VERSION ""

NS_ :

BS_:

BU_: SVB1 Tester Gateway CDS1 CDS2 ADV IRC AVP AVM PDC ADB1 ADB2 HDMAP DSM Fradar LCDA1 LCDA2

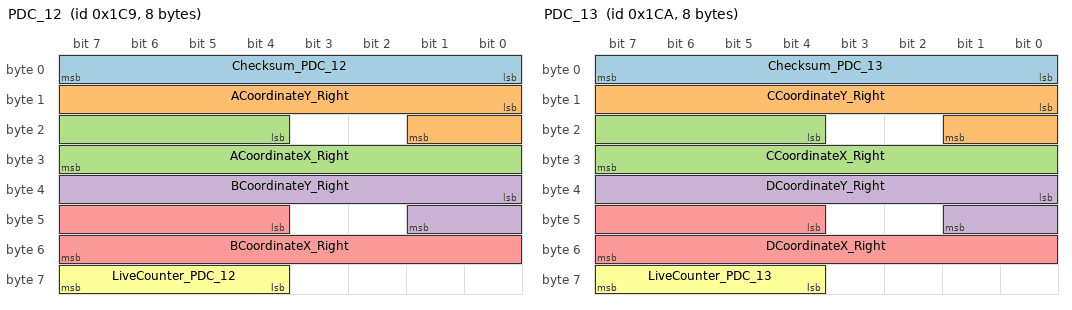
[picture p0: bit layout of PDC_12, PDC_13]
BO_ 457 PDC_12: 8 PDC
 SG_ Checksum_PDC_12 : 0|8@1+ (1,0) [0|255] ""  ADV,AVP,AVM
 SG_ ACoordinateY_Right : 8|10@1+ (1,0) [0|1023] "cm"  ADV,AVP,AVM
 SG_ ACoordinateX_Right : 20|12@1+ (1,0) [0|4095] "cm"  ADV,AVP,AVM
 SG_ BCoordinateY_Right : 32|10@1+ (1,0) [0|1023] "cm"  ADV,AVP,AVM
 SG_ BCoordinateX_Right : 44|12@1+ (1,0) [0|4095] "cm"  ADV,AVP,AVM
 SG_ LiveCounter_PDC_12 : 60|4@1+ (1,0) [0|15] "Pulse"  ADV,AVP,AVM

BO_ 458 PDC_13: 8 PDC
 SG_ Checksum_PDC_13 : 0|8@1+ (1,0) [0|255] ""  ADV,AVP,AVM
 SG_ CCoordinateY_Right : 8|10@1+ (1,0) [0|1023] "cm"  ADV,AVP,AVM
 SG_ CCoordinateX_Right : 20|12@1+ (1,0) [0|4095] "cm"  ADV,AVP,AVM
 SG_ DCoordinateY_Right : 32|10@1+ (1,0) [0|1023] "cm"  ADV,AVP,AVM
 SG_ DCoordinateX_Right : 44|12@1+ (1,0) [0|4095] "cm"  ADV,AVP,AVM
 SG_ LiveCounter_PDC_13 : 60|4@1+ (1,0) [0|15] "Pulse"  ADV,AVP,AVM

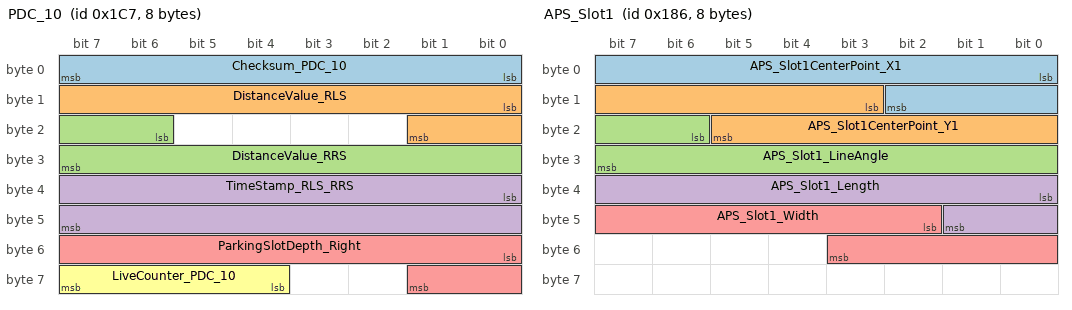
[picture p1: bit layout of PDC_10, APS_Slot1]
BO_ 455 PDC_10: 8 PDC
 SG_ Checksum_PDC_10 : 0|8@1+ (1,0) [0|255] ""  ADV,AVP,AVM
 SG_ DistanceValue_RLS : 8|10@1+ (1,0) [0|1023] "cm"  ADV,AVP,AVM
 SG_ DistanceValue_RRS : 22|10@1+ (1,0) [0|1023] "cm"  ADV,AVP,AVM
 SG_ TimeStamp_RLS_RRS : 32|16@1+ (1,0) [0|65535] "ms"  ADV,AVP,AVM
 SG_ ParkingSlotDepth_Right : 48|10@1+ (1,0) [0|1023] "cm"  AVP,AVM
 SG_ LiveCounter_PDC_10 : 60|4@1+ (1,0) [0|15] "Pulse"  ADV,AVP,AVM

BO_ 388 APS_PSD: 8 AVP
 SG_ APS_Slot1_DetectStatus : 0|2@1+ (1,0) [0|3] ""  Gateway,ADV
 SG_ APS_Slot1_Info : 2|2@1+ (1,0) [0|3] ""  Gateway,ADV
 SG_ APS_Slot1_ParkType : 4|2@1+ (1,0) [0|3] ""  Gateway,ADV
 SG_ APS_Slot1_ParkDirection : 6|1@1+ (1,0) [0|1] ""  Gateway,ADV
 SG_ APS_Slot2_DetectStatus : 8|2@1+ (1,0) [0|3] ""  Gateway,ADV
 SG_ APS_Slot2_Info : 10|2@1+ (1,0) [0|3] ""  Gateway,ADV
 SG_ APS_Slot2_ParkType : 12|2@1+ (1,0) [0|3] ""  Gateway,ADV
 SG_ APS_Slot2_ParkDirection : 14|1@1+ (1,0) [0|1] ""  Gateway,ADV
 SG_ APS_Slot3_DetectStatus : 16|2@1+ (1,0) [0|3] ""  Gateway,ADV
 SG_ APS_Slot3_Info : 18|2@1+ (1,0) [0|3] ""  Gateway,ADV
 SG_ APS_Slot3_ParkType : 20|2@1+ (1,0) [0|3] ""  Gateway,ADV
 SG_ APS_Slot3_ParkDirection : 22|1@1+ (1,0) [0|1] ""  Gateway,ADV
 SG_ APS_Slot4_DetectStatus : 24|2@1+ (1,0) [0|3] ""  Gateway,ADV
 SG_ APS_Slot4_Info : 26|2@1+ (1,0) [0|3] ""  Gateway,ADV
 SG_ APS_Slot4_ParkType : 28|2@1+ (1,0) [0|3] ""  Gateway,ADV
 SG_ APS_Slot4_ParkDirection : 30|1@1+ (1,0) [0|1] ""  Gateway,ADV
 SG_ APS_Slot5_DetectStatus : 32|2@1+ (1,0) [0|3] ""  Gateway,ADV
 SG_ APS_Slot5_Info : 34|2@1+ (1,0) [0|3] ""  Gateway,ADV
 SG_ APS_Slot5_ParkType : 36|2@1+ (1,0) [0|3] ""  Gateway,ADV
 SG_ APS_Slot5_ParkDirection : 38|1@1+ (1,0) [0|1] ""  Gateway,ADV
 SG_ APS_Slot6_DetectStatus : 40|2@1+ (1,0) [0|3] ""  Gateway,ADV
 SG_ APS_Slot6_Info : 42|2@1+ (1,0) [0|3] ""  Gateway,ADV
 SG_ APS_Slot6_ParkType : 44|2@1+ (1,0) [0|3] ""  Gateway,ADV
 SG_ APS_Slot6_ParkDirection : 46|1@1+ (1,0) [0|1] ""  Gateway,ADV
 SG_ APS_ParkingSlotAvailability : 63|1@1+ (1,0) [0|1] ""  Gateway,ADV

BO_ 390 APS_Slot1: 8 AVP
 SG_ APS_Slot1CenterPoint_X1 : 0|11@1+ (1,-1000) [-1000|1047] "cm"  Gateway,ADV
 SG_ APS_Slot1CenterPoint_Y1 : 11|11@1+ (1,-1000) [-1000|1047] "cm"  Gateway,ADV
 SG_ APS_Slot1_LineAngle : 22|10@1+ (1,0) [0|1023] "degree"  Gateway,ADV
 SG_ APS_Slot1_Length : 32|10@1+ (1,0) [0|1023] "cm"  Gateway,ADV
 SG_ APS_Slot1_Width : 42|10@1+ (1,0) [0|1023] "cm"  Gateway,ADV

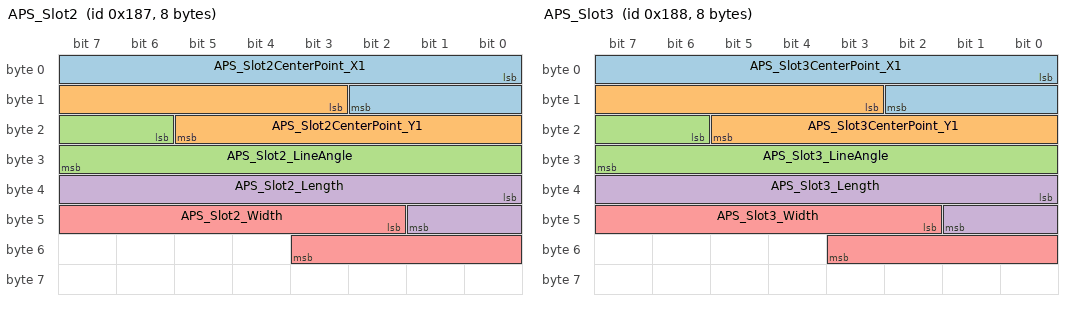
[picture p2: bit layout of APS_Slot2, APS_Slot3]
BO_ 391 APS_Slot2: 8 AVP
 SG_ APS_Slot2CenterPoint_X1 : 0|11@1+ (1,-1000) [-1000|1047] "cm"  Gateway,ADV
 SG_ APS_Slot2CenterPoint_Y1 : 11|11@1+ (1,-1000) [-1000|1047] "cm"  Gateway,ADV
 SG_ APS_Slot2_LineAngle : 22|10@1+ (1,0) [0|1023] "degree"  Gateway,ADV
 SG_ APS_Slot2_Length : 32|10@1+ (1,0) [0|1023] "cm"  Gateway,ADV
 SG_ APS_Slot2_Width : 42|10@1+ (1,0) [0|1023] "cm"  Gateway,ADV

BO_ 392 APS_Slot3: 8 AVP
 SG_ APS_Slot3CenterPoint_X1 : 0|11@1+ (1,-1000) [-1000|1047] "cm"  Gateway,ADV
 SG_ APS_Slot3CenterPoint_Y1 : 11|11@1+ (1,-1000) [-1000|1047] "cm"  Gateway,ADV
 SG_ APS_Slot3_LineAngle : 22|10@1+ (1,0) [0|1023] "degree"  Gateway,ADV
 SG_ APS_Slot3_Length : 32|10@1+ (1,0) [0|1023] "cm"  Gateway,ADV
 SG_ APS_Slot3_Width : 42|10@1+ (1,0) [0|1023] "cm"  Gateway,ADV

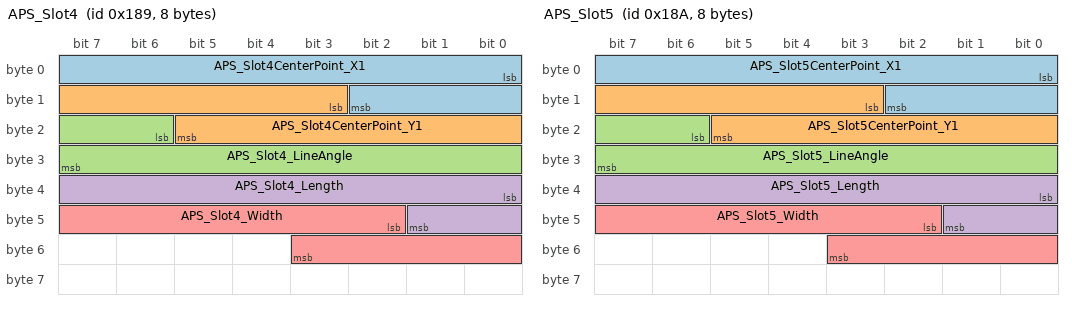
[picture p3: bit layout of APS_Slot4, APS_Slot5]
BO_ 393 APS_Slot4: 8 AVP
 SG_ APS_Slot4CenterPoint_X1 : 0|11@1+ (1,-1000) [-1000|1047] "cm"  Gateway,ADV
 SG_ APS_Slot4CenterPoint_Y1 : 11|11@1+ (1,-1000) [-1000|1047] "cm"  Gateway,ADV
 SG_ APS_Slot4_LineAngle : 22|10@1+ (1,0) [0|1023] "degree"  Gateway,ADV
 SG_ APS_Slot4_Length : 32|10@1+ (1,0) [0|1023] "cm"  Gateway,ADV
 SG_ APS_Slot4_Width : 42|10@1+ (1,0) [0|1023] "cm"  Gateway,ADV

BO_ 394 APS_Slot5: 8 AVP
 SG_ APS_Slot5CenterPoint_X1 : 0|11@1+ (1,-1000) [-1000|1047] "cm"  Gateway,ADV
 SG_ APS_Slot5CenterPoint_Y1 : 11|11@1+ (1,-1000) [-1000|1047] "cm"  Gateway,ADV
 SG_ APS_Slot5_LineAngle : 22|10@1+ (1,0) [0|1023] "degree"  Gateway,ADV
 SG_ APS_Slot5_Length : 32|10@1+ (1,0) [0|1023] "cm"  Gateway,ADV
 SG_ APS_Slot5_Width : 42|10@1+ (1,0) [0|1023] "cm"  Gateway,ADV

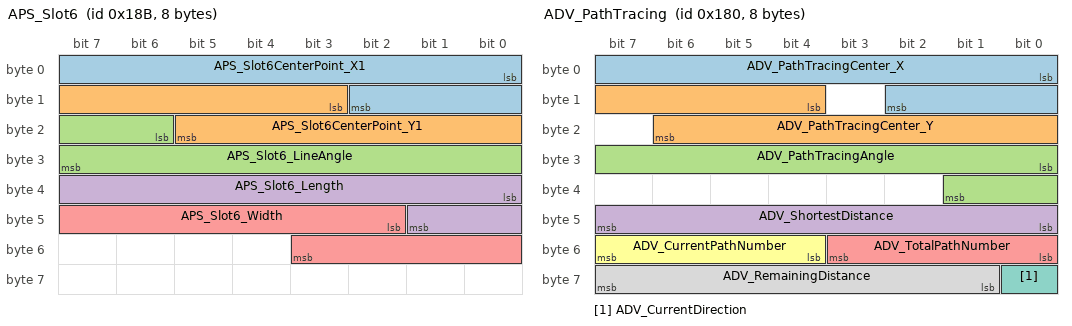
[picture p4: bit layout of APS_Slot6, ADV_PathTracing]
BO_ 395 APS_Slot6: 8 AVP
 SG_ APS_Slot6CenterPoint_X1 : 0|11@1+ (1,-1000) [-1000|1047] "cm"  Gateway,ADV
 SG_ APS_Slot6CenterPoint_Y1 : 11|11@1+ (1,-1000) [-1000|1047] "cm"  Gateway,ADV
 SG_ APS_Slot6_LineAngle : 22|10@1+ (1,0) [0|1023] "degree"  Gateway,ADV
 SG_ APS_Slot6_Length : 32|10@1+ (1,0) [0|1023] "cm"  Gateway,ADV
 SG_ APS_Slot6_Width : 42|10@1+ (1,0) [0|1023] "cm"  Gateway,ADV

BO_ 384 ADV_PathTracing: 8 CDS1
 SG_ ADV_PathTracingCenter_X : 0|11@1+ (1,-1000) [-1000|1047] "cm"  Gateway,AVP,AVM
 SG_ ADV_PathTracingCenter_Y : 12|11@1+ (1,-1000) [-1000|1047] "cm"  Gateway,AVP,AVM
 SG_ ADV_PathTracingAngle : 24|10@1+ (1,0) [0|1023] "degree"  Gateway,AVP,AVM
 SG_ ADV_ShortestDistance : 40|8@1+ (1,-126) [-126|129] "cm"  Gateway,AVP,AVM
 SG_ ADV_TotalPathNumber : 48|4@1+ (1,0) [0|15] ""  Gateway,AVP,AVM
 SG_ ADV_CurrentPathNumber : 52|4@1+ (1,0) [0|15] ""  Gateway,AVP,AVM
 SG_ ADV_CurrentDirection : 56|1@1+ (1,0) [0|1] ""  Gateway,AVP,AVM
 SG_ ADV_RemainingDistance : 57|7@1+ (1,0) [0|127] "%"  Gateway,AVP,AVM

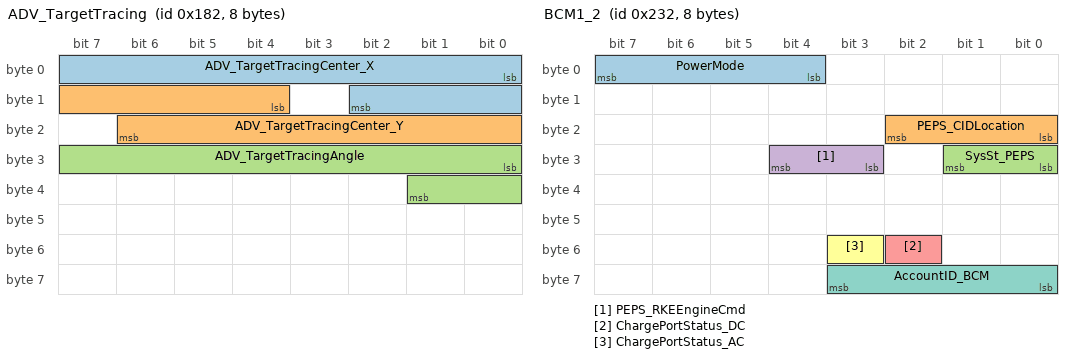
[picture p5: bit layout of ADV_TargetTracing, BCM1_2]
BO_ 386 ADV_TargetTracing: 8 CDS1
 SG_ ADV_TargetTracingCenter_X : 0|11@1+ (1,-1000) [-1000|1047] "cm"  Gateway,AVP,AVM
 SG_ ADV_TargetTracingCenter_Y : 12|11@1+ (1,-1000) [-1000|1047] "cm"  Gateway,AVP,AVM
 SG_ ADV_TargetTracingAngle : 24|10@1+ (1,0) [0|1023] "degree"  Gateway,AVP,AVM

BO_ 546 ATC_2: 8 Gateway
 SG_ AmbientTemp : 24|8@1+ (0.5,-40) [-40|87.5] "°„C"  SVB1,CDS1,CDS2,AVP,AVM,PDC

BO_ 560 BCM1_1: 8 Gateway
 SG_ PositionLightSt : 0|1@1+ (1,0) [0|1] ""  CDS2,SVB1,CDS1,ADV,IRC
 SG_ LowBeamSt : 6|1@1+ (1,0) [0|1] ""  SVB1,CDS1,CDS2,IRC,DSM
 SG_ LowBeamSt_FL : 7|1@1+ (1,0) [0|1] ""  CDS2,CDS1,SVB1,AVP,AVM,ADB1,ADB2
 SG_ LowBeamSt_FR : 8|1@1+ (1,0) [0|1] ""  CDS2,CDS1,SVB1,AVP,AVM,ADB1,ADB2
 SG_ HighBeamSt : 9|1@1+ (1,0) [0|1] ""  SVB1,CDS1,CDS2,IRC,DSM
 SG_ HighBeamSt_FL : 10|1@1+ (1,0) [0|1] ""  CDS2,CDS1,SVB1,AVP,AVM
 SG_ HighBeamSt_FR : 11|1@1+ (1,0) [0|1] ""  CDS2,CDS1,SVB1,AVP,AVM
 SG_ AutoLightMode : 12|1@1+ (1,0) [0|1] ""  SVB1,CDS1,CDS2,AVP,AVM,ADB1,ADB2
 SG_ TurningSt_Left : 16|1@1+ (1,0) [0|1] ""  SVB1,CDS1,CDS2,ADV,IRC,AVP,AVM,LCDA1,LCDA2
 SG_ TurningSt_right : 17|1@1+ (1,0) [0|1] ""  SVB1,CDS1,CDS2,ADV,IRC,AVP,AVM,LCDA1,LCDA2
 SG_ TurningLightCmd_Left : 18|1@1+ (1,0) [0|1] ""  CDS2,SVB1,CDS1,IRC,DSM
 SG_ TurningLightCmd_Right : 19|1@1+ (1,0) [0|1] ""  CDS2,SVB1,CDS1,IRC,DSM
 SG_ HazardWarningSt : 22|1@1+ (1,0) [0|1] ""  SVB1,CDS1,CDS2,ADV,AVP,AVM,DSM
 SG_ WMMFaultSt : 33|1@1+ (1,0) [0|1] ""  SVB1,CDS1,CDS2
 SG_ RLSFalutSt : 34|1@1+ (1,0) [0|1] ""  SVB1,CDS1,CDS2,ADB1,ADB2
 SG_ WiperSt_Front : 37|3@1+ (1,0) [0|7] ""  SVB1,CDS1,CDS2,IRC
 SG_ WiperSpeed_Front : 40|3@1+ (1,0) [0|7] ""  SVB1,CDS1,CDS2
 SG_ IHCConditionReady : 60|1@1+ (1,0) [0|1] ""  CDS1,SVB1,CDS2

BO_ 562 BCM1_2: 8 Gateway
 SG_ PowerMode : 4|4@1+ (1,0) [0|15] ""  SVB1,CDS1,CDS2,ADV,IRC,AVP,AVM,PDC,ADB1,ADB2,HDMAP,DSM,LCDA1,LCDA2
 SG_ PEPS_CIDLocation : 16|3@1+ (1,0) [0|7] ""  CDS2,SVB1,CDS1,ADV
 SG_ SysSt_PEPS : 24|2@1+ (1,0) [0|3] ""  CDS2,SVB1,CDS1,ADV
 SG_ PEPS_RKEEngineCmd : 27|2@1+ (1,0) [0|3] ""  CDS2,SVB1,CDS1,ADV
 SG_ ChargePortStatus_DC : 50|1@1+ (1,0) [0|1] ""  CDS2,SVB1,CDS1,ADV
 SG_ ChargePortStatus_AC : 51|1@1+ (1,0) [0|1] ""  CDS2,SVB1,CDS1,ADV
 SG_ AccountID_BCM : 56|4@1+ (1,0) [0|15] ""  CDS2,SVB1,CDS1,ADV

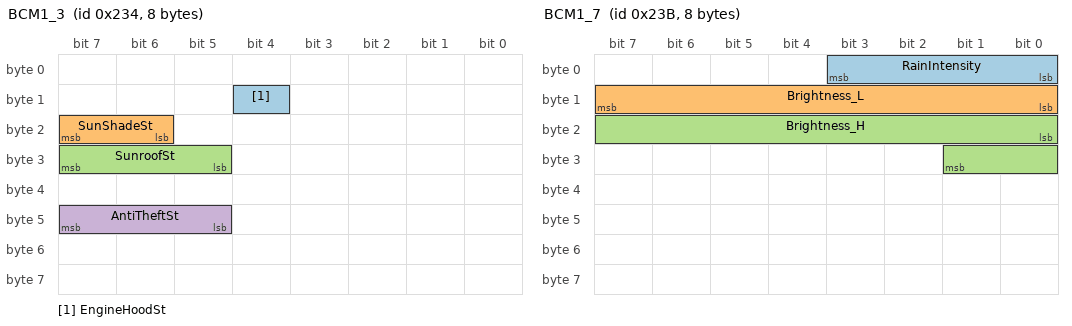
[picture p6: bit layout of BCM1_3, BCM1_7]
BO_ 564 BCM1_3: 8 Gateway
 SG_ EngineHoodSt : 12|1@1+ (1,0) [0|1] ""  SVB1,CDS1,CDS2,ADV,AVP,AVM
 SG_ SunShadeSt : 22|2@1+ (1,0) [0|3] ""  CDS2,CDS1,SVB1
 SG_ SunroofSt : 29|3@1+ (1,0) [0|7] ""  CDS2,SVB1,CDS1,ADV
 SG_ AntiTheftSt : 45|3@1+ (1,0) [0|7] ""  CDS2,SVB1,CDS1,LCDA1,LCDA2

BO_ 571 BCM1_7: 8 Gateway
 SG_ RainIntensity : 0|4@1+ (10,0) [0|150] "%"  SVB1,CDS1,CDS2,IRC,AVP,AVM,ADB1,ADB2
 SG_ Brightness_L : 8|8@1+ (400,0) [0|102000] "LUX"  SVB1,CDS1,CDS2,IRC,AVP,AVM,ADB1,ADB2
 SG_ Brightness_H : 16|10@1+ (6,0) [0|6138] "LUX"  SVB1,CDS1,CDS2,IRC,AVP,AVM,ADB1,ADB2

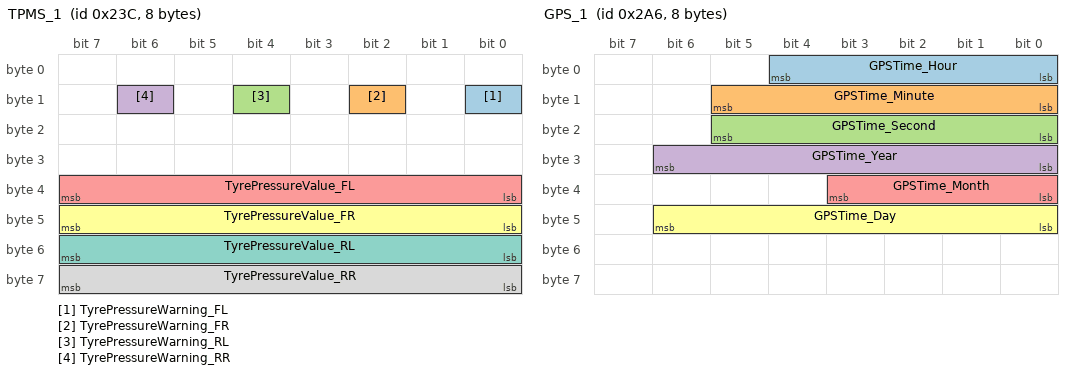
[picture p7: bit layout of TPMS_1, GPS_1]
BO_ 572 TPMS_1: 8 Gateway
 SG_ TyrePressureWarning_FL : 8|1@1+ (1,0) [0|1] ""  SVB1,CDS1,CDS2,ADV
 SG_ TyrePressureWarning_FR : 10|1@1+ (1,0) [0|1] ""  SVB1,CDS1,CDS2,ADV
 SG_ TyrePressureWarning_RL : 12|1@1+ (1,0) [0|1] ""  SVB1,CDS1,CDS2,ADV
 SG_ TyrePressureWarning_RR : 14|1@1+ (1,0) [0|1] ""  SVB1,CDS1,CDS2,ADV
 SG_ TyrePressureValue_FL : 32|8@1+ (2.75,0) [0|701.25] "kpa"  SVB1,CDS1,CDS2,ADV
 SG_ TyrePressureValue_FR : 40|8@1+ (2.75,0) [0|701.25] "kpa"  SVB1,CDS1,CDS2,ADV
 SG_ TyrePressureValue_RL : 48|8@1+ (2.75,0) [0|701.25] "kpa"  SVB1,CDS1,CDS2,ADV
 SG_ TyrePressureValue_RR : 56|8@1+ (2.75,0) [0|701.25] "kpa"  SVB1,CDS1,CDS2,ADV

BO_ 678 GPS_1: 8 Gateway
 SG_ GPSTime_Hour : 0|5@1+ (1,0) [0|31] "hour"  SVB1,CDS1,CDS2,ADV,AVP,AVM
 SG_ GPSTime_Minute : 8|6@1+ (1,0) [0|63] "minute"  SVB1,CDS1,CDS2,ADV,AVP,AVM
 SG_ GPSTime_Second : 16|6@1+ (1,0) [0|63] "minute"  SVB1,CDS1,CDS2,ADV,AVP,AVM
 SG_ GPSTime_Year : 24|7@1+ (1,2011) [2011|2138] "year"  SVB1,CDS1,CDS2,ADV,AVP,AVM
 SG_ GPSTime_Month : 32|4@1+ (1,1) [1|16] "month"  SVB1,CDS1,CDS2,ADV,AVP,AVM
 SG_ GPSTime_Day : 40|7@1+ (1,1) [1|128] "day"  SVB1,CDS1,CDS2,ADV,AVP,AVM

BO_ 691 GW_DataRecord: 8 Gateway
 SG_ GW_AutoDriveDataRecordStatus : 11|2@1+ (1,0) [0|3] ""  SVB1,CDS2,CDS1
 SG_ GW_AutoDriveDataRecordAvailable : 13|1@1+ (1,0) [0|1] ""  SVB1,CDS2,CDS1

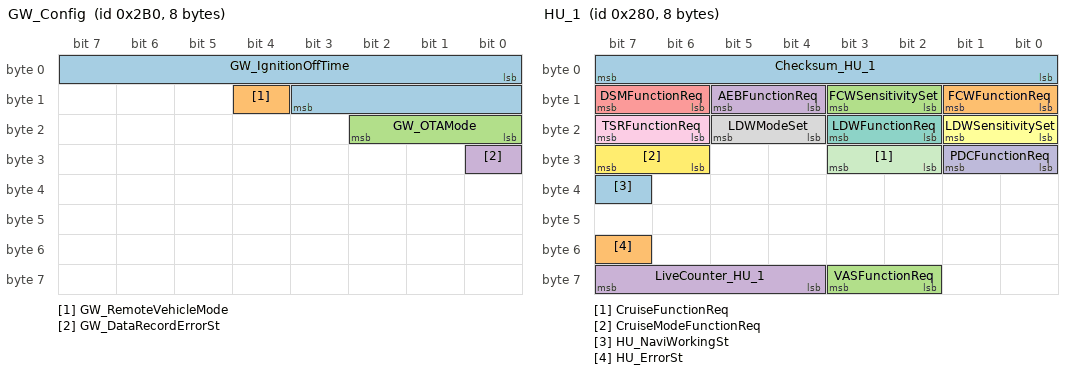
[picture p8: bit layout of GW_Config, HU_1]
BO_ 688 GW_Config: 8 Gateway
 SG_ GW_IgnitionOffTime : 0|12@1+ (1,0) [0|4095] "minute"  CDS2,CDS1,SVB1
 SG_ GW_RemoteVehicleMode : 12|1@1+ (1,0) [0|1] ""  SVB1,CDS1,CDS2,ADV,IRC,AVP,AVM,PDC,HDMAP,DSM
 SG_ GW_OTAMode : 16|3@1+ (1,0) [0|7] ""  SVB1,CDS1,CDS2,ADV,IRC,AVP,AVM,PDC,ADB1,ADB2,HDMAP,DSM,Fradar,LCDA1,LCDA2
 SG_ GW_DataRecordErrorSt : 24|1@1+ (1,0) [0|1] ""  CDS2,SVB1,CDS1

BO_ 640 HU_1: 8 Gateway
 SG_ Checksum_HU_1 : 0|8@1+ (1,0) [0|255] "Pulse"  SVB1,CDS1,CDS2,PDC,DSM
 SG_ FCWFunctionReq : 8|2@1+ (1,0) [0|3] ""  SVB1,CDS1,CDS2
 SG_ FCWSensitivitySet : 10|2@1+ (1,0) [0|3] ""  SVB1,CDS1,CDS2
 SG_ AEBFunctionReq : 12|2@1+ (1,0) [0|3] ""  SVB1,CDS1,CDS2
 SG_ DSMFunctionReq : 14|2@1+ (1,0) [0|3] ""  CDS1,SVB1,CDS2,DSM
 SG_ LDWSensitivitySet : 16|2@1+ (1,0) [0|3] ""  SVB1,CDS1,CDS2
 SG_ LDWFunctionReq : 18|2@1+ (1,0) [0|3] ""  SVB1,CDS1,CDS2
 SG_ LDWModeSet : 20|2@1+ (1,0) [0|3] ""  SVB1,CDS1,CDS2
 SG_ TSRFunctionReq : 22|2@1+ (1,0) [0|3] ""  SVB1,CDS1,CDS2
 SG_ PDCFunctionReq : 24|2@1+ (1,0) [0|3] ""  CDS2,CDS1,SVB1,PDC
 SG_ CruiseFunctionReq : 26|2@1+ (1,0) [0|3] ""  SVB1,CDS1,CDS2
 SG_ CruiseModeFunctionReq : 30|2@1+ (1,0) [0|3] ""  SVB1,CDS1,CDS2
 SG_ HU_NaviWorkingSt : 39|1@1+ (1,0) [0|1] ""  CDS2,SVB1,CDS1
 SG_ HU_ErrorSt : 55|1@1+ (1,0) [0|1] ""  CDS2,SVB1,CDS1
 SG_ VASFunctionReq : 58|2@1+ (1,0) [0|3] ""  SVB1,CDS1,CDS2
 SG_ LiveCounter_HU_1 : 60|4@1+ (1,0) [0|15] ""  SVB1,CDS1,CDS2,PDC,DSM

BO_ 643 HU_18: 8 Gateway
 SG_ Checksum_HU_18 : 0|8@1+ (1,0) [0|255] "Pulse"  ADV,AVP,AVM,PDC,DSM
 SG_ HU_BlindSpotFilledFunctionReq : 8|2@1+ (1,0) [0|3] ""  AVP,AVM
 SG_ HU_BacktrackFunctionReq : 10|2@1+ (1,0) [0|3] ""  ADV
 SG_ HU_ParkingAEBFunctionReq : 12|2@1+ (1,0) [0|3] "" Vector__XXX
 SG_ HU_ADVDisclaimerTipConfirm : 14|2@1+ (1,0) [0|3] "" Vector__XXX
 SG_ HU_APASuspendRequest : 16|2@1+ (1,0) [0|3] ""  ADV
 SG_ HU_PDCAutoOnFunctionReq : 18|2@1+ (1,0) [0|3] ""  PDC
 SG_ HU_FaceID_IVI : 20|4@1+ (1,0) [0|15] ""  DSM
 SG_ FaceIDBindFaceReq : 24|2@1+ (1,0) [0|3] ""  DSM
 SG_ HU_AVPSuspendRequest : 26|2@1+ (1,0) [0|3] "" Vector__XXX
 SG_ HU_HPASuspendRequest : 28|2@1+ (1,0) [0|3] "" Vector__XXX
 SG_ HU_AVPParkingLotPushFunctionReq : 30|2@1+ (1,0) [0|3] "" Vector__XXX
 SG_ HU_HPAFunctionReq : 32|2@1+ (1,0) [0|3] "" Vector__XXX
 SG_ HU_AVPHazardWarningFunctionReq : 34|2@1+ (1,0) [0|3] "" Vector__XXX
 SG_ HU_HPAHazardWarningFunctionReq : 36|2@1+ (1,0) [0|3] "" Vector__XXX
 SG_ HU_AVPTypeReq : 38|2@1+ (1,0) [0|3] "" Vector__XXX
 SG_ HU_AVPSearchingTypeReq : 40|2@1+ (1,0) [0|3] "" Vector__XXX
 SG_ HU_HPATypeReq : 42|2@1+ (1,0) [0|3] "" Vector__XXX
 SG_ HU_HPASearchingTypeReq : 44|2@1+ (1,0) [0|3] "" Vector__XXX
 SG_ HU_HPAParkingLotPushFunctionReq : 46|2@1+ (1,0) [0|3] "" Vector__XXX
 SG_ HU_AVPFunctionTipConfirm : 48|2@1+ (1,0) [0|3] "" Vector__XXX
 SG_ HU_HPAFunctionTipConfirm : 50|2@1+ (1,0) [0|3] "" Vector__XXX
 SG_ HU_AVPFunctionCancelReq : 52|1@1+ (1,0) [0|1] "" Vector__XXX
 SG_ HU_HPAFunctionCancelReq : 53|1@1+ (1,0) [0|1] "" Vector__XXX
 SG_ HU_AutoDrivingStyle_Set : 56|3@1+ (1,0) [0|7] "" Vector__XXX
 SG_ LiveCounter_HU_18 : 60|4@1+ (1,0) [0|15] "pulse"  ADV,AVP,AVM,PDC,DSM

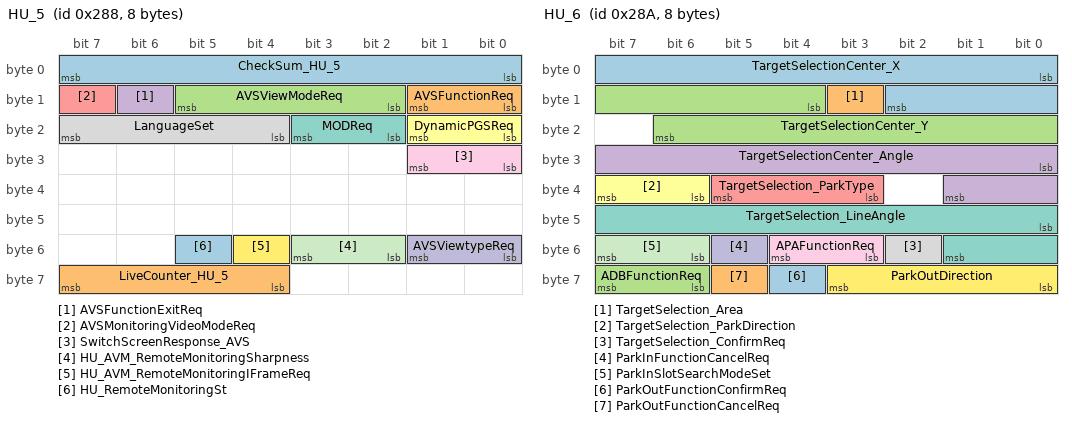
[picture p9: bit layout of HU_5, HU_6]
BO_ 648 HU_5: 8 Gateway
 SG_ CheckSum_HU_5 : 0|8@1+ (1,0) [0|255] ""  AVP,AVM
 SG_ AVSFunctionReq : 8|2@1+ (1,0) [0|3] ""  AVP,AVM
 SG_ AVSViewModeReq : 10|4@1+ (1,0) [0|15] ""  AVP,AVM
 SG_ AVSFunctionExitReq : 14|1@1+ (1,0) [0|1] ""  AVP,AVM
 SG_ AVSMonitoringVideoModeReq : 15|1@1+ (1,0) [0|1] ""  AVP,AVM
 SG_ DynamicPGSReq : 16|2@1+ (1,0) [0|3] ""  AVP,AVM
 SG_ MODReq : 18|2@1+ (1,0) [0|3] ""  AVP,AVM
 SG_ LanguageSet : 20|4@1+ (1,0) [0|15] ""  AVP,AVM
 SG_ SwitchScreenResponse_AVS : 24|2@1+ (1,0) [0|3] ""  AVP,AVM
 SG_ AVSViewtypeReq : 48|2@1+ (1,0) [0|3] ""  AVP,AVM
 SG_ HU_AVM_RemoteMonitoringSharpness : 50|2@1+ (1,0) [0|3] ""  AVP,AVM
 SG_ HU_AVM_RemoteMonitoringIFrameReq : 52|1@1+ (1,0) [0|1] ""  AVP,AVM
 SG_ HU_RemoteMonitoringSt : 53|1@1+ (1,0) [0|1] ""  AVP,AVM
 SG_ LiveCounter_HU_5 : 60|4@1+ (1,0) [0|15] "pulse"  AVP,AVM

BO_ 650 HU_6: 8 Gateway
 SG_ TargetSelectionCenter_X : 0|11@1+ (1,-1000) [-1000|1047] "cm"  ADV,AVP,AVM
 SG_ TargetSelection_Area : 11|1@1+ (1,0) [0|1] ""  ADV,AVP,AVM
 SG_ TargetSelectionCenter_Y : 12|11@1+ (1,-1000) [-1000|1047] "cm"  ADV,AVP,AVM
 SG_ TargetSelectionCenter_Angle : 24|10@1+ (1,0) [0|1023] "degree"  ADV,AVP,AVM
 SG_ TargetSelection_ParkType : 35|3@1+ (1,0) [0|7] ""  ADV,AVP,AVM
 SG_ TargetSelection_ParkDirection : 38|2@1+ (1,0) [0|3] ""  ADV,AVP,AVM
 SG_ TargetSelection_LineAngle : 40|10@1+ (1,0) [0|1023] "degree"  ADV,AVP,AVM
 SG_ TargetSelection_ConfirmReq : 50|1@1+ (1,0) [0|1] ""  ADV,AVP,AVM
 SG_ APAFunctionReq : 51|2@1+ (1,0) [0|3] ""  ADV
 SG_ ParkInFunctionCancelReq : 53|1@1+ (1,0) [0|1] ""  ADV
 SG_ ParkInSlotSearchModeSet : 54|2@1+ (1,0) [0|3] ""  ADV,AVP,AVM
 SG_ ParkOutDirection : 56|4@1+ (1,0) [0|15] ""  ADV,AVP,AVM
 SG_ ParkOutFunctionConfirmReq : 60|1@1+ (1,0) [0|1] ""  ADV
 SG_ ParkOutFunctionCancelReq : 61|1@1+ (1,0) [0|1] ""  ADV
 SG_ ADBFunctionReq : 62|2@1+ (1,0) [0|3] ""  ADB1,ADB2

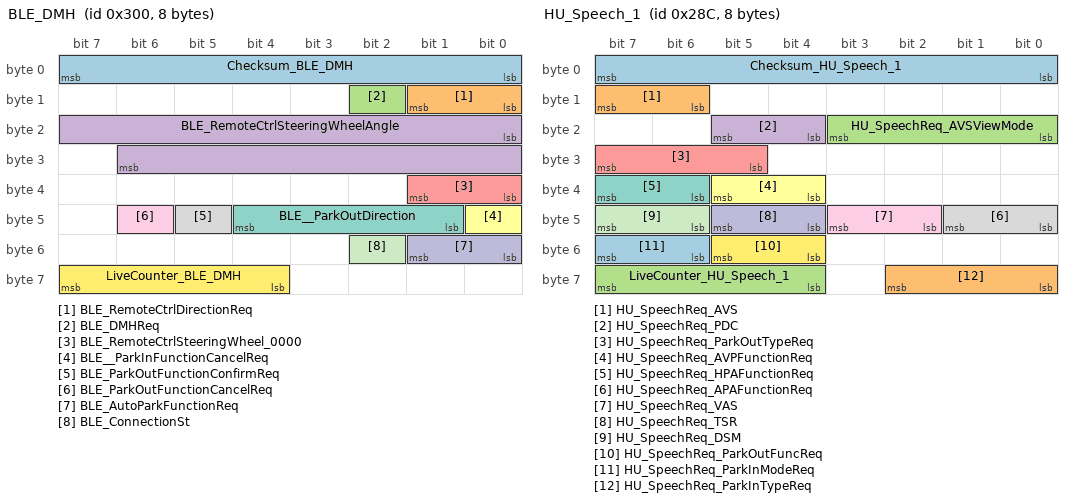
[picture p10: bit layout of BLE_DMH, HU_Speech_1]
BO_ 768 BLE_DMH: 8 Gateway
 SG_ Checksum_BLE_DMH : 0|8@1+ (1,0) [0|255] ""  ADV
 SG_ BLE_RemoteCtrlDirectionReq : 8|2@1+ (1,0) [0|3] ""  ADV
 SG_ BLE_DMHReq : 10|1@1+ (1,0) [0|1] ""  ADV
 SG_ BLE_RemoteCtrlSteeringWheelAngle : 16|15@1+ (0.04375,0) [0|1433.55625] "°„"  ADV
 SG_ BLE_RemoteCtrlSteeringWheel_0000 : 32|2@1+ (1,0) [0|3] ""  ADV
 SG_ BLE__ParkInFunctionCancelReq : 40|1@1+ (1,0) [0|1] ""  ADV
 SG_ BLE__ParkOutDirection : 41|4@1+ (1,0) [0|15] ""  ADV
 SG_ BLE_ParkOutFunctionConfirmReq : 45|1@1+ (1,0) [0|1] ""  ADV
 SG_ BLE_ParkOutFunctionCancelReq : 46|1@1+ (1,0) [0|1] ""  ADV
 SG_ BLE_AutoParkFunctionReq : 48|2@1+ (1,0) [0|3] ""  ADV
 SG_ BLE_ConnectionSt : 50|1@1+ (1,0) [0|1] ""  ADV
 SG_ LiveCounter_BLE_DMH : 60|4@1+ (1,0) [0|15] ""  ADV

BO_ 652 HU_Speech_1: 8 Gateway
 SG_ Checksum_HU_Speech_1 : 0|8@1+ (1,0) [0|255] ""  ADV,AVP,AVM,PDC
 SG_ HU_SpeechReq_AVS : 14|2@1+ (1,0) [0|3] ""  AVP,AVM
 SG_ HU_SpeechReq_AVSViewMode : 16|4@1+ (1,0) [0|15] ""  AVP,AVM
 SG_ HU_SpeechReq_PDC : 20|2@1+ (1,0) [0|3] ""  PDC
 SG_ HU_SpeechReq_ParkOutTypeReq : 29|3@1+ (1,0) [0|7] ""  ADV
 SG_ HU_SpeechReq_AVPFunctionReq : 36|2@1+ (1,0) [0|3] "" Vector__XXX
 SG_ HU_SpeechReq_HPAFunctionReq : 38|2@1+ (1,0) [0|3] "" Vector__XXX
 SG_ HU_SpeechReq_APAFunctionReq : 40|2@1+ (1,0) [0|3] ""  ADV
 SG_ HU_SpeechReq_VAS : 42|2@1+ (1,0) [0|3] "" Vector__XXX
 SG_ HU_SpeechReq_TSR : 44|2@1+ (1,0) [0|3] "" Vector__XXX
 SG_ HU_SpeechReq_DSM : 46|2@1+ (1,0) [0|3] ""  DSM
 SG_ HU_SpeechReq_ParkOutFuncReq : 52|2@1+ (1,0) [0|3] ""  ADV
 SG_ HU_SpeechReq_ParkInModeReq : 54|2@1+ (1,0) [0|3] ""  ADV
 SG_ HU_SpeechReq_ParkInTypeReq : 56|3@1+ (1,0) [0|7] ""  ADV
 SG_ LiveCounter_HU_Speech_1 : 60|4@1+ (1,0) [0|15] "Pulse"  ADV,AVP,AVM,PDC

BO_ 656 IC_1: 8 Gateway
 SG_ IndicationSpeed_IC : 8|8@1+ (1,0) [0|255] "km/h"  SVB1,CDS1,CDS2
 SG_ OdometerValue : 24|25@1+ (0.1,0) [0|3355443.1] "km"  SVB1,CDS1,CDS2,ADV,IRC,AVP,AVM,PDC,ADB1,ADB2,HDMAP,DSM,Fradar,LCDA1,LCDA2

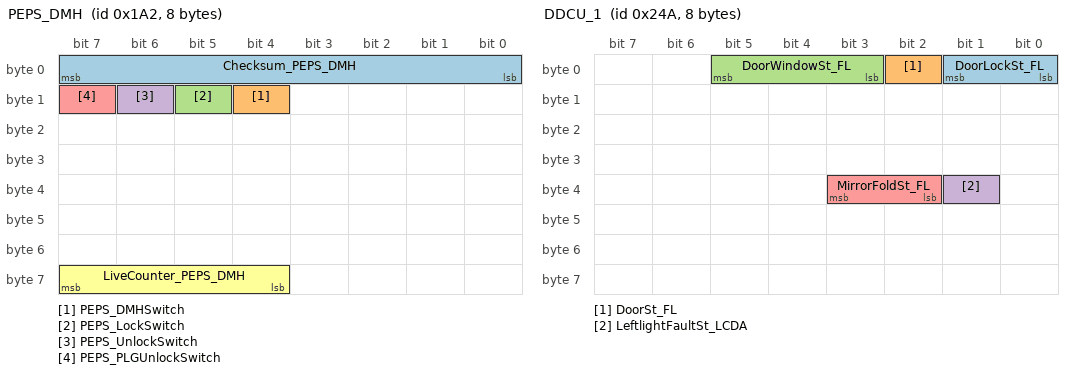
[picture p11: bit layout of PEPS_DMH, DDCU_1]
BO_ 418 PEPS_DMH: 8 Gateway
 SG_ Checksum_PEPS_DMH : 0|8@1+ (1,0) [0|255] ""  SVB1,CDS2,CDS1,ADV
 SG_ PEPS_DMHSwitch : 12|1@1+ (1,0) [0|1] ""  SVB1,CDS2,CDS1,ADV
 SG_ PEPS_LockSwitch : 13|1@1+ (1,0) [0|1] ""  SVB1,CDS2,CDS1,ADV
 SG_ PEPS_UnlockSwitch : 14|1@1+ (1,0) [0|1] ""  SVB1,CDS2,CDS1,ADV
 SG_ PEPS_PLGUnlockSwitch : 15|1@1+ (1,0) [0|1] ""  SVB1,CDS2,CDS1,ADV
 SG_ LiveCounter_PEPS_DMH : 60|4@1+ (1,0) [0|15] ""  SVB1,CDS2,CDS1,ADV

BO_ 578 PLG_1: 8 Gateway
 SG_ LuggageDoorSt : 0|1@1+ (1,0) [0|1] ""  SVB1,CDS2,CDS1,ADV,IRC,AVP,AVM

BO_ 586 DDCU_1: 8 Gateway
 SG_ DoorLockSt_FL : 0|2@1+ (1,0) [0|3] ""  CDS2,SVB1,CDS1,ADV,LCDA2
 SG_ DoorSt_FL : 2|1@1+ (1,0) [0|1] ""  SVB1,CDS1,CDS2,ADV,AVP,AVM,LCDA2
 SG_ DoorWindowSt_FL : 3|3@1+ (1,0) [0|7] ""  CDS2,SVB1,CDS1,ADV
 SG_ LeftlightFaultSt_LCDA : 33|1@1+ (1,0) [0|1] ""  CDS1,CDS2,SVB1,LCDA2
 SG_ MirrorFoldSt_FL : 34|2@1+ (1,0) [0|3] ""  CDS2,SVB1,CDS1,ADV,AVP,AVM

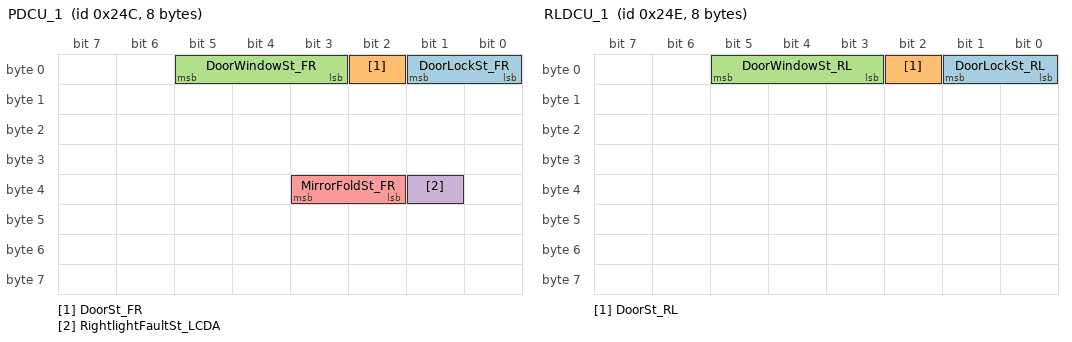
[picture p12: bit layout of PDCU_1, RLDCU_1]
BO_ 588 PDCU_1: 8 Gateway
 SG_ DoorLockSt_FR : 0|2@1+ (1,0) [0|3] ""  CDS2,SVB1,CDS1,ADV,LCDA1
 SG_ DoorSt_FR : 2|1@1+ (1,0) [0|1] ""  SVB1,CDS1,CDS2,ADV,AVP,AVM,LCDA1
 SG_ DoorWindowSt_FR : 3|3@1+ (1,0) [0|7] ""  CDS2,SVB1,CDS1,ADV
 SG_ RightlightFaultSt_LCDA : 33|1@1+ (1,0) [0|1] ""  CDS2,CDS1,SVB1,LCDA1
 SG_ MirrorFoldSt_FR : 34|2@1+ (1,0) [0|3] ""  CDS2,SVB1,CDS1,ADV,AVP,AVM

BO_ 590 RLDCU_1: 8 Gateway
 SG_ DoorLockSt_RL : 0|2@1+ (1,0) [0|3] ""  CDS2,SVB1,CDS1,ADV,LCDA2
 SG_ DoorSt_RL : 2|1@1+ (1,0) [0|1] ""  SVB1,CDS1,CDS2,ADV,AVP,AVM,LCDA2
 SG_ DoorWindowSt_RL : 3|3@1+ (1,0) [0|7] ""  CDS2,SVB1,CDS1,ADV

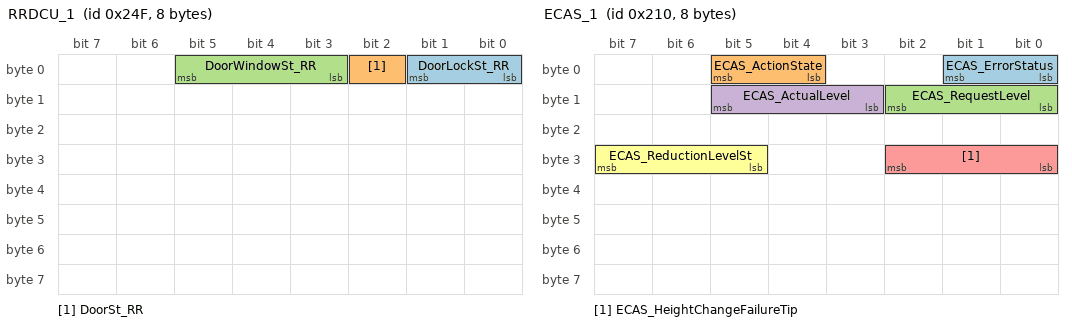
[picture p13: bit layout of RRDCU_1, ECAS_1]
BO_ 591 RRDCU_1: 8 Gateway
 SG_ DoorLockSt_RR : 0|2@1+ (1,0) [0|3] ""  CDS2,SVB1,CDS1,ADV,LCDA1
 SG_ DoorSt_RR : 2|1@1+ (1,0) [0|1] ""  SVB1,CDS1,CDS2,ADV,AVP,AVM,LCDA1
 SG_ DoorWindowSt_RR : 3|3@1+ (1,0) [0|7] ""  CDS2,SVB1,CDS1,ADV

BO_ 528 ECAS_1: 8 Gateway
 SG_ ECAS_ErrorStatus : 0|2@1+ (1,0) [0|3] ""  ADV
 SG_ ECAS_ActionState : 4|2@1+ (1,0) [0|3] ""  ADV,AVP,AVM
 SG_ ECAS_RequestLevel : 8|3@1+ (1,0) [0|7] ""  ADV
 SG_ ECAS_ActualLevel : 11|3@1+ (1,0) [0|7] ""  ADV,AVP,AVM
 SG_ ECAS_HeightChangeFailureTip : 24|3@1+ (1,0) [0|7] ""  ADV
 SG_ ECAS_ReductionLevelSt : 29|3@1+ (1,0) [0|7] ""  ADV

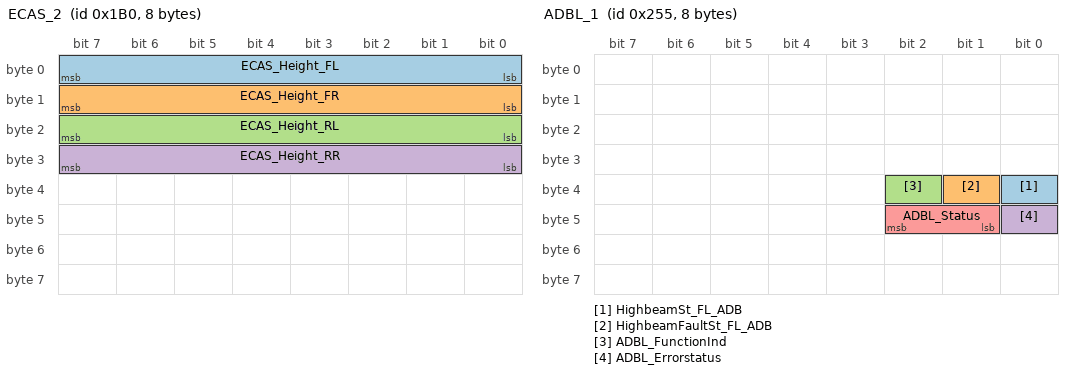
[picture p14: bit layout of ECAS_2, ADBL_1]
BO_ 432 ECAS_2: 8 Gateway
 SG_ ECAS_Height_FL : 0|8@1+ (1,-127) [-127|128] "mm"  ADV,AVP,AVM,PDC
 SG_ ECAS_Height_FR : 8|8@1+ (1,-127) [-127|128] "mm"  ADV,AVP,AVM,PDC
 SG_ ECAS_Height_RL : 16|8@1+ (1,-127) [-127|128] "mm"  ADV,AVP,AVM,PDC
 SG_ ECAS_Height_RR : 24|8@1+ (1,-127) [-127|128] "mm"  ADV,AVP,AVM,PDC

BO_ 529 ECAS_4: 8 Gateway
 SG_ AxleLoad_Front : 0|12@1+ (1,800) [800|4895] "kg" Vector__XXX
 SG_ AxleLoad_Rear : 12|12@1+ (1,800) [800|4895] "kg" Vector__XXX

BO_ 597 ADBL_1: 8 ADB1
 SG_ HighbeamSt_FL_ADB : 32|1@1+ (1,0) [0|1] ""  Gateway
 SG_ HighbeamFaultSt_FL_ADB : 33|1@1+ (1,0) [0|1] ""  Gateway
 SG_ ADBL_FunctionInd : 34|1@1+ (1,0) [0|1] ""  Gateway
 SG_ ADBL_Errorstatus : 40|1@1+ (1,0) [0|1] ""  Gateway,ADB2
 SG_ ADBL_Status : 41|2@1+ (1,0) [0|3] ""  Gateway

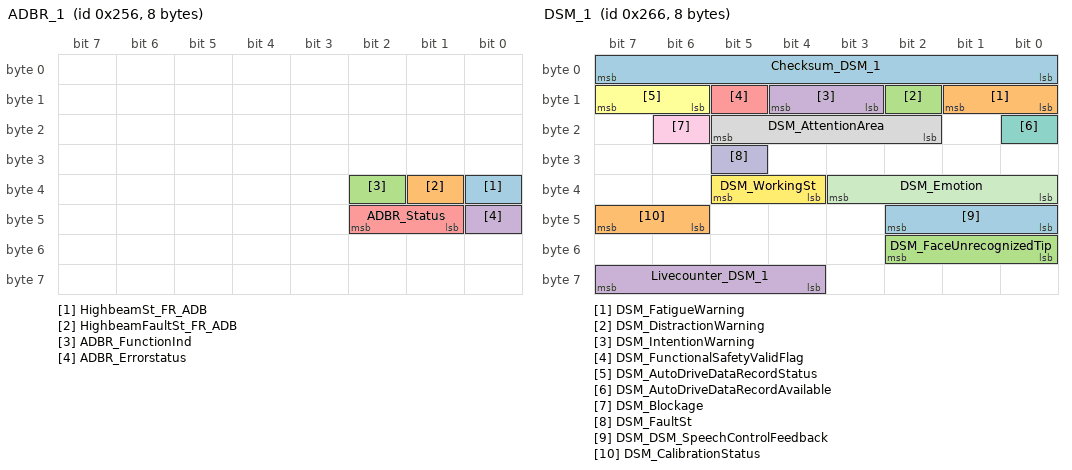
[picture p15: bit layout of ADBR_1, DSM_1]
BO_ 598 ADBR_1: 8 ADB2
 SG_ HighbeamSt_FR_ADB : 32|1@1+ (1,0) [0|1] "" Vector__XXX
 SG_ HighbeamFaultSt_FR_ADB : 33|1@1+ (1,0) [0|1] ""  Gateway
 SG_ ADBR_FunctionInd : 34|1@1+ (1,0) [0|1] ""  Gateway
 SG_ ADBR_Errorstatus : 40|1@1+ (1,0) [0|1] ""  Gateway,ADB1
 SG_ ADBR_Status : 41|2@1+ (1,0) [0|3] ""  Gateway

BO_ 539 MAP_1: 8 HDMAP
 SG_ HDMAP_Status : 32|2@1+ (1,0) [0|3] ""  AVP

BO_ 614 DSM_1: 8 DSM
 SG_ Checksum_DSM_1 : 0|8@1+ (1,0) [0|255] ""  SVB1,CDS2,Gateway,CDS1
 SG_ DSM_FatigueWarning : 8|2@1+ (1,0) [0|3] ""  SVB1,CDS2,Gateway,CDS1
 SG_ DSM_DistractionWarning : 10|1@1+ (1,0) [0|1] ""  SVB1,CDS2,Gateway,CDS1
 SG_ DSM_IntentionWarning : 11|2@1+ (1,0) [0|3] ""  SVB1,CDS2,Gateway,CDS1
 SG_ DSM_FunctionalSafetyValidFlag : 13|1@1+ (1,0) [0|1] ""  SVB1,CDS2,CDS1
 SG_ DSM_AutoDriveDataRecordStatus : 14|2@1+ (1,0) [0|3] ""  SVB1,CDS2,Gateway,CDS1
 SG_ DSM_AutoDriveDataRecordAvailable : 16|1@1+ (1,0) [0|1] ""  SVB1,CDS2,Gateway,CDS1
 SG_ DSM_AttentionArea : 18|4@1+ (1,0) [0|15] ""  SVB1,CDS2,CDS1
 SG_ DSM_Blockage : 22|1@1+ (1,0) [0|1] ""  SVB1,CDS2,Gateway,CDS1
 SG_ DSM_FaultSt : 29|1@1+ (1,0) [0|1] ""  SVB1,CDS2,Gateway,CDS1
 SG_ DSM_Emotion : 32|4@1+ (1,0) [0|15] ""  SVB1,CDS2,Gateway,CDS1
 SG_ DSM_WorkingSt : 36|2@1+ (1,0) [0|3] ""  SVB1,CDS2,CDS1,Gateway
 SG_ DSM_DSM_SpeechControlFeedback : 40|3@1+ (1,0) [0|7] ""  SVB1,CDS2,CDS1,Gateway
 SG_ DSM_CalibrationStatus : 46|2@1+ (1,0) [0|3] ""  SVB1,CDS2,CDS1,Gateway
 SG_ DSM_FaceUnrecognizedTip : 48|3@1+ (1,0) [0|7] ""  SVB1,CDS2,Gateway,CDS1
 SG_ Livecounter_DSM_1 : 60|4@1+ (1,0) [0|15] ""  SVB1,CDS2,Gateway,CDS1

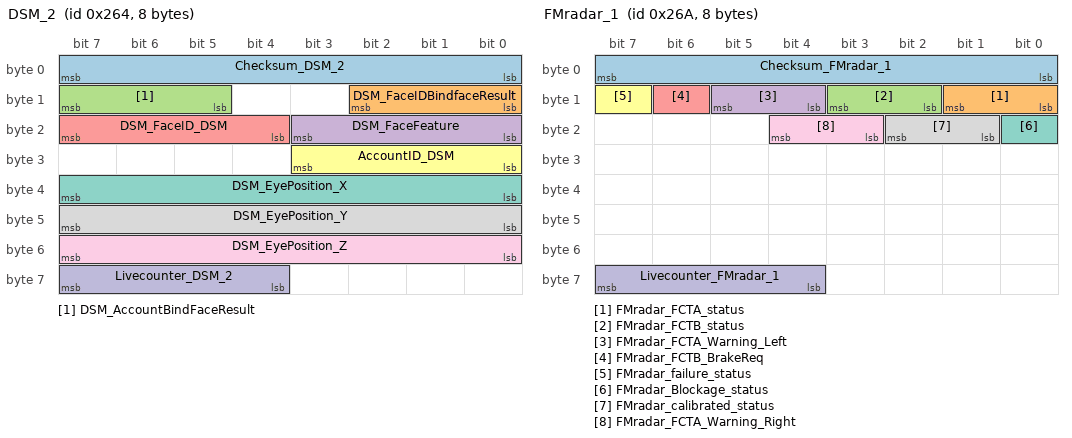
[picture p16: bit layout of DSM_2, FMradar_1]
BO_ 612 DSM_2: 8 DSM
 SG_ Checksum_DSM_2 : 0|8@1+ (1,0) [0|255] ""  SVB1,CDS2,CDS1,Gateway
 SG_ DSM_FaceIDBindfaceResult : 8|3@1+ (1,0) [0|7] ""  SVB1,CDS2,CDS1,Gateway
 SG_ DSM_AccountBindFaceResult : 13|3@1+ (1,0) [0|7] ""  SVB1,CDS2,CDS1,Gateway
 SG_ DSM_FaceFeature : 16|4@1+ (1,0) [0|15] ""  SVB1,CDS2,CDS1,Gateway
 SG_ DSM_FaceID_DSM : 20|4@1+ (1,0) [0|15] ""  SVB1,CDS2,CDS1,Gateway
 SG_ AccountID_DSM : 24|4@1+ (1,0) [0|15] ""  SVB1,CDS2,CDS1,Gateway
 SG_ DSM_EyePosition_X : 32|8@1+ (1,0) [0|255] "cm"  SVB1,CDS2,CDS1,Gateway
 SG_ DSM_EyePosition_Y : 40|8@1+ (1,0) [0|255] "cm"  SVB1,CDS2,CDS1,Gateway
 SG_ DSM_EyePosition_Z : 48|8@1+ (1,0) [0|255] "cm"  SVB1,CDS2,CDS1,Gateway
 SG_ Livecounter_DSM_2 : 60|4@1+ (1,0) [0|15] ""  SVB1,CDS2,CDS1,Gateway

BO_ 618 FMradar_1: 8 CDS1
 SG_ Checksum_FMradar_1 : 0|8@1+ (1,0) [0|255] ""  Gateway
 SG_ FMradar_FCTA_status : 8|2@1+ (1,0) [0|3] ""  Gateway
 SG_ FMradar_FCTB_status : 10|2@1+ (1,0) [0|3] ""  Gateway
 SG_ FMradar_FCTA_Warning_Left : 12|2@1+ (1,0) [0|3] ""  Gateway
 SG_ FMradar_FCTB_BrakeReq : 14|1@1+ (1,0) [0|1] ""  Gateway
 SG_ FMradar_failure_status : 15|1@1+ (1,0) [0|1] ""  Gateway
 SG_ FMradar_Blockage_status : 16|1@1+ (1,0) [0|1] ""  Gateway
 SG_ FMradar_calibrated_status : 17|2@1+ (1,0) [0|3] ""  Gateway
 SG_ FMradar_FCTA_Warning_Right : 19|2@1+ (1,0) [0|3] ""  Gateway
 SG_ Livecounter_FMradar_1 : 60|4@1+ (1,0) [0|15] ""  Gateway

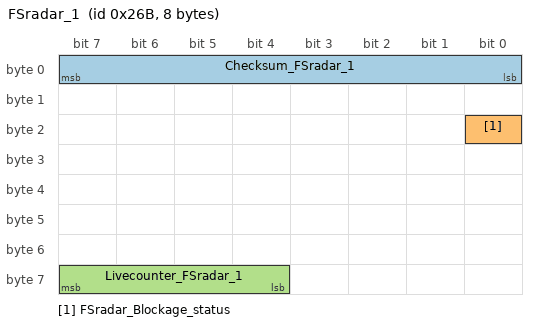
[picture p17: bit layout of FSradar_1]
BO_ 619 FSradar_1: 8 CDS1
 SG_ Checksum_FSradar_1 : 0|8@1+ (1,0) [0|255] ""  Gateway
 SG_ FSradar_Blockage_status : 16|1@1+ (1,0) [0|1] ""  Gateway
 SG_ Livecounter_FSradar_1 : 60|4@1+ (1,0) [0|15] ""  Gateway

BO_ 616 LCDA_1: 8 CDS1
 SG_ Checksum_LCDA_1 : 0|8@1+ (1,0) [0|255] ""  Gateway,AVP,AVM
 SG_ LCDA_ErrorSt_LCDA : 9|1@1+ (1,0) [0|1] ""  Gateway
 SG_ LCDA_WarningCmd_LCDA_Left : 10|2@1+ (1,0) [0|3] ""  Gateway
 SG_ LCDA_WarningCmd_LCDA_Right : 12|2@1+ (1,0) [0|3] ""  Gateway
 SG_ LCDA_WorkingSt_RCW : 14|2@1+ (1,0) [0|3] ""  Gateway
 SG_ LCDA_WarningCmd_RCTA_left : 16|2@1+ (1,0) [0|3] ""  Gateway,AVP,AVM
 SG_ LCDA_BuzzerCmd_RCTA_left : 18|2@1+ (1,0) [0|3] ""  Gateway
 SG_ LCDA_WarningCmd_RCTA_Right : 20|2@1+ (1,0) [0|3] ""  Gateway,AVP,AVM
 SG_ LCDA_BuzzerCmd_RCTA_Right : 22|2@1+ (1,0) [0|3] ""  Gateway
 SG_ LCDA_WorkingSt_RCTA : 24|2@1+ (1,0) [0|3] ""  Gateway,AVP,AVM
 SG_ LCDA_WorkingSt_LCWBSD : 35|2@1+ (1,0) [0|3] ""  Gateway
 SG_ LCDA_WorkingSt_RCTABuzzer : 37|2@1+ (1,0) [0|3] ""  Gateway
 SG_ LCDA_WarningCmd_DOW_FL : 40|2@1+ (1,0) [0|3] ""  Gateway
 SG_ LCDA_WarningCmd_DOW_FR : 42|2@1+ (1,0) [0|3] ""  Gateway
 SG_ LCDA_WarningCmd_DOW_RL : 44|2@1+ (1,0) [0|3] ""  Gateway
 SG_ LCDA_WarningCmd_DOW_RR : 46|2@1+ (1,0) [0|3] ""  Gateway
 SG_ LCDA_WarningCmd_RCW : 49|2@1+ (1,0) [0|3] ""  Gateway
 SG_ LCDA_WorkingSt_DOW : 51|2@1+ (1,0) [0|3] ""  Gateway
 SG_ LCDA_Blockage_RR : 53|2@1+ (1,0) [0|1] ""  Gateway
 SG_ LCDA__BrakeReq_RCTB : 55|1@1+ (1,0) [0|1] ""  Gateway,AVP,AVM
 SG_ LCDA_WorkingSt_RCTB : 56|2@1+ (1,0) [0|3] ""  Gateway,AVP,AVM
 SG_ LCDA_MisAlign_status : 58|2@1+ (1,0) [0|3] ""  Gateway
 SG_ LiveCounter_LCDA_1 : 60|4@1+ (1,0) [0|15] "Pulse"  Gateway,AVP,AVM

BO_TX_BU_ 388 : AVM,AVP;
BO_TX_BU_ 390 : AVM,AVP;
BO_TX_BU_ 391 : AVM,AVP;
BO_TX_BU_ 392 : AVM,AVP;
BO_TX_BU_ 393 : AVM,AVP;
BO_TX_BU_ 394 : AVM,AVP;
BO_TX_BU_ 395 : AVM,AVP;
BO_TX_BU_ 384 : ADV,CDS1;
BO_TX_BU_ 386 : ADV,CDS1;
BO_TX_BU_ 616 : LCDA1,CDS1;
CM_ SG_ 457 Checksum_PDC_12 "The checksum is used to check whether the data from the CPU buffer are shifted without transmission errors to the CAN communication controller buffer and vice versa.";
CM_ SG_ 457 ACoordinateY_Right "This signal indicates the Y coordinate of parking cell point A.0x3FE means no object was detected.";
CM_ SG_ 457 ACoordinateX_Right "This signal indicates the X coordinate of parking cell point A.0xFFE means no object was detected.";
CM_ SG_ 457 BCoordinateY_Right "This signal indicates the Y coordinate of parking cell point B.0x3FE means no object was detected.";
CM_ SG_ 457 BCoordinateX_Right "This signal indicates the X coordinate of parking cell point B.0xFFE means no object was detected.";
CM_ SG_ 457 LiveCounter_PDC_12 "The Livecounter is used to check the signal consistency of the messages . If the signals are consecutive, the LiveCounter should also be sequential in the way 0, 1, 2 °≠15, 0, 1 °≠";
CM_ SG_ 458 Checksum_PDC_13 "The checksum is used to check whether the data from the CPU buffer are shifted without transmission errors to the CAN communication controller buffer and vice versa.";
CM_ SG_ 458 CCoordinateY_Right "This signal indicates the Y coordinate of parking cell point C.0x3FE means no object was detected.";
CM_ SG_ 458 CCoordinateX_Right "This signal indicates the X coordinate of parking cell point C.0xFFE means no object was detected.";
CM_ SG_ 458 DCoordinateY_Right "This signal indicates the Y coordinate of parking cell point D.0x3FE means no object was detected.";
CM_ SG_ 458 DCoordinateX_Right "This signal indicates the X coordinate of parking cell point D.0xFFE means no object was detected.";
CM_ SG_ 458 LiveCounter_PDC_13 "The Livecounter is used to check the signal consistency of the messages . If the signals are consecutive, the LiveCounter should also be sequential in the way 0, 1, 2 °≠15, 0, 1 °≠";
CM_ SG_ 455 Checksum_PDC_10 "The checksum is used to check whether the data from the CPU buffer are shifted without transmission errors to the CAN communication controller buffer and vice versa.";
CM_ SG_ 455 DistanceValue_RLS "This signal indicates the obstacle detection distance by rear left side radar.0x3FE means no object was detected.";
CM_ SG_ 455 DistanceValue_RRS "This signal indicates the obstacle detection distance by rear right side radar.0x3FE means no object was detected.";
CM_ SG_ 455 TimeStamp_RLS_RRS "This signal indicates the time stamp of the obstacle detection distance by rear left side and rear right side radar.";
CM_ SG_ 455 ParkingSlotDepth_Right "This signal indicates the right parking slot depth.0x3FE means no object was detected.";
CM_ SG_ 455 LiveCounter_PDC_10 "The Livecounter is used to check the signal consistency of the messages . If the signals are consecutive, the LiveCounter should also be sequential in the way 0, 1, 2 °≠15, 0, 1 °≠";
CM_ SG_ 388 APS_Slot1_DetectStatus "APS Slot1 DetectStatus";
CM_ SG_ 388 APS_Slot1_Info "APS Slot1 Info";
CM_ SG_ 388 APS_Slot1_ParkType "APS Slot1 Park Type";
CM_ SG_ 388 APS_Slot1_ParkDirection "APS Slot1 ParkDirection";
CM_ SG_ 388 APS_Slot2_DetectStatus "APS Slot2 DetectStatus";
CM_ SG_ 388 APS_Slot2_Info "APS Slot2 Info";
CM_ SG_ 388 APS_Slot2_ParkType "APS Slot2 Park Type";
CM_ SG_ 388 APS_Slot2_ParkDirection "APS Slot2 ParkDirection";
CM_ SG_ 388 APS_Slot3_DetectStatus "APS Slot3 DetectStatus";
CM_ SG_ 388 APS_Slot3_Info "APS Slot3 Info";
CM_ SG_ 388 APS_Slot3_ParkType "APS Slot3 Park Type";
CM_ SG_ 388 APS_Slot3_ParkDirection "APS Slot3 ParkDirection";
CM_ SG_ 388 APS_Slot4_DetectStatus "APS Slot4 DetectStatus";
CM_ SG_ 388 APS_Slot4_Info "APS Slot4 Info";
CM_ SG_ 388 APS_Slot4_ParkType "APS Slot4 Park Type";
CM_ SG_ 388 APS_Slot4_ParkDirection "APS Slot4 ParkDirection";
CM_ SG_ 388 APS_Slot5_DetectStatus "APS Slot5 DetectStatus";
CM_ SG_ 388 APS_Slot5_Info "APS Slot5 Info";
CM_ SG_ 388 APS_Slot5_ParkType "APS Slot5 Park Type";
CM_ SG_ 388 APS_Slot5_ParkDirection "APS Slot5 ParkDirection";
CM_ SG_ 388 APS_Slot6_DetectStatus "APS Slot6 DetectStatus";
CM_ SG_ 388 APS_Slot6_Info "APS Slot6 Info";
CM_ SG_ 388 APS_Slot6_ParkType "APS Slot6 Park Type";
CM_ SG_ 388 APS_Slot6_ParkDirection "APS Slot6 ParkDirection";
CM_ SG_ 388 APS_ParkingSlotAvailability "This signal indicates that availble parking slot exist or not";
CM_ SG_ 390 APS_Slot1CenterPoint_X1 "SlotCenterPoint X1";
CM_ SG_ 390 APS_Slot1CenterPoint_Y1 "SlotCenterPoint Y1";
CM_ SG_ 390 APS_Slot1_LineAngle "Line Angle";
CM_ SG_ 390 APS_Slot1_Length "Slot Length";
CM_ SG_ 390 APS_Slot1_Width "Slot Width";
CM_ SG_ 391 APS_Slot2CenterPoint_X1 "SlotCenterPoint X1";
CM_ SG_ 391 APS_Slot2CenterPoint_Y1 "SlotCenterPoint Y1";
CM_ SG_ 391 APS_Slot2_LineAngle "Line Angle";
CM_ SG_ 391 APS_Slot2_Length "Slot Length";
CM_ SG_ 391 APS_Slot2_Width "Slot Width";
CM_ SG_ 392 APS_Slot3CenterPoint_X1 "SlotCenterPoint X1";
CM_ SG_ 392 APS_Slot3CenterPoint_Y1 "SlotCenterPoint Y1";
CM_ SG_ 392 APS_Slot3_LineAngle "Line Angle";
CM_ SG_ 392 APS_Slot3_Length "Slot Length";
CM_ SG_ 392 APS_Slot3_Width "Slot Width";
CM_ SG_ 393 APS_Slot4CenterPoint_X1 "SlotCenterPoint X1";
CM_ SG_ 393 APS_Slot4CenterPoint_Y1 "SlotCenterPoint Y1";
CM_ SG_ 393 APS_Slot4_LineAngle "Line Angle";
CM_ SG_ 393 APS_Slot4_Length "Slot Length";
CM_ SG_ 393 APS_Slot4_Width "Slot Width";
CM_ SG_ 394 APS_Slot5CenterPoint_X1 "SlotCenterPoint X1";
CM_ SG_ 394 APS_Slot5CenterPoint_Y1 "SlotCenterPoint Y1";
CM_ SG_ 394 APS_Slot5_LineAngle "Line Angle";
CM_ SG_ 394 APS_Slot5_Length "Slot Length";
CM_ SG_ 394 APS_Slot5_Width "Slot Width";
CM_ SG_ 395 APS_Slot6CenterPoint_X1 "SlotCenterPoint X1";
CM_ SG_ 395 APS_Slot6CenterPoint_Y1 "SlotCenterPoint Y1";
CM_ SG_ 395 APS_Slot6_LineAngle "Line Angle";
CM_ SG_ 395 APS_Slot6_Length "Slot Length";
CM_ SG_ 395 APS_Slot6_Width "Slot Width";
CM_ SG_ 384 ADV_PathTracingCenter_X "Path Tracing Center X";
CM_ SG_ 384 ADV_PathTracingCenter_Y "Path Tracing Center Y";
CM_ SG_ 384 ADV_PathTracingAngle "Path Tracing Angle";
CM_ SG_ 384 ADV_ShortestDistance "The shortest distance";
CM_ SG_ 384 ADV_TotalPathNumber "Total Path Number";
CM_ SG_ 384 ADV_CurrentPathNumber "Current Path Number";
CM_ SG_ 384 ADV_CurrentDirection "CurrentDirection";
CM_ SG_ 384 ADV_RemainingDistance "RemainingDistance";
CM_ SG_ 386 ADV_TargetTracingCenter_X "Target Tracing Center X";
CM_ SG_ 386 ADV_TargetTracingCenter_Y "Target Tracing Center Y";
CM_ SG_ 386 ADV_TargetTracingAngle "Target Tracing Angle";
CM_ SG_ 546 AmbientTemp "The signal indicate ambient temperature.";
CM_ SG_ 560 PositionLightSt "The signal indicates the status of position light.";
CM_ SG_ 560 LowBeamSt "The signal  indicates the status of low beam indicator.";
CM_ SG_ 560 LowBeamSt_FL "The signal  indicates the status of front left low beam indicator.";
CM_ SG_ 560 LowBeamSt_FR "The signal  indicates the status of front right low beam indicator.";
CM_ SG_ 560 HighBeamSt "The signal  indicates the status of high beam indicator.";
CM_ SG_ 560 HighBeamSt_FL "The signal  indicates the status of front left high beam indicator.";
CM_ SG_ 560 HighBeamSt_FR "The signal  indicates the status of front right high beam indicator.";
CM_ SG_ 560 AutoLightMode "This signal shows light is in Automatic Mode.";
CM_ SG_ 560 TurningSt_Left "The signal indicates the driving status of the left turn light.";
CM_ SG_ 560 TurningSt_right "The signal indicates the driving status of the right turn light.";
CM_ SG_ 560 TurningLightCmd_Left "BCM1 control the flash frequency according to turn light error signal and turn light flash mode.";
CM_ SG_ 560 TurningLightCmd_Right "BCM1 control the flash frequency according to turn light error signal and turn light flash mode.";
CM_ SG_ 560 HazardWarningSt "The signal indicates Indicates the Hazard Warning is active or not";
CM_ SG_ 560 WMMFaultSt "This signal shows WMM (wiper controller module)  fault status. ";
CM_ SG_ 560 RLSFalutSt "This signal shows RLS (rain light sensor) fault status. ";
CM_ SG_ 560 WiperSt_Front "The signal indicates front wiper status.";
CM_ SG_ 560 WiperSpeed_Front "This signal informs about the wiper speed requested by the Sensor according to rain intensity or other factors";
CM_ SG_ 560 IHCConditionReady "The signal indicates if the IHC function is ready to work";
CM_ SG_ 562 PowerMode "The signal indicates the vehicle power mode.";
CM_ SG_ 562 PEPS_CIDLocation "Indicates the position of CID";
CM_ SG_ 562 SysSt_PEPS "The signal indicates PEPS related function is normal or not.";
CM_ SG_ 562 PEPS_RKEEngineCmd "Indicates the command by combined buttons operation on key. Pressing lock button for 1 time and DMH button for 2 times within 3 seconds, the vehicle would be started.  This signal is used only for HAD to park out automatically, not park in.";
CM_ SG_ 562 ChargePortStatus_DC "This signal shows DC charge port status.";
CM_ SG_ 562 ChargePortStatus_AC "This signal shows AC charge port status.";
CM_ SG_ 562 AccountID_BCM "This signal indicates the account ID.
0:Initial/No account identified 1~14:Account ID 15:Invalid value";
CM_ SG_ 564 EngineHoodSt "This signal shows engine hood status.";
CM_ SG_ 564 SunShadeSt "This signal shows sunshade status.";
CM_ SG_ 564 SunroofSt "This signal shows sunroof status.";
CM_ SG_ 564 AntiTheftSt "This signal indicates current anti-theft status.";
CM_ SG_ 571 RainIntensity "This signal delivers information about rain intensity: from 0% (no rain) to 100% (very heavy rain).";
CM_ SG_ 571 Brightness_L "This signal  indicate the low precision light intensity expressed in 8 Bit.";
CM_ SG_ 571 Brightness_H "This signal  indicate the high precision light intensity expressed in 10 Bit.";
CM_ SG_ 572 TyrePressureWarning_FL "This signal is send to IC to indicate the warning status of front left tyre pressure.";
CM_ SG_ 572 TyrePressureWarning_FR "This signal is send to IC to indicate the warning status of front right tyre pressure.";
CM_ SG_ 572 TyrePressureWarning_RL "This signal is send to IC to indicate the warning status of rear left tyre pressure.";
CM_ SG_ 572 TyrePressureWarning_RR "This signal is send to IC to indicate the warning status of rear right tyre pressure.";
CM_ SG_ 572 TyrePressureValue_FL "This signal  indicates the front left tyre pressure value.";
CM_ SG_ 572 TyrePressureValue_FR "This signal  indicates the front right tyre pressure value.";
CM_ SG_ 572 TyrePressureValue_RL "This signal  indicates the rear left tyre pressure value.";
CM_ SG_ 572 TyrePressureValue_RR "This signal  indicates the rear right tyre pressure value.";
CM_ SG_ 678 GPSTime_Hour "Indicates the GPS hour sent by GPS.";
CM_ SG_ 678 GPSTime_Minute "Indicates the GPS minute  sent by GPS.";
CM_ SG_ 678 GPSTime_Second "Indicates the GPS second sent by GPS.";
CM_ SG_ 678 GPSTime_Year "Indicates the GPS year sent by GPS.";
CM_ SG_ 678 GPSTime_Month "Indicates the GPS month sent by GPS.";
CM_ SG_ 678 GPSTime_Day "Indicates the GPS day sent by GPS.";
CM_ SG_ 691 GW_AutoDriveDataRecordStatus "GW automotive drive data recode status";
CM_ SG_ 691 GW_AutoDriveDataRecordAvailable "GW automotive drive data uplode available or not";
CM_ SG_ 688 GW_IgnitionOffTime "Indicates the time between last KL15 Off and this KL15 on. If the counter is overflow, it still sends 4093. The counter will be reset when KL15 Off";
CM_ SG_ 688 GW_RemoteVehicleMode "The signal indicates the vehicle is in remote  mode or not";
CM_ SG_ 688 GW_OTAMode "The signal indicates the vehicle is in OTA  mode or not";
CM_ SG_ 688 GW_DataRecordErrorSt "The signal indicates the error status ofdata record function";
CM_ SG_ 640 Checksum_HU_1 "The checksum is used to check whether the data from the CPU buffer are shifted without transmission errors to the CAN communication controller buffer and vice versa.";
CM_ SG_ 640 FCWFunctionReq "This signal is used to request FCW function on or Off.";
CM_ SG_ 640 FCWSensitivitySet "This signal is used for FCW sensitivity Setting.";
CM_ SG_ 640 AEBFunctionReq "This signal is used to request AEB function on or Off.";
CM_ SG_ 640 DSMFunctionReq "This signal is used to request DSM function on or Off.";
CM_ SG_ 640 LDWSensitivitySet "This signal is used for LDW sensitivity setting.";
CM_ SG_ 640 LDWFunctionReq "This signal is used to request LDW function on or off.";
CM_ SG_ 640 LDWModeSet "This signal is used to modify the configuration of LDW function.";
CM_ SG_ 640 TSRFunctionReq "This signal is used to modify the configuration of TSR function.";
CM_ SG_ 640 PDCFunctionReq "This signal is used to request PDC function on or off.";
CM_ SG_ 640 CruiseFunctionReq "This signal is used to request Cruise function on or off.";
CM_ SG_ 640 CruiseModeFunctionReq "This signal is used to modify the configuration of SACC or ACC function.,Signal Initial=last value";
CM_ SG_ 640 HU_NaviWorkingSt "This signal indicates the navigation working status.";
CM_ SG_ 640 HU_ErrorSt "This signal indicates the IVI system error status.";
CM_ SG_ 640 VASFunctionReq "This signal is used to modify the configuration of VAS(Vehicle Ahead Start) function.";
CM_ SG_ 640 LiveCounter_HU_1 "The Livecounter is used to check the signal consistency of the messages . If the signals are consecutive, the LiveCounter should also be sequential in the way 0, 1, 2 °≠15, 0, 1 °≠";
CM_ SG_ 643 Checksum_HU_18 "The checksum is used to check whether the data from the CPU buffer are shifted without transmission errors to the CAN communication controller buffer and vice versa.";
CM_ SG_ 643 HU_BlindSpotFilledFunctionReq "This signal indicate function of turn the blind spot fiiled function on or not";
CM_ SG_ 643 HU_BacktrackFunctionReq "This signal indicate function of turn the backtrack function on or not";
CM_ SG_ 643 HU_ParkingAEBFunctionReq "This signal indicate function of turn the parking AEB function on or not";
CM_ SG_ 643 HU_ADVDisclaimerTipConfirm "This signal indicate user confirm the ADV disclaimer tip.";
CM_ SG_ 643 HU_APASuspendRequest "This signal indicates the request to suspend or continue parking in/parking out.";
CM_ SG_ 643 HU_PDCAutoOnFunctionReq "This signal indicate function of turn the PDC auto on function on or not";
CM_ SG_ 643 HU_FaceID_IVI "The signal indicates the face ID from IVI.";
CM_ SG_ 643 FaceIDBindFaceReq "This signal is used to bind or unbind the face to face ID.";
CM_ SG_ 643 HU_AVPSuspendRequest "This signal indicates the request to suspend or continue parking in/parking out of AVP.";
CM_ SG_ 643 HU_HPASuspendRequest "This signal indicates the request to suspend or continue parking in/parking out of HPA.";
CM_ SG_ 643 HU_AVPParkingLotPushFunctionReq "This signal indicate function request of AVP parking lot push funtion.";
CM_ SG_ 643 HU_HPAFunctionReq "Turn HPA function on or off by IVI";
CM_ SG_ 643 HU_AVPHazardWarningFunctionReq "This signal indicate the request that if the hazard light always working when AVP active.";
CM_ SG_ 643 HU_HPAHazardWarningFunctionReq "This signal indicate the request that if the hazard light always working when HPA active.";
CM_ SG_ 643 HU_AVPTypeReq "This signal indicate the request of AVP type.";
CM_ SG_ 643 HU_AVPSearchingTypeReq "This signal indicate the request of AVP searching type.";
CM_ SG_ 643 HU_HPATypeReq "This signal indicate the request of HPA type.";
CM_ SG_ 643 HU_HPASearchingTypeReq "This signal indicate the request of HPA searching type.";
CM_ SG_ 643 HU_HPAParkingLotPushFunctionReq "This signal indicate function request of HPA parking lot push funtion.";
CM_ SG_ 643 HU_AVPFunctionTipConfirm "This signal indicate the driver confirm status of AVP function tip.";
CM_ SG_ 643 HU_HPAFunctionTipConfirm "This signal indicate the driver confirm status of HPA function tip.";
CM_ SG_ 643 HU_AVPFunctionCancelReq "AVP Function Cancel Request";
CM_ SG_ 643 HU_HPAFunctionCancelReq "HPA Function Cancel Request";
CM_ SG_ 643 HU_AutoDrivingStyle_Set "Driver can set the autodriving style by IVI.";
CM_ SG_ 643 LiveCounter_HU_18 "The Livecounter is used to check the signal consistency of the messages . If the signals are consecutive, the LiveCounter should also be sequential in the way 0, 1, 2 °≠15, 0, 1 °≠";
CM_ SG_ 648 CheckSum_HU_5 "The checksum is used to check whether the data from the CPU buffer are shifted without transmission errors to the CAN communication controller buffer and vice versa.";
CM_ SG_ 648 AVSFunctionReq "This signal is used to request AVS function on or off.";
CM_ SG_ 648 AVSViewModeReq "This signal is used to set AVS view mode.";
CM_ SG_ 648 AVSFunctionExitReq "AVS Function Exit Request";
CM_ SG_ 648 AVSMonitoringVideoModeReq "AVS remote monitoring Video mode Request";
CM_ SG_ 648 DynamicPGSReq "This signal is used to request dynamic PGS function.";
CM_ SG_ 648 MODReq "This signal is used to request MOD function.";
CM_ SG_ 648 LanguageSet "This signal Indicates the language setting.";
CM_ SG_ 648 SwitchScreenResponse_AVS "Head Unit response the switching screen request from AVS(Always happen when the switching screen command is not from IVI but from AVM in case of lever R,lever P or etc)";
CM_ SG_ 648 AVSViewtypeReq "This signal is used to request AVS View type";
CM_ SG_ 648 HU_AVM_RemoteMonitoringSharpness "Indicates the remote monitoring sharpness set command";
CM_ SG_ 648 HU_AVM_RemoteMonitoringIFrameReq "This signal is used to request AVM to re-translate the I-Frame of remote monitoring video.";
CM_ SG_ 648 HU_RemoteMonitoringSt "This signal is used to indicate remote monitoring status of IVI.";
CM_ SG_ 648 LiveCounter_HU_5 "The Livecounter is used to check the signal consistency of the messages . If the signals are consecutive, the LiveCounter should also be sequential in the way 0, 1, 2 °≠15, 0, 1 °≠";
CM_ SG_ 650 TargetSelectionCenter_X "Target Selection Center X";
CM_ SG_ 650 TargetSelection_Area "Target Selection Area";
CM_ SG_ 650 TargetSelectionCenter_Y "Target Selection Center Y";
CM_ SG_ 650 TargetSelectionCenter_Angle "Target Selection Center Angle";
CM_ SG_ 650 TargetSelection_ParkType "Target Selection Park Type";
CM_ SG_ 650 TargetSelection_ParkDirection "Target Selection ParkDirection";
CM_ SG_ 650 TargetSelection_LineAngle "Target Selection Line Angle";
CM_ SG_ 650 TargetSelection_ConfirmReq "Target Selection Confirm Request";
CM_ SG_ 650 APAFunctionReq "This signal is used to modify the configuration of APA function.";
CM_ SG_ 650 ParkInFunctionCancelReq "ParkIn Function Cancel Request";
CM_ SG_ 650 ParkInSlotSearchModeSet "Park-in slot search mode setting";
CM_ SG_ 650 ParkOutDirection "Park out direction";
CM_ SG_ 650 ParkOutFunctionConfirmReq "ParkOut Function Confirm Request";
CM_ SG_ 650 ParkOutFunctionCancelReq "ParkOut Function Cancel Request";
CM_ SG_ 650 ADBFunctionReq "This signal is used to modify the configuration of ADB function.";
CM_ SG_ 768 Checksum_BLE_DMH "The checksum is used to check whether the data from the CPU buffer are shifted without transmission errors to the CAN communication controller buffer and vice versa.";
CM_ SG_ 768 BLE_RemoteCtrlDirectionReq "Vehicle Direction Request";
CM_ SG_ 768 BLE_DMHReq "DMH Request, include Park in begin; Park in finish; Park out begin; Park out finish functions.";
CM_ SG_ 768 BLE_RemoteCtrlSteeringWheelAngle "Steering Wheel Angle Request";
CM_ SG_ 768 BLE_RemoteCtrlSteeringWheel_0000 "Steering Wheel Angle Sign Request";
CM_ SG_ 768 BLE__ParkInFunctionCancelReq "ParkIn Function Cancel Request";
CM_ SG_ 768 BLE__ParkOutDirection "Park out direction";
CM_ SG_ 768 BLE_ParkOutFunctionConfirmReq "ParkOut Function Confirm Request";
CM_ SG_ 768 BLE_ParkOutFunctionCancelReq "ParkOut Function Cancel Request";
CM_ SG_ 768 BLE_AutoParkFunctionReq "Auto Park Function Request";
CM_ SG_ 768 BLE_ConnectionSt "BLE bluetooth connection status";
CM_ SG_ 768 LiveCounter_BLE_DMH "The Livecounter is used to check the signal consistency of the messages . If the signals are consecutive, the LiveCounter should also be sequential in the way 0, 1, 2 °≠15, 0, 1 °≠";
CM_ SG_ 652 Checksum_HU_Speech_1 "The checksum is used to check whether the data from the CPU buffer are shifted without transmission errors to the CAN communication controller buffer and vice versa.";
CM_ SG_ 652 HU_SpeechReq_AVS "This signal is used to request AVS function on or Off by speech.";
CM_ SG_ 652 HU_SpeechReq_AVSViewMode "The signals indicates the view mode changing request by speech.";
CM_ SG_ 652 HU_SpeechReq_PDC "This signal is used to request PDC function on or off by speech.";
CM_ SG_ 652 HU_SpeechReq_ParkOutTypeReq "This signal is used to request park out type by speech.";
CM_ SG_ 652 HU_SpeechReq_AVPFunctionReq "This signal is used to modify the configuration of AVP function by speech..";
CM_ SG_ 652 HU_SpeechReq_HPAFunctionReq "This signal is used to modify the configuration of HPA function by speech..";
CM_ SG_ 652 HU_SpeechReq_APAFunctionReq "This signal is used to modify the configuration of APA function by speech..";
CM_ SG_ 652 HU_SpeechReq_VAS "This signal is used to request VAS function on or off by speech.";
CM_ SG_ 652 HU_SpeechReq_TSR "This signal is used to request TSR function on or off by speech.";
CM_ SG_ 652 HU_SpeechReq_DSM "This signal is used to request DSM function on or off by speech.";
CM_ SG_ 652 HU_SpeechReq_ParkOutFuncReq "This signal is used to request park out function on or off by speech.";
CM_ SG_ 652 HU_SpeechReq_ParkInModeReq "This signal is used to request park in mode manual or auto by speech.";
CM_ SG_ 652 HU_SpeechReq_ParkInTypeReq "This signal is used to request park in type by speech.";
CM_ SG_ 652 LiveCounter_HU_Speech_1 "The Livecounter is used to check the signal consistency of the messages . If the signals are consecutive, the LiveCounter should also be sequential in the way 0, 1, 2 °≠15, 0, 1 °≠";
CM_ SG_ 656 IndicationSpeed_IC "The signal describes the displayed vehicle speed on the cluster. IC receives VehicleSpeed_ABS and gives out the display value.";
CM_ SG_ 656 OdometerValue "This signal is drive distance since prime start .,Signal Initial=last value";
CM_ SG_ 418 PEPS_DMHSwitch "DMH Switch";
CM_ SG_ 418 PEPS_LockSwitch "Lock Switch";
CM_ SG_ 418 PEPS_UnlockSwitch "Unlock Switch";
CM_ SG_ 418 PEPS_PLGUnlockSwitch "PLG Unlock Switch";
CM_ SG_ 418 LiveCounter_PEPS_DMH "The Livecounter is used to check the signal consistency of the messages . If the signals are consecutive, the LiveCounter should also be sequential in the way 0, 1, 2 °≠15, 0, 1 °≠";
CM_ SG_ 578 LuggageDoorSt "This signal indicates luggage door status";
CM_ SG_ 586 DoorLockSt_FL "This signal indicates the lock state of driver door.";
CM_ SG_ 586 DoorSt_FL "This signal indicates the state of driver door.";
CM_ SG_ 586 DoorWindowSt_FL "This signal indicates the position of driver window.";
CM_ SG_ 586 LeftlightFaultSt_LCDA "This signal indicates whether left driving light is failure for LCDA.";
CM_ SG_ 586 MirrorFoldSt_FL "Fold status of left mirror";
CM_ SG_ 588 DoorLockSt_FR "This signal indicates the lock state of passenger door.";
CM_ SG_ 588 DoorSt_FR "This signal indicates the state of passenger door.";
CM_ SG_ 588 DoorWindowSt_FR "This signal indicates the position of passenger window.";
CM_ SG_ 588 RightlightFaultSt_LCDA "This signal indicates whether right driving light is failure for LCDA.";
CM_ SG_ 588 MirrorFoldSt_FR "Fold status of right mirror";
CM_ SG_ 590 DoorLockSt_RL "This signal indicates the lock state of RL door.";
CM_ SG_ 590 DoorSt_RL "This signal indicates the state of RL door.";
CM_ SG_ 590 DoorWindowSt_RL "This signal indicates the position of RL window.";
CM_ SG_ 591 DoorLockSt_RR "This signal indicates the lock state of RR door.";
CM_ SG_ 591 DoorSt_RR "This signal indicates the state of RR door.";
CM_ SG_ 591 DoorWindowSt_RR "This signal indicates the position of RR window.";
CM_ SG_ 528 ECAS_ErrorStatus "Indicates the error state of ECAS";
CM_ SG_ 528 ECAS_ActionState "Indicates the action of ECAS";
CM_ SG_ 528 ECAS_RequestLevel "Requested level by switch or automatic,Signal Initial=last value";
CM_ SG_ 528 ECAS_ActualLevel "Actual level by switch or automatic,Signal Initial=last value";
CM_ SG_ 528 ECAS_HeightChangeFailureTip "Indicates the height level change function of ECAS is not available";
CM_ SG_ 528 ECAS_ReductionLevelSt "Indicates the ECAS reduction level status";
CM_ SG_ 432 ECAS_Height_FL "Height of front left corner";
CM_ SG_ 432 ECAS_Height_FR "Height of front right corner";
CM_ SG_ 432 ECAS_Height_RL "Height of rear left corner";
CM_ SG_ 432 ECAS_Height_RR "Height of rear right corner";
CM_ SG_ 529 AxleLoad_Front "the load of front axle";
CM_ SG_ 529 AxleLoad_Rear "the load of rear axle";
CM_ SG_ 597 HighbeamSt_FL_ADB "The signal  indicates the status of front left high beam indicator.";
CM_ SG_ 597 HighbeamFaultSt_FL_ADB "The signal  indicates the fault status of front left high beam indicator.";
CM_ SG_ 597 ADBL_FunctionInd "Function indication of the left ADB controller.";
CM_ SG_ 597 ADBL_Errorstatus "Error indication of the left ADB controller.";
CM_ SG_ 597 ADBL_Status "Indicates the status of left ADB functon.";
CM_ SG_ 598 HighbeamSt_FR_ADB "The signal  indicates the status of front right high beam indicator.";
CM_ SG_ 598 HighbeamFaultSt_FR_ADB "The signal  indicates the fault status of front right high beam indicator.";
CM_ SG_ 598 ADBR_FunctionInd "Function indication of the right ADB controller.";
CM_ SG_ 598 ADBR_Errorstatus "Error indication of the right ADB controller.";
CM_ SG_ 598 ADBR_Status "Indicates the status of right ADB functon.";
CM_ SG_ 539 HDMAP_Status "Indicates the status of HDMAP.";
CM_ SG_ 614 DSM_FatigueWarning "This signal indicates fatigue driving  warning";
CM_ SG_ 614 DSM_DistractionWarning "This signal indicates the distraction warning";
CM_ SG_ 614 DSM_IntentionWarning "This signal indicates the intention of driver.";
CM_ SG_ 614 DSM_FunctionalSafetyValidFlag "This signal indicates the functional safety level valid flag of DSM.";
CM_ SG_ 614 DSM_AutoDriveDataRecordStatus "DSM automotive drive data recode status";
CM_ SG_ 614 DSM_AutoDriveDataRecordAvailable "Indicates DSM automotive drive data record available or not";
CM_ SG_ 614 DSM_AttentionArea "This signal indicates the attention area of driver.";
CM_ SG_ 614 DSM_Blockage "This signal indicates DSM sensor is blocked or not.";
CM_ SG_ 614 DSM_FaultSt "This signal indicates DSM system is faulty or not";
CM_ SG_ 614 DSM_Emotion "The driver emotion information";
CM_ SG_ 614 DSM_WorkingSt "This signal indicates the DSM working status.,Signal Initial=last value";
CM_ SG_ 614 DSM_DSM_SpeechControlFeedback "This signal indicates the speech control feedback of DSM function setting";
CM_ SG_ 614 DSM_CalibrationStatus "This signal indicates the DSM sensor calibration status.,Signal Initial=last value";
CM_ SG_ 614 DSM_FaceUnrecognizedTip "This signal indicates the tip of face failed to be recognized.";
CM_ SG_ 614 Livecounter_DSM_1 "The Livecounter is used to check the signal consistency of the messages . If the signals are consecutive, the LiveCounter should also be sequential in the way 0, 1, 2 °≠15, 0, 1 °≠";
CM_ SG_ 612 DSM_FaceIDBindfaceResult "This signal indicates face ID bind or unbind with driver face feature is successful or not";
CM_ SG_ 612 DSM_AccountBindFaceResult "This signal indicates accout bind or unbind with driver face is successful or not";
CM_ SG_ 612 DSM_FaceFeature "The signal indicates the face feature.";
CM_ SG_ 612 DSM_FaceID_DSM "The signal indicates the face ID from DSM";
CM_ SG_ 612 AccountID_DSM "This signal indicates the account ID.
0:Initial/No account identified 1~14:Account ID 15:Invalid value";
CM_ SG_ 612 DSM_EyePosition_X "This signal indicates the x position of driver eyes.";
CM_ SG_ 612 DSM_EyePosition_Y "This signal indicates the Y position of driver eyes.";
CM_ SG_ 612 DSM_EyePosition_Z "This signal indicates the Z position of driver eyes.";
CM_ SG_ 612 Livecounter_DSM_2 "The Livecounter is used to check the signal consistency of the messages . If the signals are consecutive, the LiveCounter should also be sequential in the way 0, 1, 2 °≠15, 0, 1 °≠";
CM_ SG_ 618 FMradar_FCTA_status "FCTA function status of front corner master radar,Signal Initial=last value";
CM_ SG_ 618 FMradar_FCTB_status "FCTB function status of front corner master radar,Signal Initial=last value";
CM_ SG_ 618 FMradar_FCTA_Warning_Left "Left warning command of FCTA function";
CM_ SG_ 618 FMradar_FCTB_BrakeReq "Front corner radar request to brake the car in FCTB function.";
CM_ SG_ 618 FMradar_failure_status "front corner master radar failure status";
CM_ SG_ 618 FMradar_Blockage_status "front corner master radar sensor is blocked or not";
CM_ SG_ 618 FMradar_calibrated_status "front corner master radarsensor is calibrated or not.";
CM_ SG_ 618 FMradar_FCTA_Warning_Right "Right warning command of FCTA function";
CM_ SG_ 618 Livecounter_FMradar_1 "The Livecounter is used to check the signal consistency of the messages . If the signals are consecutive, the LiveCounter should also be sequential in the way 0, 1, 2 °≠15, 0, 1 °≠";
CM_ SG_ 619 FSradar_Blockage_status "front corner slave radar sensor is blocked or not";
CM_ SG_ 619 Livecounter_FSradar_1 "The Livecounter is used to check the signal consistency of the messages . If the signals are consecutive, the LiveCounter should also be sequential in the way 0, 1, 2 °≠15, 0, 1 °≠";
CM_ SG_ 616 Checksum_LCDA_1 "The checksum is used to check whether the data from the CPU buffer are shifted without transmission errors to the CAN communication controller buffer and vice versa.";
CM_ SG_ 616 LCDA_ErrorSt_LCDA "This signal indicates the LCDA system error status.";
CM_ SG_ 616 LCDA_WarningCmd_LCDA_Left "The signal is warning command for BSD/LCDA from left side. ";
CM_ SG_ 616 LCDA_WarningCmd_LCDA_Right "The signal is warning command for BSD/LCDA from right side. ";
CM_ SG_ 616 LCDA_WorkingSt_RCW "This signal indicates RCW function working status.";
CM_ SG_ 616 LCDA_WarningCmd_RCTA_left "This signal is warning command for  RCTA from left side. ";
CM_ SG_ 616 LCDA_BuzzerCmd_RCTA_left "This signal is warning command for  RCTA from left side. ";
CM_ SG_ 616 LCDA_WarningCmd_RCTA_Right "The signal is warning command for  RCTA from right side. ";
CM_ SG_ 616 LCDA_BuzzerCmd_RCTA_Right "The signal is warning command for  RCTA from right side. ";
CM_ SG_ 616 LCDA_WorkingSt_RCTA "This signal indicates RCTA function working status.";
CM_ SG_ 616 LCDA_WorkingSt_LCWBSD "This signal indicates LCDA(LCW+BSD) function working status.";
CM_ SG_ 616 LCDA_WorkingSt_RCTABuzzer "This signal indicates RCTA Buzzer warning function working status.";
CM_ SG_ 616 LCDA_WarningCmd_DOW_FL "The signal nidicates warning command for DOW when front left side object is detected.";
CM_ SG_ 616 LCDA_WarningCmd_DOW_FR "The signal nidicates warning command for DOW when front right side object is detected.";
CM_ SG_ 616 LCDA_WarningCmd_DOW_RL "The signal nidicates warning command for DOW when rear left side object is detected.";
CM_ SG_ 616 LCDA_WarningCmd_DOW_RR "The signal nidicates warning command for DOW when rear right side object is detected.";
CM_ SG_ 616 LCDA_WarningCmd_RCW "The signal is warning command for RCW. ";
CM_ SG_ 616 LCDA_WorkingSt_DOW "This signal indicates DOW function working status.";
CM_ SG_ 616 LCDA_Blockage_RR "The rear right sensor is blocked or not.";
CM_ SG_ 616 LCDA__BrakeReq_RCTB "Rear corner radar request to brake the car in RCTB function.";
CM_ SG_ 616 LCDA_WorkingSt_RCTB "This signal indicates the RCTB working status,Signal Initial=last value";
CM_ SG_ 616 LCDA_MisAlign_status "Rear corner radar sensor status.";
CM_ SG_ 616 LiveCounter_LCDA_1 "The Livecounter is used to check the signal consistency of the messages . If the signals are consecutive, the LiveCounter should also be sequential in the way 0, 1, 2 °≠15, 0, 1 °≠";
BA_DEF_ SG_  "GenSigStartValue" INT 0 1000000000;
BA_DEF_ BO_  "GenMsgILSupport" ENUM  "No","Yes";
BA_DEF_ BO_  "CanTpSTmin" INT 0 0;
BA_DEF_ BO_  "CanTpFcFrameId" HEX 0 2147483647;
BA_DEF_ SG_  "GenSigSendType" ENUM  "Cyclic","OnWrite","OnWriteWithRepetition","OnChange","OnChangeWithRepetition","IfActive","IfActiveWithRepetition","NoSigSendType";
BA_DEF_ BO_  "GenMsgCycleTime" INT 0 50000;
BA_DEF_ BO_  "GenMsgSendType" ENUM  "Cyclic","not_used","not_used","not_used","not_used","Cyclic","not_used","IfActive","NoMsgSendType","Spontaneous","CyclicAndSpontaneous","NoMsgSendType";
BA_DEF_ SG_  "GenSigInvalidValue" INT 0 0;
BA_DEF_ SG_  "GenSigStartRemark" STRING ;
BA_DEF_ SG_  "GenSigInvalidRemark" STRING ;
BA_DEF_ SG_  "GenSigEvent" STRING ;
BA_DEF_ SG_  "SystemSignalLongSymbol" STRING ;
BA_DEF_REL_ BU_SG_REL_  "GenSigTimeoutTime" INT 0 5000;
BA_DEF_DEF_  "GenSigStartValue" 0;
BA_DEF_DEF_  "GenMsgILSupport" "Yes";
BA_DEF_DEF_  "CanTpSTmin" 1;
BA_DEF_DEF_  "CanTpFcFrameId" 2147483647;
BA_DEF_DEF_  "GenSigSendType" "NoSigSendType";
BA_DEF_DEF_  "GenMsgCycleTime" 0;
BA_DEF_DEF_  "GenMsgSendType" "NoMsgSendType";
BA_DEF_DEF_  "GenSigInvalidValue" 0;
BA_DEF_DEF_  "GenSigStartRemark" "";
BA_DEF_DEF_  "GenSigInvalidRemark" "";
BA_DEF_DEF_  "GenSigEvent" "";
BA_DEF_DEF_REL_ "GenSigTimeoutTime" 0;
BA_DEF_DEF_  "SystemSignalLongSymbol" "";
BA_ "GenMsgSendType" BO_ 457 0;
BA_ "GenMsgCycleTime" BO_ 457 50;
BA_ "GenMsgSendType" BO_ 458 0;
BA_ "GenMsgCycleTime" BO_ 458 50;
BA_ "GenMsgSendType" BO_ 455 0;
BA_ "GenMsgCycleTime" BO_ 455 50;
BA_ "GenMsgSendType" BO_ 388 0;
BA_ "GenMsgCycleTime" BO_ 388 100;
BA_ "GenMsgSendType" BO_ 390 0;
BA_ "GenMsgCycleTime" BO_ 390 100;
BA_ "GenMsgSendType" BO_ 391 0;
BA_ "GenMsgCycleTime" BO_ 391 100;
BA_ "GenMsgSendType" BO_ 392 0;
BA_ "GenMsgCycleTime" BO_ 392 100;
BA_ "GenMsgSendType" BO_ 393 0;
BA_ "GenMsgCycleTime" BO_ 393 100;
BA_ "GenMsgSendType" BO_ 394 0;
BA_ "GenMsgCycleTime" BO_ 394 100;
BA_ "GenMsgSendType" BO_ 395 0;
BA_ "GenMsgCycleTime" BO_ 395 100;
BA_ "GenMsgSendType" BO_ 384 0;
BA_ "GenMsgCycleTime" BO_ 384 30;
BA_ "GenMsgSendType" BO_ 386 0;
BA_ "GenMsgCycleTime" BO_ 386 30;
BA_ "GenMsgSendType" BO_ 546 0;
BA_ "GenMsgCycleTime" BO_ 546 100;
BA_ "GenMsgCycleTime" BO_ 560 100;
BA_ "GenMsgSendType" BO_ 560 0;
BA_ "GenMsgCycleTime" BO_ 562 100;
BA_ "GenMsgSendType" BO_ 562 0;
BA_ "GenMsgCycleTime" BO_ 564 100;
BA_ "GenMsgSendType" BO_ 564 0;
BA_ "GenMsgSendType" BO_ 571 0;
BA_ "GenMsgCycleTime" BO_ 571 100;
BA_ "GenMsgSendType" BO_ 572 0;
BA_ "GenMsgCycleTime" BO_ 572 100;
BA_ "GenMsgSendType" BO_ 678 0;
BA_ "GenMsgCycleTime" BO_ 678 100;
BA_ "GenMsgSendType" BO_ 691 0;
BA_ "GenMsgCycleTime" BO_ 691 100;
BA_ "GenMsgSendType" BO_ 688 0;
BA_ "GenMsgCycleTime" BO_ 688 100;
BA_ "GenMsgCycleTime" BO_ 640 100;
BA_ "GenMsgSendType" BO_ 640 0;
BA_ "GenMsgCycleTime" BO_ 643 100;
BA_ "GenMsgSendType" BO_ 643 0;
BA_ "GenMsgCycleTime" BO_ 648 100;
BA_ "GenMsgSendType" BO_ 648 0;
BA_ "GenMsgCycleTime" BO_ 650 100;
BA_ "GenMsgSendType" BO_ 650 0;
BA_ "GenMsgCycleTime" BO_ 768 200;
BA_ "GenMsgSendType" BO_ 768 0;
BA_ "GenMsgCycleTime" BO_ 652 100;
BA_ "GenMsgSendType" BO_ 652 0;
BA_ "GenMsgSendType" BO_ 656 0;
BA_ "GenMsgCycleTime" BO_ 656 100;
BA_ "GenMsgSendType" BO_ 418 0;
BA_ "GenMsgCycleTime" BO_ 418 50;
BA_ "GenMsgCycleTime" BO_ 578 100;
BA_ "GenMsgSendType" BO_ 578 0;
BA_ "GenMsgCycleTime" BO_ 586 100;
BA_ "GenMsgSendType" BO_ 586 0;
BA_ "GenMsgCycleTime" BO_ 588 100;
BA_ "GenMsgSendType" BO_ 588 0;
BA_ "GenMsgCycleTime" BO_ 590 100;
BA_ "GenMsgSendType" BO_ 590 0;
BA_ "GenMsgCycleTime" BO_ 591 100;
BA_ "GenMsgSendType" BO_ 591 0;
BA_ "GenMsgSendType" BO_ 528 0;
BA_ "GenMsgCycleTime" BO_ 528 100;
BA_ "GenMsgSendType" BO_ 432 0;
BA_ "GenMsgCycleTime" BO_ 432 50;
BA_ "GenMsgSendType" BO_ 529 0;
BA_ "GenMsgCycleTime" BO_ 529 100;
BA_ "GenMsgSendType" BO_ 597 0;
BA_ "GenMsgCycleTime" BO_ 597 100;
BA_ "GenMsgSendType" BO_ 598 0;
BA_ "GenMsgCycleTime" BO_ 598 100;
BA_ "GenMsgSendType" BO_ 539 0;
BA_ "GenMsgCycleTime" BO_ 539 20;
BA_ "GenMsgCycleTime" BO_ 614 100;
BA_ "GenMsgSendType" BO_ 614 0;
BA_ "GenMsgSendType" BO_ 612 0;
BA_ "GenMsgCycleTime" BO_ 612 100;
BA_ "GenMsgSendType" BO_ 618 0;
BA_ "GenMsgCycleTime" BO_ 618 100;
BA_ "GenMsgSendType" BO_ 619 0;
BA_ "GenMsgCycleTime" BO_ 619 100;
BA_ "GenMsgCycleTime" BO_ 616 100;
BA_ "GenMsgSendType" BO_ 616 0;
BA_ "GenSigStartRemark" SG_ 457 Checksum_PDC_12 "V";
BA_ "GenSigInvalidRemark" SG_ 457 ACoordinateY_Right "500";
BA_ "GenSigStartRemark" SG_ 457 ACoordinateY_Right "500";
BA_ "GenSigInvalidValue" SG_ 457 ACoordinateY_Right 1023;
BA_ "GenSigStartValue" SG_ 457 ACoordinateY_Right 1022;
BA_ "GenSigInvalidRemark" SG_ 457 ACoordinateX_Right "3600";
BA_ "GenSigStartRemark" SG_ 457 ACoordinateX_Right "3600";
BA_ "GenSigInvalidValue" SG_ 457 ACoordinateX_Right 4095;
BA_ "GenSigStartValue" SG_ 457 ACoordinateX_Right 4094;
BA_ "GenSigInvalidRemark" SG_ 457 BCoordinateY_Right "500";
BA_ "GenSigStartRemark" SG_ 457 BCoordinateY_Right "500";
BA_ "GenSigInvalidValue" SG_ 457 BCoordinateY_Right 1023;
BA_ "GenSigStartValue" SG_ 457 BCoordinateY_Right 1022;
BA_ "GenSigInvalidRemark" SG_ 457 BCoordinateX_Right "3600";
BA_ "GenSigStartRemark" SG_ 457 BCoordinateX_Right "3600";
BA_ "GenSigInvalidValue" SG_ 457 BCoordinateX_Right 4095;
BA_ "GenSigStartValue" SG_ 457 BCoordinateX_Right 4094;
BA_ "GenSigStartRemark" SG_ 458 Checksum_PDC_13 "V";
BA_ "GenSigInvalidRemark" SG_ 458 CCoordinateY_Right "500";
BA_ "GenSigStartRemark" SG_ 458 CCoordinateY_Right "500";
BA_ "GenSigInvalidValue" SG_ 458 CCoordinateY_Right 1023;
BA_ "GenSigStartValue" SG_ 458 CCoordinateY_Right 1022;
BA_ "GenSigInvalidRemark" SG_ 458 CCoordinateX_Right "3600";
BA_ "GenSigStartRemark" SG_ 458 CCoordinateX_Right "3600";
BA_ "GenSigInvalidValue" SG_ 458 CCoordinateX_Right 4095;
BA_ "GenSigStartValue" SG_ 458 CCoordinateX_Right 4094;
BA_ "GenSigInvalidRemark" SG_ 458 DCoordinateY_Right "500";
BA_ "GenSigStartRemark" SG_ 458 DCoordinateY_Right "500";
BA_ "GenSigInvalidValue" SG_ 458 DCoordinateY_Right 1023;
BA_ "GenSigStartValue" SG_ 458 DCoordinateY_Right 1022;
BA_ "GenSigInvalidRemark" SG_ 458 DCoordinateX_Right "3600";
BA_ "GenSigStartRemark" SG_ 458 DCoordinateX_Right "3600";
BA_ "GenSigInvalidValue" SG_ 458 DCoordinateX_Right 4095;
BA_ "GenSigStartValue" SG_ 458 DCoordinateX_Right 4094;
BA_ "GenSigStartRemark" SG_ 455 Checksum_PDC_10 "V";
BA_ "GenSigInvalidRemark" SG_ 455 DistanceValue_RLS "500";
BA_ "GenSigStartRemark" SG_ 455 DistanceValue_RLS "500";
BA_ "GenSigInvalidValue" SG_ 455 DistanceValue_RLS 1023;
BA_ "GenSigStartValue" SG_ 455 DistanceValue_RLS 1022;
BA_ "GenSigInvalidRemark" SG_ 455 DistanceValue_RRS "500";
BA_ "GenSigStartRemark" SG_ 455 DistanceValue_RRS "500";
BA_ "GenSigInvalidValue" SG_ 455 DistanceValue_RRS 1023;
BA_ "GenSigStartValue" SG_ 455 DistanceValue_RRS 1022;
BA_ "GenSigInvalidRemark" SG_ 455 ParkingSlotDepth_Right "500";
BA_ "GenSigStartRemark" SG_ 455 ParkingSlotDepth_Right "500";
BA_ "GenSigInvalidValue" SG_ 455 ParkingSlotDepth_Right 1023;
BA_ "GenSigStartValue" SG_ 455 ParkingSlotDepth_Right 1022;
BA_ "GenSigInvalidRemark" SG_ 390 APS_Slot1CenterPoint_X1 "2000";
BA_ "GenSigStartRemark" SG_ 390 APS_Slot1CenterPoint_X1 "2000";
BA_ "GenSigInvalidValue" SG_ 390 APS_Slot1CenterPoint_X1 2047;
BA_ "GenSigStartValue" SG_ 390 APS_Slot1CenterPoint_X1 2046;
BA_ "GenSigInvalidRemark" SG_ 390 APS_Slot1CenterPoint_Y1 "2000";
BA_ "GenSigStartRemark" SG_ 390 APS_Slot1CenterPoint_Y1 "2000";
BA_ "GenSigInvalidValue" SG_ 390 APS_Slot1CenterPoint_Y1 2047;
BA_ "GenSigStartValue" SG_ 390 APS_Slot1CenterPoint_Y1 2046;
BA_ "GenSigInvalidRemark" SG_ 390 APS_Slot1_LineAngle "360";
BA_ "GenSigStartRemark" SG_ 390 APS_Slot1_LineAngle "360";
BA_ "GenSigInvalidValue" SG_ 390 APS_Slot1_LineAngle 1023;
BA_ "GenSigStartValue" SG_ 390 APS_Slot1_LineAngle 1022;
BA_ "GenSigInvalidRemark" SG_ 390 APS_Slot1_Length "1000";
BA_ "GenSigStartRemark" SG_ 390 APS_Slot1_Length "1000";
BA_ "GenSigInvalidValue" SG_ 390 APS_Slot1_Length 1023;
BA_ "GenSigStartValue" SG_ 390 APS_Slot1_Length 1022;
BA_ "GenSigInvalidRemark" SG_ 390 APS_Slot1_Width "1000";
BA_ "GenSigStartRemark" SG_ 390 APS_Slot1_Width "1000";
BA_ "GenSigInvalidValue" SG_ 390 APS_Slot1_Width 1023;
BA_ "GenSigStartValue" SG_ 390 APS_Slot1_Width 1022;
BA_ "GenSigInvalidRemark" SG_ 391 APS_Slot2CenterPoint_X1 "2000";
BA_ "GenSigStartRemark" SG_ 391 APS_Slot2CenterPoint_X1 "2000";
BA_ "GenSigInvalidValue" SG_ 391 APS_Slot2CenterPoint_X1 2047;
BA_ "GenSigStartValue" SG_ 391 APS_Slot2CenterPoint_X1 2046;
BA_ "GenSigInvalidRemark" SG_ 391 APS_Slot2CenterPoint_Y1 "2000";
BA_ "GenSigStartRemark" SG_ 391 APS_Slot2CenterPoint_Y1 "2000";
BA_ "GenSigInvalidValue" SG_ 391 APS_Slot2CenterPoint_Y1 2047;
BA_ "GenSigStartValue" SG_ 391 APS_Slot2CenterPoint_Y1 2046;
BA_ "GenSigInvalidRemark" SG_ 391 APS_Slot2_LineAngle "360";
BA_ "GenSigStartRemark" SG_ 391 APS_Slot2_LineAngle "360";
BA_ "GenSigInvalidValue" SG_ 391 APS_Slot2_LineAngle 1023;
BA_ "GenSigStartValue" SG_ 391 APS_Slot2_LineAngle 1022;
BA_ "GenSigInvalidRemark" SG_ 391 APS_Slot2_Length "1000";
BA_ "GenSigStartRemark" SG_ 391 APS_Slot2_Length "1000";
BA_ "GenSigInvalidValue" SG_ 391 APS_Slot2_Length 1023;
BA_ "GenSigStartValue" SG_ 391 APS_Slot2_Length 1022;
BA_ "GenSigInvalidRemark" SG_ 391 APS_Slot2_Width "1000";
BA_ "GenSigStartRemark" SG_ 391 APS_Slot2_Width "1000";
BA_ "GenSigInvalidValue" SG_ 391 APS_Slot2_Width 1023;
BA_ "GenSigStartValue" SG_ 391 APS_Slot2_Width 1022;
BA_ "GenSigInvalidRemark" SG_ 392 APS_Slot3CenterPoint_X1 "2000";
BA_ "GenSigStartRemark" SG_ 392 APS_Slot3CenterPoint_X1 "2000";
BA_ "GenSigInvalidValue" SG_ 392 APS_Slot3CenterPoint_X1 2047;
BA_ "GenSigStartValue" SG_ 392 APS_Slot3CenterPoint_X1 2046;
BA_ "GenSigInvalidRemark" SG_ 392 APS_Slot3CenterPoint_Y1 "2000";
BA_ "GenSigStartRemark" SG_ 392 APS_Slot3CenterPoint_Y1 "2000";
BA_ "GenSigInvalidValue" SG_ 392 APS_Slot3CenterPoint_Y1 2047;
BA_ "GenSigStartValue" SG_ 392 APS_Slot3CenterPoint_Y1 2046;
BA_ "GenSigInvalidRemark" SG_ 392 APS_Slot3_LineAngle "360";
BA_ "GenSigStartRemark" SG_ 392 APS_Slot3_LineAngle "360";
BA_ "GenSigInvalidValue" SG_ 392 APS_Slot3_LineAngle 1023;
BA_ "GenSigStartValue" SG_ 392 APS_Slot3_LineAngle 1022;
BA_ "GenSigInvalidRemark" SG_ 392 APS_Slot3_Length "1000";
BA_ "GenSigStartRemark" SG_ 392 APS_Slot3_Length "1000";
BA_ "GenSigInvalidValue" SG_ 392 APS_Slot3_Length 1023;
BA_ "GenSigStartValue" SG_ 392 APS_Slot3_Length 1022;
BA_ "GenSigInvalidRemark" SG_ 392 APS_Slot3_Width "1000";
BA_ "GenSigStartRemark" SG_ 392 APS_Slot3_Width "1000";
BA_ "GenSigInvalidValue" SG_ 392 APS_Slot3_Width 1023;
BA_ "GenSigStartValue" SG_ 392 APS_Slot3_Width 1022;
BA_ "GenSigInvalidRemark" SG_ 393 APS_Slot4CenterPoint_X1 "2000";
BA_ "GenSigStartRemark" SG_ 393 APS_Slot4CenterPoint_X1 "2000";
BA_ "GenSigInvalidValue" SG_ 393 APS_Slot4CenterPoint_X1 2047;
BA_ "GenSigStartValue" SG_ 393 APS_Slot4CenterPoint_X1 2046;
BA_ "GenSigInvalidRemark" SG_ 393 APS_Slot4CenterPoint_Y1 "2000";
BA_ "GenSigStartRemark" SG_ 393 APS_Slot4CenterPoint_Y1 "2000";
BA_ "GenSigInvalidValue" SG_ 393 APS_Slot4CenterPoint_Y1 2047;
BA_ "GenSigStartValue" SG_ 393 APS_Slot4CenterPoint_Y1 2046;
BA_ "GenSigInvalidRemark" SG_ 393 APS_Slot4_LineAngle "360";
BA_ "GenSigStartRemark" SG_ 393 APS_Slot4_LineAngle "360";
BA_ "GenSigInvalidValue" SG_ 393 APS_Slot4_LineAngle 1023;
BA_ "GenSigStartValue" SG_ 393 APS_Slot4_LineAngle 1022;
BA_ "GenSigInvalidRemark" SG_ 393 APS_Slot4_Length "1000";
BA_ "GenSigStartRemark" SG_ 393 APS_Slot4_Length "1000";
BA_ "GenSigInvalidValue" SG_ 393 APS_Slot4_Length 1023;
BA_ "GenSigStartValue" SG_ 393 APS_Slot4_Length 1022;
BA_ "GenSigInvalidRemark" SG_ 393 APS_Slot4_Width "1000";
BA_ "GenSigStartRemark" SG_ 393 APS_Slot4_Width "1000";
BA_ "GenSigInvalidValue" SG_ 393 APS_Slot4_Width 1023;
BA_ "GenSigStartValue" SG_ 393 APS_Slot4_Width 1022;
BA_ "GenSigInvalidRemark" SG_ 394 APS_Slot5CenterPoint_X1 "2000";
BA_ "GenSigStartRemark" SG_ 394 APS_Slot5CenterPoint_X1 "2000";
BA_ "GenSigInvalidValue" SG_ 394 APS_Slot5CenterPoint_X1 2047;
BA_ "GenSigStartValue" SG_ 394 APS_Slot5CenterPoint_X1 2046;
BA_ "GenSigInvalidRemark" SG_ 394 APS_Slot5CenterPoint_Y1 "2000";
BA_ "GenSigStartRemark" SG_ 394 APS_Slot5CenterPoint_Y1 "2000";
BA_ "GenSigInvalidValue" SG_ 394 APS_Slot5CenterPoint_Y1 2047;
BA_ "GenSigStartValue" SG_ 394 APS_Slot5CenterPoint_Y1 2046;
BA_ "GenSigInvalidRemark" SG_ 394 APS_Slot5_LineAngle "360";
BA_ "GenSigStartRemark" SG_ 394 APS_Slot5_LineAngle "360";
BA_ "GenSigInvalidValue" SG_ 394 APS_Slot5_LineAngle 1023;
BA_ "GenSigStartValue" SG_ 394 APS_Slot5_LineAngle 1022;
BA_ "GenSigInvalidRemark" SG_ 394 APS_Slot5_Length "1000";
BA_ "GenSigStartRemark" SG_ 394 APS_Slot5_Length "1000";
BA_ "GenSigInvalidValue" SG_ 394 APS_Slot5_Length 1023;
BA_ "GenSigStartValue" SG_ 394 APS_Slot5_Length 1022;
BA_ "GenSigInvalidRemark" SG_ 394 APS_Slot5_Width "1000";
BA_ "GenSigStartRemark" SG_ 394 APS_Slot5_Width "1000";
BA_ "GenSigInvalidValue" SG_ 394 APS_Slot5_Width 1023;
BA_ "GenSigStartValue" SG_ 394 APS_Slot5_Width 1022;
BA_ "GenSigInvalidRemark" SG_ 395 APS_Slot6CenterPoint_X1 "2000";
BA_ "GenSigStartRemark" SG_ 395 APS_Slot6CenterPoint_X1 "2000";
BA_ "GenSigInvalidValue" SG_ 395 APS_Slot6CenterPoint_X1 2047;
BA_ "GenSigStartValue" SG_ 395 APS_Slot6CenterPoint_X1 2046;
BA_ "GenSigInvalidRemark" SG_ 395 APS_Slot6CenterPoint_Y1 "2000";
BA_ "GenSigStartRemark" SG_ 395 APS_Slot6CenterPoint_Y1 "2000";
BA_ "GenSigInvalidValue" SG_ 395 APS_Slot6CenterPoint_Y1 2047;
BA_ "GenSigStartValue" SG_ 395 APS_Slot6CenterPoint_Y1 2046;
BA_ "GenSigInvalidRemark" SG_ 395 APS_Slot6_LineAngle "360";
BA_ "GenSigStartRemark" SG_ 395 APS_Slot6_LineAngle "360";
BA_ "GenSigInvalidValue" SG_ 395 APS_Slot6_LineAngle 1023;
BA_ "GenSigStartValue" SG_ 395 APS_Slot6_LineAngle 1022;
BA_ "GenSigInvalidRemark" SG_ 395 APS_Slot6_Length "1000";
BA_ "GenSigStartRemark" SG_ 395 APS_Slot6_Length "1000";
BA_ "GenSigInvalidValue" SG_ 395 APS_Slot6_Length 1023;
BA_ "GenSigStartValue" SG_ 395 APS_Slot6_Length 1022;
BA_ "GenSigInvalidRemark" SG_ 395 APS_Slot6_Width "1000";
BA_ "GenSigStartRemark" SG_ 395 APS_Slot6_Width "1000";
BA_ "GenSigInvalidValue" SG_ 395 APS_Slot6_Width 1023;
BA_ "GenSigStartValue" SG_ 395 APS_Slot6_Width 1022;
BA_ "GenSigInvalidRemark" SG_ 384 ADV_PathTracingCenter_X "2000";
BA_ "GenSigStartRemark" SG_ 384 ADV_PathTracingCenter_X "2000";
BA_ "GenSigInvalidValue" SG_ 384 ADV_PathTracingCenter_X 2047;
BA_ "GenSigStartValue" SG_ 384 ADV_PathTracingCenter_X 2046;
BA_ "GenSigInvalidRemark" SG_ 384 ADV_PathTracingCenter_Y "2000";
BA_ "GenSigStartRemark" SG_ 384 ADV_PathTracingCenter_Y "2000";
BA_ "GenSigInvalidValue" SG_ 384 ADV_PathTracingCenter_Y 2047;
BA_ "GenSigStartValue" SG_ 384 ADV_PathTracingCenter_Y 2046;
BA_ "GenSigInvalidRemark" SG_ 384 ADV_PathTracingAngle "360";
BA_ "GenSigStartRemark" SG_ 384 ADV_PathTracingAngle "360";
BA_ "GenSigInvalidValue" SG_ 384 ADV_PathTracingAngle 1023;
BA_ "GenSigStartValue" SG_ 384 ADV_PathTracingAngle 1022;
BA_ "GenSigInvalidRemark" SG_ 384 ADV_ShortestDistance "O";
BA_ "GenSigStartRemark" SG_ 384 ADV_ShortestDistance "O";
BA_ "GenSigInvalidValue" SG_ 384 ADV_ShortestDistance 255;
BA_ "GenSigStartValue" SG_ 384 ADV_ShortestDistance 254;
BA_ "GenSigInvalidRemark" SG_ 384 ADV_TotalPathNumber "10";
BA_ "GenSigStartRemark" SG_ 384 ADV_TotalPathNumber "10";
BA_ "GenSigInvalidValue" SG_ 384 ADV_TotalPathNumber 15;
BA_ "GenSigStartValue" SG_ 384 ADV_TotalPathNumber 14;
BA_ "GenSigInvalidRemark" SG_ 384 ADV_CurrentPathNumber "10";
BA_ "GenSigStartRemark" SG_ 384 ADV_CurrentPathNumber "10";
BA_ "GenSigInvalidValue" SG_ 384 ADV_CurrentPathNumber 15;
BA_ "GenSigStartValue" SG_ 384 ADV_CurrentPathNumber 14;
BA_ "GenSigInvalidRemark" SG_ 384 ADV_RemainingDistance "100";
BA_ "GenSigStartRemark" SG_ 384 ADV_RemainingDistance "100";
BA_ "GenSigInvalidValue" SG_ 384 ADV_RemainingDistance 127;
BA_ "GenSigStartValue" SG_ 384 ADV_RemainingDistance 126;
BA_ "GenSigInvalidRemark" SG_ 386 ADV_TargetTracingCenter_X "2000";
BA_ "GenSigStartRemark" SG_ 386 ADV_TargetTracingCenter_X "2000";
BA_ "GenSigInvalidValue" SG_ 386 ADV_TargetTracingCenter_X 2047;
BA_ "GenSigStartValue" SG_ 386 ADV_TargetTracingCenter_X 2046;
BA_ "GenSigInvalidRemark" SG_ 386 ADV_TargetTracingCenter_Y "2000";
BA_ "GenSigStartRemark" SG_ 386 ADV_TargetTracingCenter_Y "2000";
BA_ "GenSigInvalidValue" SG_ 386 ADV_TargetTracingCenter_Y 2047;
BA_ "GenSigStartValue" SG_ 386 ADV_TargetTracingCenter_Y 2046;
BA_ "GenSigInvalidRemark" SG_ 386 ADV_TargetTracingAngle "360";
BA_ "GenSigStartRemark" SG_ 386 ADV_TargetTracingAngle "360";
BA_ "GenSigInvalidValue" SG_ 386 ADV_TargetTracingAngle 1023;
BA_ "GenSigStartValue" SG_ 386 ADV_TargetTracingAngle 1022;
BA_ "GenSigInvalidRemark" SG_ 546 AmbientTemp "O";
BA_ "GenSigStartRemark" SG_ 546 AmbientTemp "O";
BA_ "GenSigInvalidValue" SG_ 546 AmbientTemp 255;
BA_ "GenSigStartValue" SG_ 546 AmbientTemp 254;
BA_ "GenSigEvent" SG_ 560 TurningSt_Left "Y";
BA_ "GenSigSendType" SG_ 560 TurningSt_Left 1;
BA_ "GenSigEvent" SG_ 560 TurningSt_right "Y";
BA_ "GenSigSendType" SG_ 560 TurningSt_right 1;
BA_ "GenSigEvent" SG_ 560 TurningLightCmd_Left "Y";
BA_ "GenSigSendType" SG_ 560 TurningLightCmd_Left 1;
BA_ "GenSigEvent" SG_ 560 TurningLightCmd_Right "Y";
BA_ "GenSigSendType" SG_ 560 TurningLightCmd_Right 1;
BA_ "GenSigInvalidValue" SG_ 562 PowerMode 15;
BA_ "GenSigEvent" SG_ 562 PEPS_RKEEngineCmd "Y";
BA_ "GenSigSendType" SG_ 562 PEPS_RKEEngineCmd 1;
BA_ "GenSigInvalidRemark" SG_ 562 AccountID_BCM "O";
BA_ "GenSigInvalidValue" SG_ 562 AccountID_BCM 15;
BA_ "GenSigEvent" SG_ 564 EngineHoodSt "Y";
BA_ "GenSigSendType" SG_ 564 EngineHoodSt 1;
BA_ "GenSigInvalidValue" SG_ 564 SunroofSt 7;
BA_ "GenSigInvalidRemark" SG_ 571 RainIntensity "10";
BA_ "GenSigStartRemark" SG_ 571 RainIntensity "10";
BA_ "GenSigInvalidValue" SG_ 571 RainIntensity 15;
BA_ "GenSigStartValue" SG_ 571 RainIntensity 14;
BA_ "GenSigInvalidRemark" SG_ 571 Brightness_L "O";
BA_ "GenSigStartRemark" SG_ 571 Brightness_L "O";
BA_ "GenSigInvalidValue" SG_ 571 Brightness_L 255;
BA_ "GenSigStartValue" SG_ 571 Brightness_L 254;
BA_ "GenSigInvalidRemark" SG_ 571 Brightness_H "O";
BA_ "GenSigStartRemark" SG_ 571 Brightness_H "O";
BA_ "GenSigInvalidValue" SG_ 571 Brightness_H 1023;
BA_ "GenSigStartValue" SG_ 571 Brightness_H 1022;
BA_ "GenSigInvalidRemark" SG_ 572 TyrePressureValue_FL "O";
BA_ "GenSigStartRemark" SG_ 572 TyrePressureValue_FL "O";
BA_ "GenSigInvalidValue" SG_ 572 TyrePressureValue_FL 255;
BA_ "GenSigStartValue" SG_ 572 TyrePressureValue_FL 254;
BA_ "GenSigInvalidRemark" SG_ 572 TyrePressureValue_FR "O";
BA_ "GenSigStartRemark" SG_ 572 TyrePressureValue_FR "O";
BA_ "GenSigInvalidValue" SG_ 572 TyrePressureValue_FR 255;
BA_ "GenSigStartValue" SG_ 572 TyrePressureValue_FR 254;
BA_ "GenSigInvalidRemark" SG_ 572 TyrePressureValue_RL "O";
BA_ "GenSigStartRemark" SG_ 572 TyrePressureValue_RL "O";
BA_ "GenSigInvalidValue" SG_ 572 TyrePressureValue_RL 255;
BA_ "GenSigStartValue" SG_ 572 TyrePressureValue_RL 254;
BA_ "GenSigInvalidRemark" SG_ 572 TyrePressureValue_RR "O";
BA_ "GenSigStartRemark" SG_ 572 TyrePressureValue_RR "O";
BA_ "GenSigInvalidValue" SG_ 572 TyrePressureValue_RR 255;
BA_ "GenSigStartValue" SG_ 572 TyrePressureValue_RR 254;
BA_ "GenSigInvalidRemark" SG_ 678 GPSTime_Hour "23";
BA_ "GenSigStartRemark" SG_ 678 GPSTime_Hour "23";
BA_ "GenSigInvalidValue" SG_ 678 GPSTime_Hour 31;
BA_ "GenSigStartValue" SG_ 678 GPSTime_Hour 30;
BA_ "GenSigInvalidRemark" SG_ 678 GPSTime_Minute "59";
BA_ "GenSigStartRemark" SG_ 678 GPSTime_Minute "59";
BA_ "GenSigInvalidValue" SG_ 678 GPSTime_Minute 63;
BA_ "GenSigStartValue" SG_ 678 GPSTime_Minute 62;
BA_ "GenSigInvalidRemark" SG_ 678 GPSTime_Second "59";
BA_ "GenSigStartRemark" SG_ 678 GPSTime_Second "59";
BA_ "GenSigInvalidValue" SG_ 678 GPSTime_Second 63;
BA_ "GenSigStartValue" SG_ 678 GPSTime_Second 62;
BA_ "GenSigInvalidRemark" SG_ 678 GPSTime_Year "O";
BA_ "GenSigStartRemark" SG_ 678 GPSTime_Year "O";
BA_ "GenSigInvalidValue" SG_ 678 GPSTime_Year 127;
BA_ "GenSigStartValue" SG_ 678 GPSTime_Year 126;
BA_ "GenSigInvalidRemark" SG_ 678 GPSTime_Month "11";
BA_ "GenSigStartRemark" SG_ 678 GPSTime_Month "11";
BA_ "GenSigInvalidValue" SG_ 678 GPSTime_Month 15;
BA_ "GenSigStartValue" SG_ 678 GPSTime_Month 14;
BA_ "GenSigInvalidRemark" SG_ 678 GPSTime_Day "30";
BA_ "GenSigStartRemark" SG_ 678 GPSTime_Day "30";
BA_ "GenSigInvalidValue" SG_ 678 GPSTime_Day 127;
BA_ "GenSigStartValue" SG_ 678 GPSTime_Day 126;
BA_ "GenSigInvalidRemark" SG_ 688 GW_IgnitionOffTime "O";
BA_ "GenSigStartRemark" SG_ 688 GW_IgnitionOffTime "O";
BA_ "GenSigInvalidValue" SG_ 688 GW_IgnitionOffTime 4095;
BA_ "GenSigStartValue" SG_ 688 GW_IgnitionOffTime 4094;
BA_ "GenSigStartRemark" SG_ 640 Checksum_HU_1 "V";
BA_ "GenSigEvent" SG_ 640 FCWFunctionReq "Y";
BA_ "GenSigSendType" SG_ 640 FCWFunctionReq 1;
BA_ "GenSigEvent" SG_ 640 FCWSensitivitySet "Y";
BA_ "GenSigSendType" SG_ 640 FCWSensitivitySet 1;
BA_ "GenSigEvent" SG_ 640 AEBFunctionReq "Y";
BA_ "GenSigSendType" SG_ 640 AEBFunctionReq 1;
BA_ "GenSigEvent" SG_ 640 DSMFunctionReq "Y";
BA_ "GenSigSendType" SG_ 640 DSMFunctionReq 1;
BA_ "GenSigEvent" SG_ 640 LDWSensitivitySet "Y";
BA_ "GenSigSendType" SG_ 640 LDWSensitivitySet 1;
BA_ "GenSigEvent" SG_ 640 LDWFunctionReq "Y";
BA_ "GenSigSendType" SG_ 640 LDWFunctionReq 1;
BA_ "GenSigEvent" SG_ 640 LDWModeSet "Y";
BA_ "GenSigSendType" SG_ 640 LDWModeSet 1;
BA_ "GenSigEvent" SG_ 640 TSRFunctionReq "Y";
BA_ "GenSigSendType" SG_ 640 TSRFunctionReq 1;
BA_ "GenSigEvent" SG_ 640 PDCFunctionReq "Y";
BA_ "GenSigSendType" SG_ 640 PDCFunctionReq 1;
BA_ "GenSigEvent" SG_ 640 CruiseFunctionReq "Y";
BA_ "GenSigSendType" SG_ 640 CruiseFunctionReq 1;
BA_ "GenSigEvent" SG_ 640 CruiseModeFunctionReq "Y";
BA_ "GenSigSendType" SG_ 640 CruiseModeFunctionReq 1;
BA_ "GenSigStartRemark" SG_ 640 CruiseModeFunctionReq "L";
BA_ "GenSigEvent" SG_ 640 VASFunctionReq "Y";
BA_ "GenSigSendType" SG_ 640 VASFunctionReq 1;
BA_ "GenSigStartRemark" SG_ 643 Checksum_HU_18 "V";
BA_ "GenSigEvent" SG_ 643 HU_BlindSpotFilledFunctionReq "Y";
BA_ "GenSigSendType" SG_ 643 HU_BlindSpotFilledFunctionReq 1;
BA_ "GenSigEvent" SG_ 643 HU_BacktrackFunctionReq "Y";
BA_ "GenSigSendType" SG_ 643 HU_BacktrackFunctionReq 1;
BA_ "GenSigEvent" SG_ 643 HU_ParkingAEBFunctionReq "Y";
BA_ "GenSigSendType" SG_ 643 HU_ParkingAEBFunctionReq 1;
BA_ "GenSigEvent" SG_ 643 HU_ADVDisclaimerTipConfirm "Y";
BA_ "GenSigSendType" SG_ 643 HU_ADVDisclaimerTipConfirm 1;
BA_ "GenSigEvent" SG_ 643 HU_APASuspendRequest "Y";
BA_ "GenSigSendType" SG_ 643 HU_APASuspendRequest 1;
BA_ "GenSigEvent" SG_ 643 HU_PDCAutoOnFunctionReq "Y";
BA_ "GenSigSendType" SG_ 643 HU_PDCAutoOnFunctionReq 1;
BA_ "GenSigEvent" SG_ 643 HU_FaceID_IVI "Y";
BA_ "GenSigSendType" SG_ 643 HU_FaceID_IVI 1;
BA_ "GenSigEvent" SG_ 643 FaceIDBindFaceReq "Y";
BA_ "GenSigSendType" SG_ 643 FaceIDBindFaceReq 1;
BA_ "GenSigEvent" SG_ 643 HU_AVPSuspendRequest "Y";
BA_ "GenSigSendType" SG_ 643 HU_AVPSuspendRequest 1;
BA_ "GenSigEvent" SG_ 643 HU_HPASuspendRequest "Y";
BA_ "GenSigSendType" SG_ 643 HU_HPASuspendRequest 1;
BA_ "GenSigEvent" SG_ 643 HU_AVPParkingLotPushFunctionReq "Y";
BA_ "GenSigSendType" SG_ 643 HU_AVPParkingLotPushFunctionReq 1;
BA_ "GenSigEvent" SG_ 643 HU_HPAFunctionReq "Y";
BA_ "GenSigSendType" SG_ 643 HU_HPAFunctionReq 1;
BA_ "GenSigEvent" SG_ 643 HU_AVPHazardWarningFunctionReq "Y";
BA_ "GenSigSendType" SG_ 643 HU_AVPHazardWarningFunctionReq 1;
BA_ "GenSigEvent" SG_ 643 HU_HPAHazardWarningFunctionReq "Y";
BA_ "GenSigSendType" SG_ 643 HU_HPAHazardWarningFunctionReq 1;
BA_ "GenSigEvent" SG_ 643 HU_AVPTypeReq "Y";
BA_ "GenSigSendType" SG_ 643 HU_AVPTypeReq 1;
BA_ "GenSigEvent" SG_ 643 HU_AVPSearchingTypeReq "Y";
BA_ "GenSigSendType" SG_ 643 HU_AVPSearchingTypeReq 1;
BA_ "GenSigEvent" SG_ 643 HU_HPATypeReq "Y";
BA_ "GenSigSendType" SG_ 643 HU_HPATypeReq 1;
BA_ "GenSigEvent" SG_ 643 HU_HPASearchingTypeReq "Y";
BA_ "GenSigSendType" SG_ 643 HU_HPASearchingTypeReq 1;
BA_ "GenSigEvent" SG_ 643 HU_HPAParkingLotPushFunctionReq "Y";
BA_ "GenSigSendType" SG_ 643 HU_HPAParkingLotPushFunctionReq 1;
BA_ "GenSigEvent" SG_ 643 HU_AVPFunctionTipConfirm "Y";
BA_ "GenSigSendType" SG_ 643 HU_AVPFunctionTipConfirm 1;
BA_ "GenSigEvent" SG_ 643 HU_HPAFunctionTipConfirm "Y";
BA_ "GenSigSendType" SG_ 643 HU_HPAFunctionTipConfirm 1;
BA_ "GenSigEvent" SG_ 643 HU_AVPFunctionCancelReq "Y";
BA_ "GenSigSendType" SG_ 643 HU_AVPFunctionCancelReq 1;
BA_ "GenSigEvent" SG_ 643 HU_HPAFunctionCancelReq "Y";
BA_ "GenSigSendType" SG_ 643 HU_HPAFunctionCancelReq 1;
BA_ "GenSigStartRemark" SG_ 648 CheckSum_HU_5 "V";
BA_ "GenSigEvent" SG_ 648 AVSFunctionReq "Y";
BA_ "GenSigSendType" SG_ 648 AVSFunctionReq 1;
BA_ "GenSigEvent" SG_ 648 AVSViewModeReq "Y";
BA_ "GenSigSendType" SG_ 648 AVSViewModeReq 1;
BA_ "GenSigEvent" SG_ 648 AVSFunctionExitReq "Y";
BA_ "GenSigSendType" SG_ 648 AVSFunctionExitReq 1;
BA_ "GenSigEvent" SG_ 648 AVSMonitoringVideoModeReq "Y";
BA_ "GenSigSendType" SG_ 648 AVSMonitoringVideoModeReq 1;
BA_ "GenSigEvent" SG_ 648 DynamicPGSReq "Y";
BA_ "GenSigSendType" SG_ 648 DynamicPGSReq 1;
BA_ "GenSigEvent" SG_ 648 MODReq "Y";
BA_ "GenSigSendType" SG_ 648 MODReq 1;
BA_ "GenSigEvent" SG_ 648 LanguageSet "Y";
BA_ "GenSigSendType" SG_ 648 LanguageSet 1;
BA_ "GenSigEvent" SG_ 648 SwitchScreenResponse_AVS "Y";
BA_ "GenSigSendType" SG_ 648 SwitchScreenResponse_AVS 1;
BA_ "GenSigEvent" SG_ 648 AVSViewtypeReq "Y";
BA_ "GenSigSendType" SG_ 648 AVSViewtypeReq 1;
BA_ "GenSigEvent" SG_ 648 HU_AVM_RemoteMonitoringSharpness "Y";
BA_ "GenSigSendType" SG_ 648 HU_AVM_RemoteMonitoringSharpness 1;
BA_ "SystemSignalLongSymbol" SG_ 648 HU_AVM_RemoteMonitoringSharpness "HU_AVM_RemoteMonitoringSharpnessSet";
BA_ "GenSigEvent" SG_ 648 HU_AVM_RemoteMonitoringIFrameReq "Y";
BA_ "GenSigSendType" SG_ 648 HU_AVM_RemoteMonitoringIFrameReq 1;
BA_ "GenSigEvent" SG_ 648 HU_RemoteMonitoringSt "Y";
BA_ "GenSigSendType" SG_ 648 HU_RemoteMonitoringSt 1;
BA_ "GenSigEvent" SG_ 650 TargetSelectionCenter_X "Y";
BA_ "GenSigSendType" SG_ 650 TargetSelectionCenter_X 1;
BA_ "GenSigInvalidRemark" SG_ 650 TargetSelectionCenter_X "2000";
BA_ "GenSigStartRemark" SG_ 650 TargetSelectionCenter_X "2000";
BA_ "GenSigInvalidValue" SG_ 650 TargetSelectionCenter_X 2047;
BA_ "GenSigStartValue" SG_ 650 TargetSelectionCenter_X 2046;
BA_ "GenSigEvent" SG_ 650 TargetSelection_Area "Y";
BA_ "GenSigSendType" SG_ 650 TargetSelection_Area 1;
BA_ "GenSigEvent" SG_ 650 TargetSelectionCenter_Y "Y";
BA_ "GenSigSendType" SG_ 650 TargetSelectionCenter_Y 1;
BA_ "GenSigInvalidRemark" SG_ 650 TargetSelectionCenter_Y "2000";
BA_ "GenSigStartRemark" SG_ 650 TargetSelectionCenter_Y "2000";
BA_ "GenSigInvalidValue" SG_ 650 TargetSelectionCenter_Y 2047;
BA_ "GenSigStartValue" SG_ 650 TargetSelectionCenter_Y 2046;
BA_ "GenSigEvent" SG_ 650 TargetSelectionCenter_Angle "Y";
BA_ "GenSigSendType" SG_ 650 TargetSelectionCenter_Angle 1;
BA_ "GenSigInvalidRemark" SG_ 650 TargetSelectionCenter_Angle "360";
BA_ "GenSigStartRemark" SG_ 650 TargetSelectionCenter_Angle "360";
BA_ "GenSigInvalidValue" SG_ 650 TargetSelectionCenter_Angle 1023;
BA_ "GenSigStartValue" SG_ 650 TargetSelectionCenter_Angle 1022;
BA_ "GenSigEvent" SG_ 650 TargetSelection_ParkType "Y";
BA_ "GenSigSendType" SG_ 650 TargetSelection_ParkType 1;
BA_ "GenSigEvent" SG_ 650 TargetSelection_ParkDirection "Y";
BA_ "GenSigSendType" SG_ 650 TargetSelection_ParkDirection 1;
BA_ "GenSigEvent" SG_ 650 TargetSelection_LineAngle "Y";
BA_ "GenSigSendType" SG_ 650 TargetSelection_LineAngle 1;
BA_ "GenSigInvalidRemark" SG_ 650 TargetSelection_LineAngle "360";
BA_ "GenSigStartRemark" SG_ 650 TargetSelection_LineAngle "360";
BA_ "GenSigInvalidValue" SG_ 650 TargetSelection_LineAngle 1023;
BA_ "GenSigStartValue" SG_ 650 TargetSelection_LineAngle 1022;
BA_ "GenSigEvent" SG_ 650 TargetSelection_ConfirmReq "Y";
BA_ "GenSigSendType" SG_ 650 TargetSelection_ConfirmReq 1;
BA_ "GenSigEvent" SG_ 650 APAFunctionReq "Y";
BA_ "GenSigSendType" SG_ 650 APAFunctionReq 1;
BA_ "GenSigEvent" SG_ 650 ParkInFunctionCancelReq "Y";
BA_ "GenSigSendType" SG_ 650 ParkInFunctionCancelReq 1;
BA_ "GenSigEvent" SG_ 650 ParkInSlotSearchModeSet "Y";
BA_ "GenSigSendType" SG_ 650 ParkInSlotSearchModeSet 1;
BA_ "GenSigEvent" SG_ 650 ParkOutDirection "Y";
BA_ "GenSigSendType" SG_ 650 ParkOutDirection 1;
BA_ "GenSigEvent" SG_ 650 ParkOutFunctionConfirmReq "Y";
BA_ "GenSigSendType" SG_ 650 ParkOutFunctionConfirmReq 1;
BA_ "GenSigEvent" SG_ 650 ParkOutFunctionCancelReq "Y";
BA_ "GenSigSendType" SG_ 650 ParkOutFunctionCancelReq 1;
BA_ "GenSigEvent" SG_ 650 ADBFunctionReq "Y";
BA_ "GenSigSendType" SG_ 650 ADBFunctionReq 1;
BA_ "GenSigStartRemark" SG_ 768 Checksum_BLE_DMH "V";
BA_ "GenSigInvalidRemark" SG_ 768 BLE_RemoteCtrlSteeringWheelAngle "O";
BA_ "GenSigInvalidValue" SG_ 768 BLE_RemoteCtrlSteeringWheelAngle 32767;
BA_ "SystemSignalLongSymbol" SG_ 768 BLE_RemoteCtrlSteeringWheelAngle "BLE_RemoteCtrlSteeringWheelAngleReq";
BA_ "SystemSignalLongSymbol" SG_ 768 BLE_RemoteCtrlSteeringWheel_0000 "BLE_RemoteCtrlSteeringWheelAngleSignReq";
BA_ "GenSigStartRemark" SG_ 652 Checksum_HU_Speech_1 "V";
BA_ "GenSigEvent" SG_ 652 HU_SpeechReq_AVS "Y";
BA_ "GenSigSendType" SG_ 652 HU_SpeechReq_AVS 1;
BA_ "GenSigEvent" SG_ 652 HU_SpeechReq_AVSViewMode "Y";
BA_ "GenSigSendType" SG_ 652 HU_SpeechReq_AVSViewMode 1;
BA_ "GenSigEvent" SG_ 652 HU_SpeechReq_PDC "Y";
BA_ "GenSigSendType" SG_ 652 HU_SpeechReq_PDC 1;
BA_ "GenSigEvent" SG_ 652 HU_SpeechReq_ParkOutTypeReq "Y";
BA_ "GenSigSendType" SG_ 652 HU_SpeechReq_ParkOutTypeReq 1;
BA_ "GenSigEvent" SG_ 652 HU_SpeechReq_AVPFunctionReq "Y";
BA_ "GenSigSendType" SG_ 652 HU_SpeechReq_AVPFunctionReq 1;
BA_ "GenSigEvent" SG_ 652 HU_SpeechReq_HPAFunctionReq "Y";
BA_ "GenSigSendType" SG_ 652 HU_SpeechReq_HPAFunctionReq 1;
BA_ "GenSigEvent" SG_ 652 HU_SpeechReq_APAFunctionReq "Y";
BA_ "GenSigSendType" SG_ 652 HU_SpeechReq_APAFunctionReq 1;
BA_ "GenSigEvent" SG_ 652 HU_SpeechReq_VAS "Y";
BA_ "GenSigSendType" SG_ 652 HU_SpeechReq_VAS 1;
BA_ "GenSigEvent" SG_ 652 HU_SpeechReq_TSR "Y";
BA_ "GenSigSendType" SG_ 652 HU_SpeechReq_TSR 1;
BA_ "GenSigEvent" SG_ 652 HU_SpeechReq_DSM "Y";
BA_ "GenSigSendType" SG_ 652 HU_SpeechReq_DSM 1;
BA_ "GenSigEvent" SG_ 652 HU_SpeechReq_ParkOutFuncReq "Y";
BA_ "GenSigSendType" SG_ 652 HU_SpeechReq_ParkOutFuncReq 1;
BA_ "GenSigEvent" SG_ 652 HU_SpeechReq_ParkInModeReq "Y";
BA_ "GenSigSendType" SG_ 652 HU_SpeechReq_ParkInModeReq 1;
BA_ "GenSigEvent" SG_ 652 HU_SpeechReq_ParkInTypeReq "Y";
BA_ "GenSigSendType" SG_ 652 HU_SpeechReq_ParkInTypeReq 1;
BA_ "GenSigInvalidRemark" SG_ 656 IndicationSpeed_IC "O";
BA_ "GenSigStartRemark" SG_ 656 IndicationSpeed_IC "O";
BA_ "GenSigInvalidValue" SG_ 656 IndicationSpeed_IC 255;
BA_ "GenSigStartValue" SG_ 656 IndicationSpeed_IC 254;
BA_ "GenSigInvalidRemark" SG_ 656 OdometerValue "O";
BA_ "GenSigStartRemark" SG_ 656 OdometerValue "L";
BA_ "GenSigInvalidValue" SG_ 656 OdometerValue 33554431;
BA_ "GenSigStartRemark" SG_ 418 Checksum_PEPS_DMH "V";
BA_ "GenSigEvent" SG_ 578 LuggageDoorSt "Y";
BA_ "GenSigSendType" SG_ 578 LuggageDoorSt 1;
BA_ "GenSigStartRemark" SG_ 528 ECAS_RequestLevel "L";
BA_ "GenSigInvalidValue" SG_ 528 ECAS_RequestLevel 7;
BA_ "GenSigStartRemark" SG_ 528 ECAS_ActualLevel "L";
BA_ "GenSigInvalidValue" SG_ 528 ECAS_ActualLevel 7;
BA_ "GenSigInvalidRemark" SG_ 432 ECAS_Height_FL "O";
BA_ "GenSigStartRemark" SG_ 432 ECAS_Height_FL "O";
BA_ "GenSigInvalidValue" SG_ 432 ECAS_Height_FL 255;
BA_ "GenSigStartValue" SG_ 432 ECAS_Height_FL 254;
BA_ "GenSigInvalidRemark" SG_ 432 ECAS_Height_FR "O";
BA_ "GenSigStartRemark" SG_ 432 ECAS_Height_FR "O";
BA_ "GenSigInvalidValue" SG_ 432 ECAS_Height_FR 255;
BA_ "GenSigStartValue" SG_ 432 ECAS_Height_FR 254;
BA_ "GenSigInvalidRemark" SG_ 432 ECAS_Height_RL "O";
BA_ "GenSigStartRemark" SG_ 432 ECAS_Height_RL "O";
BA_ "GenSigInvalidValue" SG_ 432 ECAS_Height_RL 255;
BA_ "GenSigStartValue" SG_ 432 ECAS_Height_RL 254;
BA_ "GenSigInvalidRemark" SG_ 432 ECAS_Height_RR "O";
BA_ "GenSigStartRemark" SG_ 432 ECAS_Height_RR "O";
BA_ "GenSigInvalidValue" SG_ 432 ECAS_Height_RR 255;
BA_ "GenSigStartValue" SG_ 432 ECAS_Height_RR 254;
BA_ "GenSigInvalidRemark" SG_ 529 AxleLoad_Front "2400";
BA_ "GenSigStartRemark" SG_ 529 AxleLoad_Front "2400";
BA_ "GenSigInvalidValue" SG_ 529 AxleLoad_Front 4095;
BA_ "GenSigStartValue" SG_ 529 AxleLoad_Front 4094;
BA_ "GenSigInvalidRemark" SG_ 529 AxleLoad_Rear "2400";
BA_ "GenSigStartRemark" SG_ 529 AxleLoad_Rear "2400";
BA_ "GenSigInvalidValue" SG_ 529 AxleLoad_Rear 4095;
BA_ "GenSigStartValue" SG_ 529 AxleLoad_Rear 4094;
BA_ "GenSigStartValue" SG_ 597 ADBL_Status 1;
BA_ "GenSigStartValue" SG_ 598 ADBR_Status 1;
BA_ "GenSigStartRemark" SG_ 614 Checksum_DSM_1 "V";
BA_ "GenSigEvent" SG_ 614 DSM_FatigueWarning "Y";
BA_ "GenSigSendType" SG_ 614 DSM_FatigueWarning 1;
BA_ "GenSigEvent" SG_ 614 DSM_DistractionWarning "Y";
BA_ "GenSigSendType" SG_ 614 DSM_DistractionWarning 1;
BA_ "GenSigEvent" SG_ 614 DSM_IntentionWarning "Y";
BA_ "GenSigSendType" SG_ 614 DSM_IntentionWarning 1;
BA_ "GenSigEvent" SG_ 614 DSM_FunctionalSafetyValidFlag "Y";
BA_ "GenSigSendType" SG_ 614 DSM_FunctionalSafetyValidFlag 1;
BA_ "GenSigEvent" SG_ 614 DSM_AutoDriveDataRecordStatus "Y";
BA_ "GenSigSendType" SG_ 614 DSM_AutoDriveDataRecordStatus 1;
BA_ "GenSigEvent" SG_ 614 DSM_AutoDriveDataRecordAvailable "Y";
BA_ "GenSigSendType" SG_ 614 DSM_AutoDriveDataRecordAvailable 1;
BA_ "GenSigEvent" SG_ 614 DSM_AttentionArea "Y";
BA_ "GenSigSendType" SG_ 614 DSM_AttentionArea 1;
BA_ "GenSigInvalidRemark" SG_ 614 DSM_AttentionArea "o";
BA_ "GenSigInvalidValue" SG_ 614 DSM_AttentionArea 15;
BA_ "GenSigEvent" SG_ 614 DSM_FaultSt "Y";
BA_ "GenSigSendType" SG_ 614 DSM_FaultSt 1;
BA_ "GenSigEvent" SG_ 614 DSM_Emotion "Y";
BA_ "GenSigSendType" SG_ 614 DSM_Emotion 1;
BA_ "GenSigInvalidValue" SG_ 614 DSM_Emotion 15;
BA_ "GenSigEvent" SG_ 614 DSM_WorkingSt "Y";
BA_ "GenSigSendType" SG_ 614 DSM_WorkingSt 1;
BA_ "GenSigStartRemark" SG_ 614 DSM_WorkingSt "L";
BA_ "GenSigEvent" SG_ 614 DSM_DSM_SpeechControlFeedback "Y";
BA_ "GenSigSendType" SG_ 614 DSM_DSM_SpeechControlFeedback 1;
BA_ "GenSigStartRemark" SG_ 614 DSM_CalibrationStatus "L";
BA_ "GenSigEvent" SG_ 614 DSM_FaceUnrecognizedTip "Y";
BA_ "GenSigSendType" SG_ 614 DSM_FaceUnrecognizedTip 1;
BA_ "GenSigStartRemark" SG_ 612 Checksum_DSM_2 "V";
BA_ "GenSigInvalidRemark" SG_ 612 AccountID_DSM "O";
BA_ "GenSigInvalidValue" SG_ 612 AccountID_DSM 15;
BA_ "GenSigInvalidRemark" SG_ 612 DSM_EyePosition_X "O";
BA_ "GenSigStartRemark" SG_ 612 DSM_EyePosition_X "O";
BA_ "GenSigInvalidValue" SG_ 612 DSM_EyePosition_X 255;
BA_ "GenSigStartValue" SG_ 612 DSM_EyePosition_X 254;
BA_ "GenSigInvalidRemark" SG_ 612 DSM_EyePosition_Y "O";
BA_ "GenSigStartRemark" SG_ 612 DSM_EyePosition_Y "O";
BA_ "GenSigInvalidValue" SG_ 612 DSM_EyePosition_Y 255;
BA_ "GenSigStartValue" SG_ 612 DSM_EyePosition_Y 254;
BA_ "GenSigInvalidRemark" SG_ 612 DSM_EyePosition_Z "O";
BA_ "GenSigStartRemark" SG_ 612 DSM_EyePosition_Z "O";
BA_ "GenSigInvalidValue" SG_ 612 DSM_EyePosition_Z 255;
BA_ "GenSigStartValue" SG_ 612 DSM_EyePosition_Z 254;
BA_ "GenSigStartRemark" SG_ 618 Checksum_FMradar_1 "V";
BA_ "GenSigStartRemark" SG_ 618 FMradar_FCTA_status "L";
BA_ "GenSigStartRemark" SG_ 618 FMradar_FCTB_status "L";
BA_ "GenSigStartRemark" SG_ 619 Checksum_FSradar_1 "V";
BA_ "GenSigStartRemark" SG_ 616 Checksum_LCDA_1 "V";
BA_ "GenSigEvent" SG_ 616 LCDA_WarningCmd_LCDA_Left "Y";
BA_ "GenSigSendType" SG_ 616 LCDA_WarningCmd_LCDA_Left 1;
BA_ "GenSigEvent" SG_ 616 LCDA_WarningCmd_LCDA_Right "Y";
BA_ "GenSigSendType" SG_ 616 LCDA_WarningCmd_LCDA_Right 1;
BA_ "GenSigEvent" SG_ 616 LCDA_WarningCmd_RCTA_left "Y";
BA_ "GenSigSendType" SG_ 616 LCDA_WarningCmd_RCTA_left 1;
BA_ "GenSigEvent" SG_ 616 LCDA_BuzzerCmd_RCTA_left "Y";
BA_ "GenSigSendType" SG_ 616 LCDA_BuzzerCmd_RCTA_left 1;
BA_ "GenSigEvent" SG_ 616 LCDA_WarningCmd_RCTA_Right "Y";
BA_ "GenSigSendType" SG_ 616 LCDA_WarningCmd_RCTA_Right 1;
BA_ "GenSigEvent" SG_ 616 LCDA_BuzzerCmd_RCTA_Right "Y";
BA_ "GenSigSendType" SG_ 616 LCDA_BuzzerCmd_RCTA_Right 1;
BA_ "GenSigEvent" SG_ 616 LCDA_WarningCmd_DOW_FL "Y";
BA_ "GenSigSendType" SG_ 616 LCDA_WarningCmd_DOW_FL 1;
BA_ "GenSigEvent" SG_ 616 LCDA_WarningCmd_DOW_FR "Y";
BA_ "GenSigSendType" SG_ 616 LCDA_WarningCmd_DOW_FR 1;
BA_ "GenSigEvent" SG_ 616 LCDA_WarningCmd_DOW_RL "Y";
BA_ "GenSigSendType" SG_ 616 LCDA_WarningCmd_DOW_RL 1;
BA_ "GenSigEvent" SG_ 616 LCDA_WarningCmd_DOW_RR "Y";
BA_ "GenSigSendType" SG_ 616 LCDA_WarningCmd_DOW_RR 1;
BA_ "GenSigEvent" SG_ 616 LCDA_WarningCmd_RCW "Y";
BA_ "GenSigSendType" SG_ 616 LCDA_WarningCmd_RCW 1;
BA_ "GenSigEvent" SG_ 616 LCDA_WorkingSt_DOW "Y";
BA_ "GenSigSendType" SG_ 616 LCDA_WorkingSt_DOW 1;
BA_ "GenSigEvent" SG_ 616 LCDA_Blockage_RR "Y";
BA_ "GenSigSendType" SG_ 616 LCDA_Blockage_RR 1;
BA_ "GenSigStartRemark" SG_ 616 LCDA_WorkingSt_RCTB "L";
BA_REL_ "GenSigTimeoutTime" BU_SG_REL_ ADV SG_ 457 Checksum_PDC_12 500;
BA_REL_ "GenSigTimeoutTime" BU_SG_REL_ AVP SG_ 457 Checksum_PDC_12 500;
BA_REL_ "GenSigTimeoutTime" BU_SG_REL_ AVM SG_ 457 Checksum_PDC_12 500;
BA_REL_ "GenSigTimeoutTime" BU_SG_REL_ ADV SG_ 457 ACoordinateY_Right 500;
BA_REL_ "GenSigTimeoutTime" BU_SG_REL_ AVP SG_ 457 ACoordinateY_Right 500;
BA_REL_ "GenSigTimeoutTime" BU_SG_REL_ AVM SG_ 457 ACoordinateY_Right 500;
BA_REL_ "GenSigTimeoutTime" BU_SG_REL_ ADV SG_ 457 ACoordinateX_Right 500;
BA_REL_ "GenSigTimeoutTime" BU_SG_REL_ AVP SG_ 457 ACoordinateX_Right 500;
BA_REL_ "GenSigTimeoutTime" BU_SG_REL_ AVM SG_ 457 ACoordinateX_Right 500;
BA_REL_ "GenSigTimeoutTime" BU_SG_REL_ ADV SG_ 457 BCoordinateY_Right 500;
BA_REL_ "GenSigTimeoutTime" BU_SG_REL_ AVP SG_ 457 BCoordinateY_Right 500;
BA_REL_ "GenSigTimeoutTime" BU_SG_REL_ AVM SG_ 457 BCoordinateY_Right 500;
BA_REL_ "GenSigTimeoutTime" BU_SG_REL_ ADV SG_ 457 BCoordinateX_Right 500;
BA_REL_ "GenSigTimeoutTime" BU_SG_REL_ AVP SG_ 457 BCoordinateX_Right 500;
BA_REL_ "GenSigTimeoutTime" BU_SG_REL_ AVM SG_ 457 BCoordinateX_Right 500;
BA_REL_ "GenSigTimeoutTime" BU_SG_REL_ ADV SG_ 457 LiveCounter_PDC_12 500;
BA_REL_ "GenSigTimeoutTime" BU_SG_REL_ AVP SG_ 457 LiveCounter_PDC_12 500;
BA_REL_ "GenSigTimeoutTime" BU_SG_REL_ AVM SG_ 457 LiveCounter_PDC_12 500;
BA_REL_ "GenSigTimeoutTime" BU_SG_REL_ ADV SG_ 458 Checksum_PDC_13 500;
BA_REL_ "GenSigTimeoutTime" BU_SG_REL_ AVP SG_ 458 Checksum_PDC_13 500;
BA_REL_ "GenSigTimeoutTime" BU_SG_REL_ AVM SG_ 458 Checksum_PDC_13 500;
BA_REL_ "GenSigTimeoutTime" BU_SG_REL_ ADV SG_ 458 CCoordinateY_Right 500;
BA_REL_ "GenSigTimeoutTime" BU_SG_REL_ AVP SG_ 458 CCoordinateY_Right 500;
BA_REL_ "GenSigTimeoutTime" BU_SG_REL_ AVM SG_ 458 CCoordinateY_Right 500;
BA_REL_ "GenSigTimeoutTime" BU_SG_REL_ ADV SG_ 458 CCoordinateX_Right 500;
BA_REL_ "GenSigTimeoutTime" BU_SG_REL_ AVP SG_ 458 CCoordinateX_Right 500;
BA_REL_ "GenSigTimeoutTime" BU_SG_REL_ AVM SG_ 458 CCoordinateX_Right 500;
BA_REL_ "GenSigTimeoutTime" BU_SG_REL_ ADV SG_ 458 DCoordinateY_Right 500;
BA_REL_ "GenSigTimeoutTime" BU_SG_REL_ AVP SG_ 458 DCoordinateY_Right 500;
BA_REL_ "GenSigTimeoutTime" BU_SG_REL_ AVM SG_ 458 DCoordinateY_Right 500;
BA_REL_ "GenSigTimeoutTime" BU_SG_REL_ ADV SG_ 458 DCoordinateX_Right 500;
BA_REL_ "GenSigTimeoutTime" BU_SG_REL_ AVP SG_ 458 DCoordinateX_Right 500;
BA_REL_ "GenSigTimeoutTime" BU_SG_REL_ AVM SG_ 458 DCoordinateX_Right 500;
BA_REL_ "GenSigTimeoutTime" BU_SG_REL_ ADV SG_ 458 LiveCounter_PDC_13 500;
BA_REL_ "GenSigTimeoutTime" BU_SG_REL_ AVP SG_ 458 LiveCounter_PDC_13 500;
BA_REL_ "GenSigTimeoutTime" BU_SG_REL_ AVM SG_ 458 LiveCounter_PDC_13 500;
BA_REL_ "GenSigTimeoutTime" BU_SG_REL_ ADV SG_ 455 Checksum_PDC_10 500;
BA_REL_ "GenSigTimeoutTime" BU_SG_REL_ AVP SG_ 455 Checksum_PDC_10 500;
BA_REL_ "GenSigTimeoutTime" BU_SG_REL_ AVM SG_ 455 Checksum_PDC_10 500;
BA_REL_ "GenSigTimeoutTime" BU_SG_REL_ ADV SG_ 455 DistanceValue_RLS 500;
BA_REL_ "GenSigTimeoutTime" BU_SG_REL_ AVP SG_ 455 DistanceValue_RLS 500;
BA_REL_ "GenSigTimeoutTime" BU_SG_REL_ AVM SG_ 455 DistanceValue_RLS 500;
BA_REL_ "GenSigTimeoutTime" BU_SG_REL_ ADV SG_ 455 DistanceValue_RRS 500;
BA_REL_ "GenSigTimeoutTime" BU_SG_REL_ AVP SG_ 455 DistanceValue_RRS 500;
BA_REL_ "GenSigTimeoutTime" BU_SG_REL_ AVM SG_ 455 DistanceValue_RRS 500;
BA_REL_ "GenSigTimeoutTime" BU_SG_REL_ ADV SG_ 455 TimeStamp_RLS_RRS 500;
BA_REL_ "GenSigTimeoutTime" BU_SG_REL_ AVP SG_ 455 TimeStamp_RLS_RRS 500;
BA_REL_ "GenSigTimeoutTime" BU_SG_REL_ AVM SG_ 455 TimeStamp_RLS_RRS 500;
BA_REL_ "GenSigTimeoutTime" BU_SG_REL_ AVP SG_ 455 ParkingSlotDepth_Right 500;
BA_REL_ "GenSigTimeoutTime" BU_SG_REL_ AVM SG_ 455 ParkingSlotDepth_Right 500;
BA_REL_ "GenSigTimeoutTime" BU_SG_REL_ ADV SG_ 455 LiveCounter_PDC_10 500;
BA_REL_ "GenSigTimeoutTime" BU_SG_REL_ AVP SG_ 455 LiveCounter_PDC_10 500;
BA_REL_ "GenSigTimeoutTime" BU_SG_REL_ AVM SG_ 455 LiveCounter_PDC_10 500;
BA_REL_ "GenSigTimeoutTime" BU_SG_REL_ Gateway SG_ 388 APS_Slot1_DetectStatus 1000;
BA_REL_ "GenSigTimeoutTime" BU_SG_REL_ ADV SG_ 388 APS_Slot1_DetectStatus 1000;
BA_REL_ "GenSigTimeoutTime" BU_SG_REL_ Gateway SG_ 388 APS_Slot1_Info 1000;
BA_REL_ "GenSigTimeoutTime" BU_SG_REL_ ADV SG_ 388 APS_Slot1_Info 1000;
BA_REL_ "GenSigTimeoutTime" BU_SG_REL_ Gateway SG_ 388 APS_Slot1_ParkType 1000;
BA_REL_ "GenSigTimeoutTime" BU_SG_REL_ ADV SG_ 388 APS_Slot1_ParkType 1000;
BA_REL_ "GenSigTimeoutTime" BU_SG_REL_ Gateway SG_ 388 APS_Slot1_ParkDirection 1000;
BA_REL_ "GenSigTimeoutTime" BU_SG_REL_ ADV SG_ 388 APS_Slot1_ParkDirection 1000;
BA_REL_ "GenSigTimeoutTime" BU_SG_REL_ Gateway SG_ 388 APS_Slot2_DetectStatus 1000;
BA_REL_ "GenSigTimeoutTime" BU_SG_REL_ ADV SG_ 388 APS_Slot2_DetectStatus 1000;
BA_REL_ "GenSigTimeoutTime" BU_SG_REL_ Gateway SG_ 388 APS_Slot2_Info 1000;
BA_REL_ "GenSigTimeoutTime" BU_SG_REL_ ADV SG_ 388 APS_Slot2_Info 1000;
BA_REL_ "GenSigTimeoutTime" BU_SG_REL_ Gateway SG_ 388 APS_Slot2_ParkType 1000;
BA_REL_ "GenSigTimeoutTime" BU_SG_REL_ ADV SG_ 388 APS_Slot2_ParkType 1000;
BA_REL_ "GenSigTimeoutTime" BU_SG_REL_ Gateway SG_ 388 APS_Slot2_ParkDirection 1000;
BA_REL_ "GenSigTimeoutTime" BU_SG_REL_ ADV SG_ 388 APS_Slot2_ParkDirection 1000;
BA_REL_ "GenSigTimeoutTime" BU_SG_REL_ Gateway SG_ 388 APS_Slot3_DetectStatus 1000;
BA_REL_ "GenSigTimeoutTime" BU_SG_REL_ ADV SG_ 388 APS_Slot3_DetectStatus 1000;
BA_REL_ "GenSigTimeoutTime" BU_SG_REL_ Gateway SG_ 388 APS_Slot3_Info 1000;
BA_REL_ "GenSigTimeoutTime" BU_SG_REL_ ADV SG_ 388 APS_Slot3_Info 1000;
BA_REL_ "GenSigTimeoutTime" BU_SG_REL_ Gateway SG_ 388 APS_Slot3_ParkType 1000;
BA_REL_ "GenSigTimeoutTime" BU_SG_REL_ ADV SG_ 388 APS_Slot3_ParkType 1000;
BA_REL_ "GenSigTimeoutTime" BU_SG_REL_ Gateway SG_ 388 APS_Slot3_ParkDirection 1000;
BA_REL_ "GenSigTimeoutTime" BU_SG_REL_ ADV SG_ 388 APS_Slot3_ParkDirection 1000;
BA_REL_ "GenSigTimeoutTime" BU_SG_REL_ Gateway SG_ 388 APS_Slot4_DetectStatus 1000;
BA_REL_ "GenSigTimeoutTime" BU_SG_REL_ ADV SG_ 388 APS_Slot4_DetectStatus 1000;
BA_REL_ "GenSigTimeoutTime" BU_SG_REL_ Gateway SG_ 388 APS_Slot4_Info 1000;
BA_REL_ "GenSigTimeoutTime" BU_SG_REL_ ADV SG_ 388 APS_Slot4_Info 1000;
BA_REL_ "GenSigTimeoutTime" BU_SG_REL_ Gateway SG_ 388 APS_Slot4_ParkType 1000;
BA_REL_ "GenSigTimeoutTime" BU_SG_REL_ ADV SG_ 388 APS_Slot4_ParkType 1000;
BA_REL_ "GenSigTimeoutTime" BU_SG_REL_ Gateway SG_ 388 APS_Slot4_ParkDirection 1000;
BA_REL_ "GenSigTimeoutTime" BU_SG_REL_ ADV SG_ 388 APS_Slot4_ParkDirection 1000;
BA_REL_ "GenSigTimeoutTime" BU_SG_REL_ Gateway SG_ 388 APS_Slot5_DetectStatus 1000;
BA_REL_ "GenSigTimeoutTime" BU_SG_REL_ ADV SG_ 388 APS_Slot5_DetectStatus 1000;
BA_REL_ "GenSigTimeoutTime" BU_SG_REL_ Gateway SG_ 388 APS_Slot5_Info 1000;
BA_REL_ "GenSigTimeoutTime" BU_SG_REL_ ADV SG_ 388 APS_Slot5_Info 1000;
BA_REL_ "GenSigTimeoutTime" BU_SG_REL_ Gateway SG_ 388 APS_Slot5_ParkType 1000;
BA_REL_ "GenSigTimeoutTime" BU_SG_REL_ ADV SG_ 388 APS_Slot5_ParkType 1000;
BA_REL_ "GenSigTimeoutTime" BU_SG_REL_ Gateway SG_ 388 APS_Slot5_ParkDirection 1000;
BA_REL_ "GenSigTimeoutTime" BU_SG_REL_ ADV SG_ 388 APS_Slot5_ParkDirection 1000;
BA_REL_ "GenSigTimeoutTime" BU_SG_REL_ Gateway SG_ 388 APS_Slot6_DetectStatus 1000;
BA_REL_ "GenSigTimeoutTime" BU_SG_REL_ ADV SG_ 388 APS_Slot6_DetectStatus 1000;
BA_REL_ "GenSigTimeoutTime" BU_SG_REL_ Gateway SG_ 388 APS_Slot6_Info 1000;
BA_REL_ "GenSigTimeoutTime" BU_SG_REL_ ADV SG_ 388 APS_Slot6_Info 1000;
BA_REL_ "GenSigTimeoutTime" BU_SG_REL_ Gateway SG_ 388 APS_Slot6_ParkType 1000;
BA_REL_ "GenSigTimeoutTime" BU_SG_REL_ ADV SG_ 388 APS_Slot6_ParkType 1000;
BA_REL_ "GenSigTimeoutTime" BU_SG_REL_ Gateway SG_ 388 APS_Slot6_ParkDirection 1000;
BA_REL_ "GenSigTimeoutTime" BU_SG_REL_ ADV SG_ 388 APS_Slot6_ParkDirection 1000;
BA_REL_ "GenSigTimeoutTime" BU_SG_REL_ Gateway SG_ 388 APS_ParkingSlotAvailability 1000;
BA_REL_ "GenSigTimeoutTime" BU_SG_REL_ ADV SG_ 388 APS_ParkingSlotAvailability 1000;
BA_REL_ "GenSigTimeoutTime" BU_SG_REL_ Gateway SG_ 390 APS_Slot1CenterPoint_X1 1000;
BA_REL_ "GenSigTimeoutTime" BU_SG_REL_ ADV SG_ 390 APS_Slot1CenterPoint_X1 1000;
BA_REL_ "GenSigTimeoutTime" BU_SG_REL_ Gateway SG_ 390 APS_Slot1CenterPoint_Y1 1000;
BA_REL_ "GenSigTimeoutTime" BU_SG_REL_ ADV SG_ 390 APS_Slot1CenterPoint_Y1 1000;
BA_REL_ "GenSigTimeoutTime" BU_SG_REL_ Gateway SG_ 390 APS_Slot1_LineAngle 1000;
BA_REL_ "GenSigTimeoutTime" BU_SG_REL_ ADV SG_ 390 APS_Slot1_LineAngle 1000;
BA_REL_ "GenSigTimeoutTime" BU_SG_REL_ Gateway SG_ 390 APS_Slot1_Length 1000;
BA_REL_ "GenSigTimeoutTime" BU_SG_REL_ ADV SG_ 390 APS_Slot1_Length 1000;
BA_REL_ "GenSigTimeoutTime" BU_SG_REL_ Gateway SG_ 390 APS_Slot1_Width 1000;
BA_REL_ "GenSigTimeoutTime" BU_SG_REL_ ADV SG_ 390 APS_Slot1_Width 1000;
BA_REL_ "GenSigTimeoutTime" BU_SG_REL_ Gateway SG_ 391 APS_Slot2CenterPoint_X1 1000;
BA_REL_ "GenSigTimeoutTime" BU_SG_REL_ ADV SG_ 391 APS_Slot2CenterPoint_X1 1000;
BA_REL_ "GenSigTimeoutTime" BU_SG_REL_ Gateway SG_ 391 APS_Slot2CenterPoint_Y1 1000;
BA_REL_ "GenSigTimeoutTime" BU_SG_REL_ ADV SG_ 391 APS_Slot2CenterPoint_Y1 1000;
BA_REL_ "GenSigTimeoutTime" BU_SG_REL_ Gateway SG_ 391 APS_Slot2_LineAngle 1000;
BA_REL_ "GenSigTimeoutTime" BU_SG_REL_ ADV SG_ 391 APS_Slot2_LineAngle 1000;
BA_REL_ "GenSigTimeoutTime" BU_SG_REL_ Gateway SG_ 391 APS_Slot2_Length 1000;
BA_REL_ "GenSigTimeoutTime" BU_SG_REL_ ADV SG_ 391 APS_Slot2_Length 1000;
BA_REL_ "GenSigTimeoutTime" BU_SG_REL_ Gateway SG_ 391 APS_Slot2_Width 1000;
BA_REL_ "GenSigTimeoutTime" BU_SG_REL_ ADV SG_ 391 APS_Slot2_Width 1000;
BA_REL_ "GenSigTimeoutTime" BU_SG_REL_ Gateway SG_ 392 APS_Slot3CenterPoint_X1 1000;
BA_REL_ "GenSigTimeoutTime" BU_SG_REL_ ADV SG_ 392 APS_Slot3CenterPoint_X1 1000;
BA_REL_ "GenSigTimeoutTime" BU_SG_REL_ Gateway SG_ 392 APS_Slot3CenterPoint_Y1 1000;
BA_REL_ "GenSigTimeoutTime" BU_SG_REL_ ADV SG_ 392 APS_Slot3CenterPoint_Y1 1000;
BA_REL_ "GenSigTimeoutTime" BU_SG_REL_ Gateway SG_ 392 APS_Slot3_LineAngle 1000;
BA_REL_ "GenSigTimeoutTime" BU_SG_REL_ ADV SG_ 392 APS_Slot3_LineAngle 1000;
BA_REL_ "GenSigTimeoutTime" BU_SG_REL_ Gateway SG_ 392 APS_Slot3_Length 1000;
BA_REL_ "GenSigTimeoutTime" BU_SG_REL_ ADV SG_ 392 APS_Slot3_Length 1000;
BA_REL_ "GenSigTimeoutTime" BU_SG_REL_ Gateway SG_ 392 APS_Slot3_Width 1000;
BA_REL_ "GenSigTimeoutTime" BU_SG_REL_ ADV SG_ 392 APS_Slot3_Width 1000;
BA_REL_ "GenSigTimeoutTime" BU_SG_REL_ Gateway SG_ 393 APS_Slot4CenterPoint_X1 1000;
BA_REL_ "GenSigTimeoutTime" BU_SG_REL_ ADV SG_ 393 APS_Slot4CenterPoint_X1 1000;
BA_REL_ "GenSigTimeoutTime" BU_SG_REL_ Gateway SG_ 393 APS_Slot4CenterPoint_Y1 1000;
BA_REL_ "GenSigTimeoutTime" BU_SG_REL_ ADV SG_ 393 APS_Slot4CenterPoint_Y1 1000;
BA_REL_ "GenSigTimeoutTime" BU_SG_REL_ Gateway SG_ 393 APS_Slot4_LineAngle 1000;
BA_REL_ "GenSigTimeoutTime" BU_SG_REL_ ADV SG_ 393 APS_Slot4_LineAngle 1000;
BA_REL_ "GenSigTimeoutTime" BU_SG_REL_ Gateway SG_ 393 APS_Slot4_Length 1000;
BA_REL_ "GenSigTimeoutTime" BU_SG_REL_ ADV SG_ 393 APS_Slot4_Length 1000;
BA_REL_ "GenSigTimeoutTime" BU_SG_REL_ Gateway SG_ 393 APS_Slot4_Width 1000;
BA_REL_ "GenSigTimeoutTime" BU_SG_REL_ ADV SG_ 393 APS_Slot4_Width 1000;
BA_REL_ "GenSigTimeoutTime" BU_SG_REL_ Gateway SG_ 394 APS_Slot5CenterPoint_X1 1000;
BA_REL_ "GenSigTimeoutTime" BU_SG_REL_ ADV SG_ 394 APS_Slot5CenterPoint_X1 1000;
BA_REL_ "GenSigTimeoutTime" BU_SG_REL_ Gateway SG_ 394 APS_Slot5CenterPoint_Y1 1000;
BA_REL_ "GenSigTimeoutTime" BU_SG_REL_ ADV SG_ 394 APS_Slot5CenterPoint_Y1 1000;
BA_REL_ "GenSigTimeoutTime" BU_SG_REL_ Gateway SG_ 394 APS_Slot5_LineAngle 1000;
BA_REL_ "GenSigTimeoutTime" BU_SG_REL_ ADV SG_ 394 APS_Slot5_LineAngle 1000;
BA_REL_ "GenSigTimeoutTime" BU_SG_REL_ Gateway SG_ 394 APS_Slot5_Length 1000;
BA_REL_ "GenSigTimeoutTime" BU_SG_REL_ ADV SG_ 394 APS_Slot5_Length 1000;
BA_REL_ "GenSigTimeoutTime" BU_SG_REL_ Gateway SG_ 394 APS_Slot5_Width 1000;
BA_REL_ "GenSigTimeoutTime" BU_SG_REL_ ADV SG_ 394 APS_Slot5_Width 1000;
BA_REL_ "GenSigTimeoutTime" BU_SG_REL_ Gateway SG_ 395 APS_Slot6CenterPoint_X1 1000;
BA_REL_ "GenSigTimeoutTime" BU_SG_REL_ ADV SG_ 395 APS_Slot6CenterPoint_X1 1000;
BA_REL_ "GenSigTimeoutTime" BU_SG_REL_ Gateway SG_ 395 APS_Slot6CenterPoint_Y1 1000;
BA_REL_ "GenSigTimeoutTime" BU_SG_REL_ ADV SG_ 395 APS_Slot6CenterPoint_Y1 1000;
BA_REL_ "GenSigTimeoutTime" BU_SG_REL_ Gateway SG_ 395 APS_Slot6_LineAngle 1000;
BA_REL_ "GenSigTimeoutTime" BU_SG_REL_ ADV SG_ 395 APS_Slot6_LineAngle 1000;
BA_REL_ "GenSigTimeoutTime" BU_SG_REL_ Gateway SG_ 395 APS_Slot6_Length 1000;
BA_REL_ "GenSigTimeoutTime" BU_SG_REL_ ADV SG_ 395 APS_Slot6_Length 1000;
BA_REL_ "GenSigTimeoutTime" BU_SG_REL_ Gateway SG_ 395 APS_Slot6_Width 1000;
BA_REL_ "GenSigTimeoutTime" BU_SG_REL_ ADV SG_ 395 APS_Slot6_Width 1000;
BA_REL_ "GenSigTimeoutTime" BU_SG_REL_ Gateway SG_ 384 ADV_PathTracingCenter_X 300;
BA_REL_ "GenSigTimeoutTime" BU_SG_REL_ AVP SG_ 384 ADV_PathTracingCenter_X 300;
BA_REL_ "GenSigTimeoutTime" BU_SG_REL_ AVM SG_ 384 ADV_PathTracingCenter_X 300;
BA_REL_ "GenSigTimeoutTime" BU_SG_REL_ Gateway SG_ 384 ADV_PathTracingCenter_Y 300;
BA_REL_ "GenSigTimeoutTime" BU_SG_REL_ AVP SG_ 384 ADV_PathTracingCenter_Y 300;
BA_REL_ "GenSigTimeoutTime" BU_SG_REL_ AVM SG_ 384 ADV_PathTracingCenter_Y 300;
BA_REL_ "GenSigTimeoutTime" BU_SG_REL_ Gateway SG_ 384 ADV_PathTracingAngle 300;
BA_REL_ "GenSigTimeoutTime" BU_SG_REL_ AVP SG_ 384 ADV_PathTracingAngle 300;
BA_REL_ "GenSigTimeoutTime" BU_SG_REL_ AVM SG_ 384 ADV_PathTracingAngle 300;
BA_REL_ "GenSigTimeoutTime" BU_SG_REL_ Gateway SG_ 384 ADV_ShortestDistance 300;
BA_REL_ "GenSigTimeoutTime" BU_SG_REL_ AVP SG_ 384 ADV_ShortestDistance 300;
BA_REL_ "GenSigTimeoutTime" BU_SG_REL_ AVM SG_ 384 ADV_ShortestDistance 300;
BA_REL_ "GenSigTimeoutTime" BU_SG_REL_ Gateway SG_ 384 ADV_TotalPathNumber 300;
BA_REL_ "GenSigTimeoutTime" BU_SG_REL_ AVP SG_ 384 ADV_TotalPathNumber 300;
BA_REL_ "GenSigTimeoutTime" BU_SG_REL_ AVM SG_ 384 ADV_TotalPathNumber 300;
BA_REL_ "GenSigTimeoutTime" BU_SG_REL_ Gateway SG_ 384 ADV_CurrentPathNumber 300;
BA_REL_ "GenSigTimeoutTime" BU_SG_REL_ AVP SG_ 384 ADV_CurrentPathNumber 300;
BA_REL_ "GenSigTimeoutTime" BU_SG_REL_ AVM SG_ 384 ADV_CurrentPathNumber 300;
BA_REL_ "GenSigTimeoutTime" BU_SG_REL_ Gateway SG_ 384 ADV_CurrentDirection 300;
BA_REL_ "GenSigTimeoutTime" BU_SG_REL_ AVP SG_ 384 ADV_CurrentDirection 300;
BA_REL_ "GenSigTimeoutTime" BU_SG_REL_ AVM SG_ 384 ADV_CurrentDirection 300;
BA_REL_ "GenSigTimeoutTime" BU_SG_REL_ Gateway SG_ 384 ADV_RemainingDistance 300;
BA_REL_ "GenSigTimeoutTime" BU_SG_REL_ AVP SG_ 384 ADV_RemainingDistance 300;
BA_REL_ "GenSigTimeoutTime" BU_SG_REL_ AVM SG_ 384 ADV_RemainingDistance 300;
BA_REL_ "GenSigTimeoutTime" BU_SG_REL_ Gateway SG_ 386 ADV_TargetTracingCenter_X 300;
BA_REL_ "GenSigTimeoutTime" BU_SG_REL_ AVP SG_ 386 ADV_TargetTracingCenter_X 300;
BA_REL_ "GenSigTimeoutTime" BU_SG_REL_ AVM SG_ 386 ADV_TargetTracingCenter_X 300;
BA_REL_ "GenSigTimeoutTime" BU_SG_REL_ Gateway SG_ 386 ADV_TargetTracingCenter_Y 300;
BA_REL_ "GenSigTimeoutTime" BU_SG_REL_ AVP SG_ 386 ADV_TargetTracingCenter_Y 300;
BA_REL_ "GenSigTimeoutTime" BU_SG_REL_ AVM SG_ 386 ADV_TargetTracingCenter_Y 300;
BA_REL_ "GenSigTimeoutTime" BU_SG_REL_ Gateway SG_ 386 ADV_TargetTracingAngle 300;
BA_REL_ "GenSigTimeoutTime" BU_SG_REL_ AVP SG_ 386 ADV_TargetTracingAngle 300;
BA_REL_ "GenSigTimeoutTime" BU_SG_REL_ AVM SG_ 386 ADV_TargetTracingAngle 300;
BA_REL_ "GenSigTimeoutTime" BU_SG_REL_ CDS1 SG_ 546 AmbientTemp 1000;
BA_REL_ "GenSigTimeoutTime" BU_SG_REL_ CDS2 SG_ 546 AmbientTemp 1000;
BA_REL_ "GenSigTimeoutTime" BU_SG_REL_ AVP SG_ 546 AmbientTemp 1000;
BA_REL_ "GenSigTimeoutTime" BU_SG_REL_ AVM SG_ 546 AmbientTemp 1000;
BA_REL_ "GenSigTimeoutTime" BU_SG_REL_ PDC SG_ 546 AmbientTemp 1000;
BA_REL_ "GenSigTimeoutTime" BU_SG_REL_ CDS1 SG_ 560 PositionLightSt 1000;
BA_REL_ "GenSigTimeoutTime" BU_SG_REL_ ADV SG_ 560 PositionLightSt 1000;
BA_REL_ "GenSigTimeoutTime" BU_SG_REL_ IRC SG_ 560 PositionLightSt 1000;
BA_REL_ "GenSigTimeoutTime" BU_SG_REL_ CDS1 SG_ 560 LowBeamSt 1000;
BA_REL_ "GenSigTimeoutTime" BU_SG_REL_ CDS2 SG_ 560 LowBeamSt 1000;
BA_REL_ "GenSigTimeoutTime" BU_SG_REL_ IRC SG_ 560 LowBeamSt 1000;
BA_REL_ "GenSigTimeoutTime" BU_SG_REL_ DSM SG_ 560 LowBeamSt 1000;
BA_REL_ "GenSigTimeoutTime" BU_SG_REL_ AVP SG_ 560 LowBeamSt_FL 1000;
BA_REL_ "GenSigTimeoutTime" BU_SG_REL_ AVM SG_ 560 LowBeamSt_FL 1000;
BA_REL_ "GenSigTimeoutTime" BU_SG_REL_ ADB1 SG_ 560 LowBeamSt_FL 1000;
BA_REL_ "GenSigTimeoutTime" BU_SG_REL_ ADB2 SG_ 560 LowBeamSt_FL 1000;
BA_REL_ "GenSigTimeoutTime" BU_SG_REL_ AVP SG_ 560 LowBeamSt_FR 1000;
BA_REL_ "GenSigTimeoutTime" BU_SG_REL_ AVM SG_ 560 LowBeamSt_FR 1000;
BA_REL_ "GenSigTimeoutTime" BU_SG_REL_ ADB1 SG_ 560 LowBeamSt_FR 1000;
BA_REL_ "GenSigTimeoutTime" BU_SG_REL_ ADB2 SG_ 560 LowBeamSt_FR 1000;
BA_REL_ "GenSigTimeoutTime" BU_SG_REL_ CDS1 SG_ 560 HighBeamSt 1000;
BA_REL_ "GenSigTimeoutTime" BU_SG_REL_ CDS2 SG_ 560 HighBeamSt 1000;
BA_REL_ "GenSigTimeoutTime" BU_SG_REL_ IRC SG_ 560 HighBeamSt 1000;
BA_REL_ "GenSigTimeoutTime" BU_SG_REL_ DSM SG_ 560 HighBeamSt 1000;
BA_REL_ "GenSigTimeoutTime" BU_SG_REL_ AVP SG_ 560 HighBeamSt_FL 1000;
BA_REL_ "GenSigTimeoutTime" BU_SG_REL_ AVM SG_ 560 HighBeamSt_FL 1000;
BA_REL_ "GenSigTimeoutTime" BU_SG_REL_ AVP SG_ 560 HighBeamSt_FR 1000;
BA_REL_ "GenSigTimeoutTime" BU_SG_REL_ AVM SG_ 560 HighBeamSt_FR 1000;
BA_REL_ "GenSigTimeoutTime" BU_SG_REL_ CDS1 SG_ 560 AutoLightMode 1000;
BA_REL_ "GenSigTimeoutTime" BU_SG_REL_ CDS2 SG_ 560 AutoLightMode 1000;
BA_REL_ "GenSigTimeoutTime" BU_SG_REL_ AVP SG_ 560 AutoLightMode 1000;
BA_REL_ "GenSigTimeoutTime" BU_SG_REL_ AVM SG_ 560 AutoLightMode 1000;
BA_REL_ "GenSigTimeoutTime" BU_SG_REL_ ADB1 SG_ 560 AutoLightMode 1000;
BA_REL_ "GenSigTimeoutTime" BU_SG_REL_ ADB2 SG_ 560 AutoLightMode 1000;
BA_REL_ "GenSigTimeoutTime" BU_SG_REL_ CDS1 SG_ 560 TurningSt_Left 1000;
BA_REL_ "GenSigTimeoutTime" BU_SG_REL_ CDS2 SG_ 560 TurningSt_Left 1000;
BA_REL_ "GenSigTimeoutTime" BU_SG_REL_ ADV SG_ 560 TurningSt_Left 1000;
BA_REL_ "GenSigTimeoutTime" BU_SG_REL_ IRC SG_ 560 TurningSt_Left 1000;
BA_REL_ "GenSigTimeoutTime" BU_SG_REL_ AVP SG_ 560 TurningSt_Left 1000;
BA_REL_ "GenSigTimeoutTime" BU_SG_REL_ AVM SG_ 560 TurningSt_Left 1000;
BA_REL_ "GenSigTimeoutTime" BU_SG_REL_ LCDA1 SG_ 560 TurningSt_Left 1000;
BA_REL_ "GenSigTimeoutTime" BU_SG_REL_ LCDA2 SG_ 560 TurningSt_Left 1000;
BA_REL_ "GenSigTimeoutTime" BU_SG_REL_ CDS1 SG_ 560 TurningSt_right 1000;
BA_REL_ "GenSigTimeoutTime" BU_SG_REL_ CDS2 SG_ 560 TurningSt_right 1000;
BA_REL_ "GenSigTimeoutTime" BU_SG_REL_ ADV SG_ 560 TurningSt_right 1000;
BA_REL_ "GenSigTimeoutTime" BU_SG_REL_ IRC SG_ 560 TurningSt_right 1000;
BA_REL_ "GenSigTimeoutTime" BU_SG_REL_ AVP SG_ 560 TurningSt_right 1000;
BA_REL_ "GenSigTimeoutTime" BU_SG_REL_ AVM SG_ 560 TurningSt_right 1000;
BA_REL_ "GenSigTimeoutTime" BU_SG_REL_ LCDA1 SG_ 560 TurningSt_right 1000;
BA_REL_ "GenSigTimeoutTime" BU_SG_REL_ LCDA2 SG_ 560 TurningSt_right 1000;
BA_REL_ "GenSigTimeoutTime" BU_SG_REL_ CDS1 SG_ 560 TurningLightCmd_Left 1000;
BA_REL_ "GenSigTimeoutTime" BU_SG_REL_ IRC SG_ 560 TurningLightCmd_Left 1000;
BA_REL_ "GenSigTimeoutTime" BU_SG_REL_ DSM SG_ 560 TurningLightCmd_Left 1000;
BA_REL_ "GenSigTimeoutTime" BU_SG_REL_ CDS1 SG_ 560 TurningLightCmd_Right 1000;
BA_REL_ "GenSigTimeoutTime" BU_SG_REL_ IRC SG_ 560 TurningLightCmd_Right 1000;
BA_REL_ "GenSigTimeoutTime" BU_SG_REL_ DSM SG_ 560 TurningLightCmd_Right 1000;
BA_REL_ "GenSigTimeoutTime" BU_SG_REL_ CDS1 SG_ 560 HazardWarningSt 1000;
BA_REL_ "GenSigTimeoutTime" BU_SG_REL_ CDS2 SG_ 560 HazardWarningSt 1000;
BA_REL_ "GenSigTimeoutTime" BU_SG_REL_ ADV SG_ 560 HazardWarningSt 1000;
BA_REL_ "GenSigTimeoutTime" BU_SG_REL_ AVP SG_ 560 HazardWarningSt 1000;
BA_REL_ "GenSigTimeoutTime" BU_SG_REL_ AVM SG_ 560 HazardWarningSt 1000;
BA_REL_ "GenSigTimeoutTime" BU_SG_REL_ DSM SG_ 560 HazardWarningSt 1000;
BA_REL_ "GenSigTimeoutTime" BU_SG_REL_ CDS1 SG_ 560 WMMFaultSt 1000;
BA_REL_ "GenSigTimeoutTime" BU_SG_REL_ CDS2 SG_ 560 WMMFaultSt 1000;
BA_REL_ "GenSigTimeoutTime" BU_SG_REL_ CDS1 SG_ 560 RLSFalutSt 1000;
BA_REL_ "GenSigTimeoutTime" BU_SG_REL_ CDS2 SG_ 560 RLSFalutSt 1000;
BA_REL_ "GenSigTimeoutTime" BU_SG_REL_ ADB1 SG_ 560 RLSFalutSt 1000;
BA_REL_ "GenSigTimeoutTime" BU_SG_REL_ ADB2 SG_ 560 RLSFalutSt 1000;
BA_REL_ "GenSigTimeoutTime" BU_SG_REL_ CDS1 SG_ 560 WiperSt_Front 1000;
BA_REL_ "GenSigTimeoutTime" BU_SG_REL_ CDS2 SG_ 560 WiperSt_Front 1000;
BA_REL_ "GenSigTimeoutTime" BU_SG_REL_ IRC SG_ 560 WiperSt_Front 1000;
BA_REL_ "GenSigTimeoutTime" BU_SG_REL_ CDS1 SG_ 560 WiperSpeed_Front 1000;
BA_REL_ "GenSigTimeoutTime" BU_SG_REL_ CDS2 SG_ 560 WiperSpeed_Front 1000;
BA_REL_ "GenSigTimeoutTime" BU_SG_REL_ CDS2 SG_ 560 IHCConditionReady 1000;
BA_REL_ "GenSigTimeoutTime" BU_SG_REL_ CDS1 SG_ 562 PowerMode 1000;
BA_REL_ "GenSigTimeoutTime" BU_SG_REL_ CDS2 SG_ 562 PowerMode 1000;
BA_REL_ "GenSigTimeoutTime" BU_SG_REL_ ADV SG_ 562 PowerMode 1000;
BA_REL_ "GenSigTimeoutTime" BU_SG_REL_ IRC SG_ 562 PowerMode 1000;
BA_REL_ "GenSigTimeoutTime" BU_SG_REL_ AVP SG_ 562 PowerMode 1000;
BA_REL_ "GenSigTimeoutTime" BU_SG_REL_ AVM SG_ 562 PowerMode 1000;
BA_REL_ "GenSigTimeoutTime" BU_SG_REL_ PDC SG_ 562 PowerMode 1000;
BA_REL_ "GenSigTimeoutTime" BU_SG_REL_ ADB1 SG_ 562 PowerMode 1000;
BA_REL_ "GenSigTimeoutTime" BU_SG_REL_ ADB2 SG_ 562 PowerMode 1000;
BA_REL_ "GenSigTimeoutTime" BU_SG_REL_ HDMAP SG_ 562 PowerMode 1000;
BA_REL_ "GenSigTimeoutTime" BU_SG_REL_ DSM SG_ 562 PowerMode 1000;
BA_REL_ "GenSigTimeoutTime" BU_SG_REL_ LCDA1 SG_ 562 PowerMode 1000;
BA_REL_ "GenSigTimeoutTime" BU_SG_REL_ LCDA2 SG_ 562 PowerMode 1000;
BA_REL_ "GenSigTimeoutTime" BU_SG_REL_ CDS1 SG_ 562 PEPS_CIDLocation 1000;
BA_REL_ "GenSigTimeoutTime" BU_SG_REL_ ADV SG_ 562 PEPS_CIDLocation 1000;
BA_REL_ "GenSigTimeoutTime" BU_SG_REL_ CDS1 SG_ 562 SysSt_PEPS 1000;
BA_REL_ "GenSigTimeoutTime" BU_SG_REL_ ADV SG_ 562 SysSt_PEPS 1000;
BA_REL_ "GenSigTimeoutTime" BU_SG_REL_ CDS1 SG_ 562 PEPS_RKEEngineCmd 1000;
BA_REL_ "GenSigTimeoutTime" BU_SG_REL_ ADV SG_ 562 PEPS_RKEEngineCmd 1000;
BA_REL_ "GenSigTimeoutTime" BU_SG_REL_ CDS1 SG_ 562 ChargePortStatus_DC 1000;
BA_REL_ "GenSigTimeoutTime" BU_SG_REL_ ADV SG_ 562 ChargePortStatus_DC 1000;
BA_REL_ "GenSigTimeoutTime" BU_SG_REL_ CDS1 SG_ 562 ChargePortStatus_AC 1000;
BA_REL_ "GenSigTimeoutTime" BU_SG_REL_ ADV SG_ 562 ChargePortStatus_AC 1000;
BA_REL_ "GenSigTimeoutTime" BU_SG_REL_ CDS1 SG_ 562 AccountID_BCM 1000;
BA_REL_ "GenSigTimeoutTime" BU_SG_REL_ ADV SG_ 562 AccountID_BCM 1000;
BA_REL_ "GenSigTimeoutTime" BU_SG_REL_ CDS1 SG_ 564 EngineHoodSt 1000;
BA_REL_ "GenSigTimeoutTime" BU_SG_REL_ CDS2 SG_ 564 EngineHoodSt 1000;
BA_REL_ "GenSigTimeoutTime" BU_SG_REL_ ADV SG_ 564 EngineHoodSt 1000;
BA_REL_ "GenSigTimeoutTime" BU_SG_REL_ AVP SG_ 564 EngineHoodSt 1000;
BA_REL_ "GenSigTimeoutTime" BU_SG_REL_ AVM SG_ 564 EngineHoodSt 1000;
BA_REL_ "GenSigTimeoutTime" BU_SG_REL_ CDS1 SG_ 564 SunroofSt 1000;
BA_REL_ "GenSigTimeoutTime" BU_SG_REL_ ADV SG_ 564 SunroofSt 1000;
BA_REL_ "GenSigTimeoutTime" BU_SG_REL_ CDS1 SG_ 564 AntiTheftSt 1000;
BA_REL_ "GenSigTimeoutTime" BU_SG_REL_ LCDA1 SG_ 564 AntiTheftSt 1000;
BA_REL_ "GenSigTimeoutTime" BU_SG_REL_ LCDA2 SG_ 564 AntiTheftSt 1000;
BA_REL_ "GenSigTimeoutTime" BU_SG_REL_ CDS1 SG_ 571 RainIntensity 1000;
BA_REL_ "GenSigTimeoutTime" BU_SG_REL_ CDS2 SG_ 571 RainIntensity 1000;
BA_REL_ "GenSigTimeoutTime" BU_SG_REL_ IRC SG_ 571 RainIntensity 1000;
BA_REL_ "GenSigTimeoutTime" BU_SG_REL_ AVP SG_ 571 RainIntensity 1000;
BA_REL_ "GenSigTimeoutTime" BU_SG_REL_ AVM SG_ 571 RainIntensity 1000;
BA_REL_ "GenSigTimeoutTime" BU_SG_REL_ ADB1 SG_ 571 RainIntensity 1000;
BA_REL_ "GenSigTimeoutTime" BU_SG_REL_ ADB2 SG_ 571 RainIntensity 1000;
BA_REL_ "GenSigTimeoutTime" BU_SG_REL_ CDS1 SG_ 571 Brightness_L 1000;
BA_REL_ "GenSigTimeoutTime" BU_SG_REL_ CDS2 SG_ 571 Brightness_L 1000;
BA_REL_ "GenSigTimeoutTime" BU_SG_REL_ IRC SG_ 571 Brightness_L 1000;
BA_REL_ "GenSigTimeoutTime" BU_SG_REL_ AVP SG_ 571 Brightness_L 1000;
BA_REL_ "GenSigTimeoutTime" BU_SG_REL_ AVM SG_ 571 Brightness_L 1000;
BA_REL_ "GenSigTimeoutTime" BU_SG_REL_ ADB1 SG_ 571 Brightness_L 1000;
BA_REL_ "GenSigTimeoutTime" BU_SG_REL_ ADB2 SG_ 571 Brightness_L 1000;
BA_REL_ "GenSigTimeoutTime" BU_SG_REL_ CDS1 SG_ 571 Brightness_H 1000;
BA_REL_ "GenSigTimeoutTime" BU_SG_REL_ CDS2 SG_ 571 Brightness_H 1000;
BA_REL_ "GenSigTimeoutTime" BU_SG_REL_ IRC SG_ 571 Brightness_H 1000;
BA_REL_ "GenSigTimeoutTime" BU_SG_REL_ AVP SG_ 571 Brightness_H 1000;
BA_REL_ "GenSigTimeoutTime" BU_SG_REL_ AVM SG_ 571 Brightness_H 1000;
BA_REL_ "GenSigTimeoutTime" BU_SG_REL_ ADB1 SG_ 571 Brightness_H 1000;
BA_REL_ "GenSigTimeoutTime" BU_SG_REL_ ADB2 SG_ 571 Brightness_H 1000;
BA_REL_ "GenSigTimeoutTime" BU_SG_REL_ CDS1 SG_ 572 TyrePressureWarning_FL 1000;
BA_REL_ "GenSigTimeoutTime" BU_SG_REL_ CDS2 SG_ 572 TyrePressureWarning_FL 1000;
BA_REL_ "GenSigTimeoutTime" BU_SG_REL_ ADV SG_ 572 TyrePressureWarning_FL 1000;
BA_REL_ "GenSigTimeoutTime" BU_SG_REL_ CDS1 SG_ 572 TyrePressureWarning_FR 1000;
BA_REL_ "GenSigTimeoutTime" BU_SG_REL_ CDS2 SG_ 572 TyrePressureWarning_FR 1000;
BA_REL_ "GenSigTimeoutTime" BU_SG_REL_ ADV SG_ 572 TyrePressureWarning_FR 1000;
BA_REL_ "GenSigTimeoutTime" BU_SG_REL_ CDS1 SG_ 572 TyrePressureWarning_RL 1000;
BA_REL_ "GenSigTimeoutTime" BU_SG_REL_ CDS2 SG_ 572 TyrePressureWarning_RL 1000;
BA_REL_ "GenSigTimeoutTime" BU_SG_REL_ ADV SG_ 572 TyrePressureWarning_RL 1000;
BA_REL_ "GenSigTimeoutTime" BU_SG_REL_ CDS1 SG_ 572 TyrePressureWarning_RR 1000;
BA_REL_ "GenSigTimeoutTime" BU_SG_REL_ CDS2 SG_ 572 TyrePressureWarning_RR 1000;
BA_REL_ "GenSigTimeoutTime" BU_SG_REL_ ADV SG_ 572 TyrePressureWarning_RR 1000;
BA_REL_ "GenSigTimeoutTime" BU_SG_REL_ CDS1 SG_ 572 TyrePressureValue_FL 1000;
BA_REL_ "GenSigTimeoutTime" BU_SG_REL_ CDS2 SG_ 572 TyrePressureValue_FL 1000;
BA_REL_ "GenSigTimeoutTime" BU_SG_REL_ ADV SG_ 572 TyrePressureValue_FL 1000;
BA_REL_ "GenSigTimeoutTime" BU_SG_REL_ CDS1 SG_ 572 TyrePressureValue_FR 1000;
BA_REL_ "GenSigTimeoutTime" BU_SG_REL_ CDS2 SG_ 572 TyrePressureValue_FR 1000;
BA_REL_ "GenSigTimeoutTime" BU_SG_REL_ ADV SG_ 572 TyrePressureValue_FR 1000;
BA_REL_ "GenSigTimeoutTime" BU_SG_REL_ CDS1 SG_ 572 TyrePressureValue_RL 1000;
BA_REL_ "GenSigTimeoutTime" BU_SG_REL_ CDS2 SG_ 572 TyrePressureValue_RL 1000;
BA_REL_ "GenSigTimeoutTime" BU_SG_REL_ ADV SG_ 572 TyrePressureValue_RL 1000;
BA_REL_ "GenSigTimeoutTime" BU_SG_REL_ CDS1 SG_ 572 TyrePressureValue_RR 1000;
BA_REL_ "GenSigTimeoutTime" BU_SG_REL_ CDS2 SG_ 572 TyrePressureValue_RR 1000;
BA_REL_ "GenSigTimeoutTime" BU_SG_REL_ ADV SG_ 572 TyrePressureValue_RR 1000;
BA_REL_ "GenSigTimeoutTime" BU_SG_REL_ CDS1 SG_ 678 GPSTime_Hour 1000;
BA_REL_ "GenSigTimeoutTime" BU_SG_REL_ CDS2 SG_ 678 GPSTime_Hour 1000;
BA_REL_ "GenSigTimeoutTime" BU_SG_REL_ ADV SG_ 678 GPSTime_Hour 1000;
BA_REL_ "GenSigTimeoutTime" BU_SG_REL_ AVP SG_ 678 GPSTime_Hour 1000;
BA_REL_ "GenSigTimeoutTime" BU_SG_REL_ AVM SG_ 678 GPSTime_Hour 1000;
BA_REL_ "GenSigTimeoutTime" BU_SG_REL_ CDS1 SG_ 678 GPSTime_Minute 1000;
BA_REL_ "GenSigTimeoutTime" BU_SG_REL_ CDS2 SG_ 678 GPSTime_Minute 1000;
BA_REL_ "GenSigTimeoutTime" BU_SG_REL_ ADV SG_ 678 GPSTime_Minute 1000;
BA_REL_ "GenSigTimeoutTime" BU_SG_REL_ AVP SG_ 678 GPSTime_Minute 1000;
BA_REL_ "GenSigTimeoutTime" BU_SG_REL_ AVM SG_ 678 GPSTime_Minute 1000;
BA_REL_ "GenSigTimeoutTime" BU_SG_REL_ CDS1 SG_ 678 GPSTime_Second 1000;
BA_REL_ "GenSigTimeoutTime" BU_SG_REL_ CDS2 SG_ 678 GPSTime_Second 1000;
BA_REL_ "GenSigTimeoutTime" BU_SG_REL_ ADV SG_ 678 GPSTime_Second 1000;
BA_REL_ "GenSigTimeoutTime" BU_SG_REL_ AVP SG_ 678 GPSTime_Second 1000;
BA_REL_ "GenSigTimeoutTime" BU_SG_REL_ AVM SG_ 678 GPSTime_Second 1000;
BA_REL_ "GenSigTimeoutTime" BU_SG_REL_ CDS1 SG_ 678 GPSTime_Year 1000;
BA_REL_ "GenSigTimeoutTime" BU_SG_REL_ CDS2 SG_ 678 GPSTime_Year 1000;
BA_REL_ "GenSigTimeoutTime" BU_SG_REL_ ADV SG_ 678 GPSTime_Year 1000;
BA_REL_ "GenSigTimeoutTime" BU_SG_REL_ AVP SG_ 678 GPSTime_Year 1000;
BA_REL_ "GenSigTimeoutTime" BU_SG_REL_ AVM SG_ 678 GPSTime_Year 1000;
BA_REL_ "GenSigTimeoutTime" BU_SG_REL_ CDS1 SG_ 678 GPSTime_Month 1000;
BA_REL_ "GenSigTimeoutTime" BU_SG_REL_ CDS2 SG_ 678 GPSTime_Month 1000;
BA_REL_ "GenSigTimeoutTime" BU_SG_REL_ ADV SG_ 678 GPSTime_Month 1000;
BA_REL_ "GenSigTimeoutTime" BU_SG_REL_ AVP SG_ 678 GPSTime_Month 1000;
BA_REL_ "GenSigTimeoutTime" BU_SG_REL_ AVM SG_ 678 GPSTime_Month 1000;
BA_REL_ "GenSigTimeoutTime" BU_SG_REL_ CDS1 SG_ 678 GPSTime_Day 1000;
BA_REL_ "GenSigTimeoutTime" BU_SG_REL_ CDS2 SG_ 678 GPSTime_Day 1000;
BA_REL_ "GenSigTimeoutTime" BU_SG_REL_ ADV SG_ 678 GPSTime_Day 1000;
BA_REL_ "GenSigTimeoutTime" BU_SG_REL_ AVP SG_ 678 GPSTime_Day 1000;
BA_REL_ "GenSigTimeoutTime" BU_SG_REL_ AVM SG_ 678 GPSTime_Day 1000;
BA_REL_ "GenSigTimeoutTime" BU_SG_REL_ CDS1 SG_ 691 GW_AutoDriveDataRecordStatus 1000;
BA_REL_ "GenSigTimeoutTime" BU_SG_REL_ CDS1 SG_ 691 GW_AutoDriveDataRecordAvailable 1000;
BA_REL_ "GenSigTimeoutTime" BU_SG_REL_ CDS1 SG_ 688 GW_RemoteVehicleMode 1000;
BA_REL_ "GenSigTimeoutTime" BU_SG_REL_ CDS2 SG_ 688 GW_RemoteVehicleMode 1000;
BA_REL_ "GenSigTimeoutTime" BU_SG_REL_ ADV SG_ 688 GW_RemoteVehicleMode 1000;
BA_REL_ "GenSigTimeoutTime" BU_SG_REL_ IRC SG_ 688 GW_RemoteVehicleMode 1000;
BA_REL_ "GenSigTimeoutTime" BU_SG_REL_ AVP SG_ 688 GW_RemoteVehicleMode 1000;
BA_REL_ "GenSigTimeoutTime" BU_SG_REL_ AVM SG_ 688 GW_RemoteVehicleMode 1000;
BA_REL_ "GenSigTimeoutTime" BU_SG_REL_ PDC SG_ 688 GW_RemoteVehicleMode 1000;
BA_REL_ "GenSigTimeoutTime" BU_SG_REL_ HDMAP SG_ 688 GW_RemoteVehicleMode 1000;
BA_REL_ "GenSigTimeoutTime" BU_SG_REL_ DSM SG_ 688 GW_RemoteVehicleMode 1000;
BA_REL_ "GenSigTimeoutTime" BU_SG_REL_ CDS1 SG_ 688 GW_OTAMode 1000;
BA_REL_ "GenSigTimeoutTime" BU_SG_REL_ CDS2 SG_ 688 GW_OTAMode 1000;
BA_REL_ "GenSigTimeoutTime" BU_SG_REL_ ADV SG_ 688 GW_OTAMode 1000;
BA_REL_ "GenSigTimeoutTime" BU_SG_REL_ IRC SG_ 688 GW_OTAMode 1000;
BA_REL_ "GenSigTimeoutTime" BU_SG_REL_ AVP SG_ 688 GW_OTAMode 1000;
BA_REL_ "GenSigTimeoutTime" BU_SG_REL_ AVM SG_ 688 GW_OTAMode 1000;
BA_REL_ "GenSigTimeoutTime" BU_SG_REL_ PDC SG_ 688 GW_OTAMode 1000;
BA_REL_ "GenSigTimeoutTime" BU_SG_REL_ ADB1 SG_ 688 GW_OTAMode 1000;
BA_REL_ "GenSigTimeoutTime" BU_SG_REL_ ADB2 SG_ 688 GW_OTAMode 1000;
BA_REL_ "GenSigTimeoutTime" BU_SG_REL_ HDMAP SG_ 688 GW_OTAMode 1000;
BA_REL_ "GenSigTimeoutTime" BU_SG_REL_ DSM SG_ 688 GW_OTAMode 1000;
BA_REL_ "GenSigTimeoutTime" BU_SG_REL_ Fradar SG_ 688 GW_OTAMode 1000;
BA_REL_ "GenSigTimeoutTime" BU_SG_REL_ LCDA1 SG_ 688 GW_OTAMode 1000;
BA_REL_ "GenSigTimeoutTime" BU_SG_REL_ LCDA2 SG_ 688 GW_OTAMode 1000;
BA_REL_ "GenSigTimeoutTime" BU_SG_REL_ CDS1 SG_ 688 GW_DataRecordErrorSt 1000;
BA_REL_ "GenSigTimeoutTime" BU_SG_REL_ CDS1 SG_ 640 Checksum_HU_1 1000;
BA_REL_ "GenSigTimeoutTime" BU_SG_REL_ CDS2 SG_ 640 Checksum_HU_1 1000;
BA_REL_ "GenSigTimeoutTime" BU_SG_REL_ PDC SG_ 640 Checksum_HU_1 1000;
BA_REL_ "GenSigTimeoutTime" BU_SG_REL_ DSM SG_ 640 Checksum_HU_1 1000;
BA_REL_ "GenSigTimeoutTime" BU_SG_REL_ CDS1 SG_ 640 FCWFunctionReq 1000;
BA_REL_ "GenSigTimeoutTime" BU_SG_REL_ CDS2 SG_ 640 FCWFunctionReq 1000;
BA_REL_ "GenSigTimeoutTime" BU_SG_REL_ CDS1 SG_ 640 FCWSensitivitySet 1000;
BA_REL_ "GenSigTimeoutTime" BU_SG_REL_ CDS2 SG_ 640 FCWSensitivitySet 1000;
BA_REL_ "GenSigTimeoutTime" BU_SG_REL_ CDS1 SG_ 640 AEBFunctionReq 1000;
BA_REL_ "GenSigTimeoutTime" BU_SG_REL_ CDS2 SG_ 640 AEBFunctionReq 1000;
BA_REL_ "GenSigTimeoutTime" BU_SG_REL_ CDS2 SG_ 640 DSMFunctionReq 1000;
BA_REL_ "GenSigTimeoutTime" BU_SG_REL_ DSM SG_ 640 DSMFunctionReq 1000;
BA_REL_ "GenSigTimeoutTime" BU_SG_REL_ CDS1 SG_ 640 LDWSensitivitySet 1000;
BA_REL_ "GenSigTimeoutTime" BU_SG_REL_ CDS2 SG_ 640 LDWSensitivitySet 1000;
BA_REL_ "GenSigTimeoutTime" BU_SG_REL_ CDS1 SG_ 640 LDWFunctionReq 1000;
BA_REL_ "GenSigTimeoutTime" BU_SG_REL_ CDS2 SG_ 640 LDWFunctionReq 1000;
BA_REL_ "GenSigTimeoutTime" BU_SG_REL_ CDS1 SG_ 640 LDWModeSet 1000;
BA_REL_ "GenSigTimeoutTime" BU_SG_REL_ CDS2 SG_ 640 LDWModeSet 1000;
BA_REL_ "GenSigTimeoutTime" BU_SG_REL_ CDS1 SG_ 640 TSRFunctionReq 1000;
BA_REL_ "GenSigTimeoutTime" BU_SG_REL_ CDS2 SG_ 640 TSRFunctionReq 1000;
BA_REL_ "GenSigTimeoutTime" BU_SG_REL_ PDC SG_ 640 PDCFunctionReq 1000;
BA_REL_ "GenSigTimeoutTime" BU_SG_REL_ CDS1 SG_ 640 CruiseFunctionReq 1000;
BA_REL_ "GenSigTimeoutTime" BU_SG_REL_ CDS2 SG_ 640 CruiseFunctionReq 1000;
BA_REL_ "GenSigTimeoutTime" BU_SG_REL_ CDS1 SG_ 640 CruiseModeFunctionReq 1000;
BA_REL_ "GenSigTimeoutTime" BU_SG_REL_ CDS2 SG_ 640 CruiseModeFunctionReq 1000;
BA_REL_ "GenSigTimeoutTime" BU_SG_REL_ CDS1 SG_ 640 HU_NaviWorkingSt 1000;
BA_REL_ "GenSigTimeoutTime" BU_SG_REL_ CDS1 SG_ 640 HU_ErrorSt 1000;
BA_REL_ "GenSigTimeoutTime" BU_SG_REL_ CDS1 SG_ 640 VASFunctionReq 1000;
BA_REL_ "GenSigTimeoutTime" BU_SG_REL_ CDS2 SG_ 640 VASFunctionReq 1000;
BA_REL_ "GenSigTimeoutTime" BU_SG_REL_ CDS1 SG_ 640 LiveCounter_HU_1 1000;
BA_REL_ "GenSigTimeoutTime" BU_SG_REL_ CDS2 SG_ 640 LiveCounter_HU_1 1000;
BA_REL_ "GenSigTimeoutTime" BU_SG_REL_ PDC SG_ 640 LiveCounter_HU_1 1000;
BA_REL_ "GenSigTimeoutTime" BU_SG_REL_ DSM SG_ 640 LiveCounter_HU_1 1000;
BA_REL_ "GenSigTimeoutTime" BU_SG_REL_ ADV SG_ 643 Checksum_HU_18 1000;
BA_REL_ "GenSigTimeoutTime" BU_SG_REL_ AVP SG_ 643 Checksum_HU_18 1000;
BA_REL_ "GenSigTimeoutTime" BU_SG_REL_ AVM SG_ 643 Checksum_HU_18 1000;
BA_REL_ "GenSigTimeoutTime" BU_SG_REL_ PDC SG_ 643 Checksum_HU_18 1000;
BA_REL_ "GenSigTimeoutTime" BU_SG_REL_ DSM SG_ 643 Checksum_HU_18 1000;
BA_REL_ "GenSigTimeoutTime" BU_SG_REL_ AVP SG_ 643 HU_BlindSpotFilledFunctionReq 1000;
BA_REL_ "GenSigTimeoutTime" BU_SG_REL_ AVM SG_ 643 HU_BlindSpotFilledFunctionReq 1000;
BA_REL_ "GenSigTimeoutTime" BU_SG_REL_ ADV SG_ 643 HU_BacktrackFunctionReq 1000;
BA_REL_ "GenSigTimeoutTime" BU_SG_REL_ ADV SG_ 643 HU_APASuspendRequest 1000;
BA_REL_ "GenSigTimeoutTime" BU_SG_REL_ PDC SG_ 643 HU_PDCAutoOnFunctionReq 1000;
BA_REL_ "GenSigTimeoutTime" BU_SG_REL_ DSM SG_ 643 HU_FaceID_IVI 1000;
BA_REL_ "GenSigTimeoutTime" BU_SG_REL_ DSM SG_ 643 FaceIDBindFaceReq 1000;
BA_REL_ "GenSigTimeoutTime" BU_SG_REL_ ADV SG_ 643 LiveCounter_HU_18 1000;
BA_REL_ "GenSigTimeoutTime" BU_SG_REL_ AVP SG_ 643 LiveCounter_HU_18 1000;
BA_REL_ "GenSigTimeoutTime" BU_SG_REL_ AVM SG_ 643 LiveCounter_HU_18 1000;
BA_REL_ "GenSigTimeoutTime" BU_SG_REL_ PDC SG_ 643 LiveCounter_HU_18 1000;
BA_REL_ "GenSigTimeoutTime" BU_SG_REL_ DSM SG_ 643 LiveCounter_HU_18 1000;
BA_REL_ "GenSigTimeoutTime" BU_SG_REL_ AVP SG_ 648 CheckSum_HU_5 1000;
BA_REL_ "GenSigTimeoutTime" BU_SG_REL_ AVM SG_ 648 CheckSum_HU_5 1000;
BA_REL_ "GenSigTimeoutTime" BU_SG_REL_ AVP SG_ 648 AVSFunctionReq 1000;
BA_REL_ "GenSigTimeoutTime" BU_SG_REL_ AVM SG_ 648 AVSFunctionReq 1000;
BA_REL_ "GenSigTimeoutTime" BU_SG_REL_ AVP SG_ 648 AVSViewModeReq 1000;
BA_REL_ "GenSigTimeoutTime" BU_SG_REL_ AVM SG_ 648 AVSViewModeReq 1000;
BA_REL_ "GenSigTimeoutTime" BU_SG_REL_ AVP SG_ 648 AVSFunctionExitReq 1000;
BA_REL_ "GenSigTimeoutTime" BU_SG_REL_ AVM SG_ 648 AVSFunctionExitReq 1000;
BA_REL_ "GenSigTimeoutTime" BU_SG_REL_ AVP SG_ 648 AVSMonitoringVideoModeReq 1000;
BA_REL_ "GenSigTimeoutTime" BU_SG_REL_ AVM SG_ 648 AVSMonitoringVideoModeReq 1000;
BA_REL_ "GenSigTimeoutTime" BU_SG_REL_ AVP SG_ 648 DynamicPGSReq 1000;
BA_REL_ "GenSigTimeoutTime" BU_SG_REL_ AVM SG_ 648 DynamicPGSReq 1000;
BA_REL_ "GenSigTimeoutTime" BU_SG_REL_ AVP SG_ 648 MODReq 1000;
BA_REL_ "GenSigTimeoutTime" BU_SG_REL_ AVM SG_ 648 MODReq 1000;
BA_REL_ "GenSigTimeoutTime" BU_SG_REL_ AVP SG_ 648 LanguageSet 1000;
BA_REL_ "GenSigTimeoutTime" BU_SG_REL_ AVM SG_ 648 LanguageSet 1000;
BA_REL_ "GenSigTimeoutTime" BU_SG_REL_ AVP SG_ 648 SwitchScreenResponse_AVS 1000;
BA_REL_ "GenSigTimeoutTime" BU_SG_REL_ AVM SG_ 648 SwitchScreenResponse_AVS 1000;
BA_REL_ "GenSigTimeoutTime" BU_SG_REL_ AVP SG_ 648 AVSViewtypeReq 1000;
BA_REL_ "GenSigTimeoutTime" BU_SG_REL_ AVM SG_ 648 AVSViewtypeReq 1000;
BA_REL_ "GenSigTimeoutTime" BU_SG_REL_ AVP SG_ 648 HU_AVM_RemoteMonitoringSharpness 1000;
BA_REL_ "GenSigTimeoutTime" BU_SG_REL_ AVM SG_ 648 HU_AVM_RemoteMonitoringSharpness 1000;
BA_REL_ "GenSigTimeoutTime" BU_SG_REL_ AVP SG_ 648 HU_AVM_RemoteMonitoringIFrameReq 1000;
BA_REL_ "GenSigTimeoutTime" BU_SG_REL_ AVM SG_ 648 HU_AVM_RemoteMonitoringIFrameReq 1000;
BA_REL_ "GenSigTimeoutTime" BU_SG_REL_ AVP SG_ 648 HU_RemoteMonitoringSt 1000;
BA_REL_ "GenSigTimeoutTime" BU_SG_REL_ AVM SG_ 648 HU_RemoteMonitoringSt 1000;
BA_REL_ "GenSigTimeoutTime" BU_SG_REL_ AVP SG_ 648 LiveCounter_HU_5 1000;
BA_REL_ "GenSigTimeoutTime" BU_SG_REL_ AVM SG_ 648 LiveCounter_HU_5 1000;
BA_REL_ "GenSigTimeoutTime" BU_SG_REL_ ADV SG_ 650 TargetSelectionCenter_X 1000;
BA_REL_ "GenSigTimeoutTime" BU_SG_REL_ AVP SG_ 650 TargetSelectionCenter_X 1000;
BA_REL_ "GenSigTimeoutTime" BU_SG_REL_ AVM SG_ 650 TargetSelectionCenter_X 1000;
BA_REL_ "GenSigTimeoutTime" BU_SG_REL_ ADV SG_ 650 TargetSelection_Area 1000;
BA_REL_ "GenSigTimeoutTime" BU_SG_REL_ AVP SG_ 650 TargetSelection_Area 1000;
BA_REL_ "GenSigTimeoutTime" BU_SG_REL_ AVM SG_ 650 TargetSelection_Area 1000;
BA_REL_ "GenSigTimeoutTime" BU_SG_REL_ ADV SG_ 650 TargetSelectionCenter_Y 1000;
BA_REL_ "GenSigTimeoutTime" BU_SG_REL_ AVP SG_ 650 TargetSelectionCenter_Y 1000;
BA_REL_ "GenSigTimeoutTime" BU_SG_REL_ AVM SG_ 650 TargetSelectionCenter_Y 1000;
BA_REL_ "GenSigTimeoutTime" BU_SG_REL_ ADV SG_ 650 TargetSelectionCenter_Angle 1000;
BA_REL_ "GenSigTimeoutTime" BU_SG_REL_ AVP SG_ 650 TargetSelectionCenter_Angle 1000;
BA_REL_ "GenSigTimeoutTime" BU_SG_REL_ AVM SG_ 650 TargetSelectionCenter_Angle 1000;
BA_REL_ "GenSigTimeoutTime" BU_SG_REL_ ADV SG_ 650 TargetSelection_ParkType 1000;
BA_REL_ "GenSigTimeoutTime" BU_SG_REL_ AVP SG_ 650 TargetSelection_ParkType 1000;
BA_REL_ "GenSigTimeoutTime" BU_SG_REL_ AVM SG_ 650 TargetSelection_ParkType 1000;
BA_REL_ "GenSigTimeoutTime" BU_SG_REL_ ADV SG_ 650 TargetSelection_ParkDirection 1000;
BA_REL_ "GenSigTimeoutTime" BU_SG_REL_ AVP SG_ 650 TargetSelection_ParkDirection 1000;
BA_REL_ "GenSigTimeoutTime" BU_SG_REL_ AVM SG_ 650 TargetSelection_ParkDirection 1000;
BA_REL_ "GenSigTimeoutTime" BU_SG_REL_ ADV SG_ 650 TargetSelection_LineAngle 1000;
BA_REL_ "GenSigTimeoutTime" BU_SG_REL_ AVP SG_ 650 TargetSelection_LineAngle 1000;
BA_REL_ "GenSigTimeoutTime" BU_SG_REL_ AVM SG_ 650 TargetSelection_LineAngle 1000;
BA_REL_ "GenSigTimeoutTime" BU_SG_REL_ ADV SG_ 650 TargetSelection_ConfirmReq 1000;
BA_REL_ "GenSigTimeoutTime" BU_SG_REL_ AVP SG_ 650 TargetSelection_ConfirmReq 1000;
BA_REL_ "GenSigTimeoutTime" BU_SG_REL_ AVM SG_ 650 TargetSelection_ConfirmReq 1000;
BA_REL_ "GenSigTimeoutTime" BU_SG_REL_ ADV SG_ 650 APAFunctionReq 1000;
BA_REL_ "GenSigTimeoutTime" BU_SG_REL_ ADV SG_ 650 ParkInFunctionCancelReq 1000;
BA_REL_ "GenSigTimeoutTime" BU_SG_REL_ ADV SG_ 650 ParkInSlotSearchModeSet 1000;
BA_REL_ "GenSigTimeoutTime" BU_SG_REL_ AVP SG_ 650 ParkInSlotSearchModeSet 1000;
BA_REL_ "GenSigTimeoutTime" BU_SG_REL_ AVM SG_ 650 ParkInSlotSearchModeSet 1000;
BA_REL_ "GenSigTimeoutTime" BU_SG_REL_ ADV SG_ 650 ParkOutDirection 1000;
BA_REL_ "GenSigTimeoutTime" BU_SG_REL_ AVP SG_ 650 ParkOutDirection 1000;
BA_REL_ "GenSigTimeoutTime" BU_SG_REL_ AVM SG_ 650 ParkOutDirection 1000;
BA_REL_ "GenSigTimeoutTime" BU_SG_REL_ ADV SG_ 650 ParkOutFunctionConfirmReq 1000;
BA_REL_ "GenSigTimeoutTime" BU_SG_REL_ ADV SG_ 650 ParkOutFunctionCancelReq 1000;
BA_REL_ "GenSigTimeoutTime" BU_SG_REL_ ADB1 SG_ 650 ADBFunctionReq 1000;
BA_REL_ "GenSigTimeoutTime" BU_SG_REL_ ADB2 SG_ 650 ADBFunctionReq 1000;
BA_REL_ "GenSigTimeoutTime" BU_SG_REL_ ADV SG_ 768 Checksum_BLE_DMH 2000;
BA_REL_ "GenSigTimeoutTime" BU_SG_REL_ ADV SG_ 768 BLE_RemoteCtrlDirectionReq 2000;
BA_REL_ "GenSigTimeoutTime" BU_SG_REL_ ADV SG_ 768 BLE_DMHReq 2000;
BA_REL_ "GenSigTimeoutTime" BU_SG_REL_ ADV SG_ 768 BLE_RemoteCtrlSteeringWheelAngle 2000;
BA_REL_ "GenSigTimeoutTime" BU_SG_REL_ ADV SG_ 768 BLE_RemoteCtrlSteeringWheel_0000 2000;
BA_REL_ "GenSigTimeoutTime" BU_SG_REL_ ADV SG_ 768 BLE__ParkInFunctionCancelReq 2000;
BA_REL_ "GenSigTimeoutTime" BU_SG_REL_ ADV SG_ 768 BLE__ParkOutDirection 2000;
BA_REL_ "GenSigTimeoutTime" BU_SG_REL_ ADV SG_ 768 BLE_ParkOutFunctionConfirmReq 2000;
BA_REL_ "GenSigTimeoutTime" BU_SG_REL_ ADV SG_ 768 BLE_ParkOutFunctionCancelReq 2000;
BA_REL_ "GenSigTimeoutTime" BU_SG_REL_ ADV SG_ 768 BLE_AutoParkFunctionReq 2000;
BA_REL_ "GenSigTimeoutTime" BU_SG_REL_ ADV SG_ 768 BLE_ConnectionSt 2000;
BA_REL_ "GenSigTimeoutTime" BU_SG_REL_ ADV SG_ 768 LiveCounter_BLE_DMH 2000;
BA_REL_ "GenSigTimeoutTime" BU_SG_REL_ ADV SG_ 652 Checksum_HU_Speech_1 1000;
BA_REL_ "GenSigTimeoutTime" BU_SG_REL_ AVP SG_ 652 Checksum_HU_Speech_1 1000;
BA_REL_ "GenSigTimeoutTime" BU_SG_REL_ AVM SG_ 652 Checksum_HU_Speech_1 1000;
BA_REL_ "GenSigTimeoutTime" BU_SG_REL_ PDC SG_ 652 Checksum_HU_Speech_1 1000;
BA_REL_ "GenSigTimeoutTime" BU_SG_REL_ AVP SG_ 652 HU_SpeechReq_AVS 1000;
BA_REL_ "GenSigTimeoutTime" BU_SG_REL_ AVM SG_ 652 HU_SpeechReq_AVS 1000;
BA_REL_ "GenSigTimeoutTime" BU_SG_REL_ AVP SG_ 652 HU_SpeechReq_AVSViewMode 1000;
BA_REL_ "GenSigTimeoutTime" BU_SG_REL_ AVM SG_ 652 HU_SpeechReq_AVSViewMode 1000;
BA_REL_ "GenSigTimeoutTime" BU_SG_REL_ PDC SG_ 652 HU_SpeechReq_PDC 1000;
BA_REL_ "GenSigTimeoutTime" BU_SG_REL_ ADV SG_ 652 HU_SpeechReq_ParkOutTypeReq 1000;
BA_REL_ "GenSigTimeoutTime" BU_SG_REL_ ADV SG_ 652 HU_SpeechReq_APAFunctionReq 1000;
BA_REL_ "GenSigTimeoutTime" BU_SG_REL_ DSM SG_ 652 HU_SpeechReq_DSM 1000;
BA_REL_ "GenSigTimeoutTime" BU_SG_REL_ ADV SG_ 652 HU_SpeechReq_ParkOutFuncReq 1000;
BA_REL_ "GenSigTimeoutTime" BU_SG_REL_ ADV SG_ 652 HU_SpeechReq_ParkInModeReq 1000;
BA_REL_ "GenSigTimeoutTime" BU_SG_REL_ ADV SG_ 652 HU_SpeechReq_ParkInTypeReq 1000;
BA_REL_ "GenSigTimeoutTime" BU_SG_REL_ ADV SG_ 652 LiveCounter_HU_Speech_1 1000;
BA_REL_ "GenSigTimeoutTime" BU_SG_REL_ AVP SG_ 652 LiveCounter_HU_Speech_1 1000;
BA_REL_ "GenSigTimeoutTime" BU_SG_REL_ AVM SG_ 652 LiveCounter_HU_Speech_1 1000;
BA_REL_ "GenSigTimeoutTime" BU_SG_REL_ PDC SG_ 652 LiveCounter_HU_Speech_1 1000;
BA_REL_ "GenSigTimeoutTime" BU_SG_REL_ CDS1 SG_ 656 IndicationSpeed_IC 1000;
BA_REL_ "GenSigTimeoutTime" BU_SG_REL_ CDS2 SG_ 656 IndicationSpeed_IC 1000;
BA_REL_ "GenSigTimeoutTime" BU_SG_REL_ CDS1 SG_ 656 OdometerValue 1000;
BA_REL_ "GenSigTimeoutTime" BU_SG_REL_ CDS2 SG_ 656 OdometerValue 1000;
BA_REL_ "GenSigTimeoutTime" BU_SG_REL_ ADV SG_ 656 OdometerValue 1000;
BA_REL_ "GenSigTimeoutTime" BU_SG_REL_ IRC SG_ 656 OdometerValue 1000;
BA_REL_ "GenSigTimeoutTime" BU_SG_REL_ AVP SG_ 656 OdometerValue 1000;
BA_REL_ "GenSigTimeoutTime" BU_SG_REL_ AVM SG_ 656 OdometerValue 1000;
BA_REL_ "GenSigTimeoutTime" BU_SG_REL_ PDC SG_ 656 OdometerValue 1000;
BA_REL_ "GenSigTimeoutTime" BU_SG_REL_ ADB1 SG_ 656 OdometerValue 1000;
BA_REL_ "GenSigTimeoutTime" BU_SG_REL_ ADB2 SG_ 656 OdometerValue 1000;
BA_REL_ "GenSigTimeoutTime" BU_SG_REL_ HDMAP SG_ 656 OdometerValue 1000;
BA_REL_ "GenSigTimeoutTime" BU_SG_REL_ DSM SG_ 656 OdometerValue 1000;
BA_REL_ "GenSigTimeoutTime" BU_SG_REL_ Fradar SG_ 656 OdometerValue 1000;
BA_REL_ "GenSigTimeoutTime" BU_SG_REL_ LCDA1 SG_ 656 OdometerValue 1000;
BA_REL_ "GenSigTimeoutTime" BU_SG_REL_ LCDA2 SG_ 656 OdometerValue 1000;
BA_REL_ "GenSigTimeoutTime" BU_SG_REL_ CDS1 SG_ 418 Checksum_PEPS_DMH 500;
BA_REL_ "GenSigTimeoutTime" BU_SG_REL_ ADV SG_ 418 Checksum_PEPS_DMH 500;
BA_REL_ "GenSigTimeoutTime" BU_SG_REL_ CDS1 SG_ 418 PEPS_DMHSwitch 500;
BA_REL_ "GenSigTimeoutTime" BU_SG_REL_ ADV SG_ 418 PEPS_DMHSwitch 500;
BA_REL_ "GenSigTimeoutTime" BU_SG_REL_ CDS1 SG_ 418 PEPS_LockSwitch 500;
BA_REL_ "GenSigTimeoutTime" BU_SG_REL_ ADV SG_ 418 PEPS_LockSwitch 500;
BA_REL_ "GenSigTimeoutTime" BU_SG_REL_ CDS1 SG_ 418 PEPS_UnlockSwitch 500;
BA_REL_ "GenSigTimeoutTime" BU_SG_REL_ ADV SG_ 418 PEPS_UnlockSwitch 500;
BA_REL_ "GenSigTimeoutTime" BU_SG_REL_ CDS1 SG_ 418 PEPS_PLGUnlockSwitch 500;
BA_REL_ "GenSigTimeoutTime" BU_SG_REL_ ADV SG_ 418 PEPS_PLGUnlockSwitch 500;
BA_REL_ "GenSigTimeoutTime" BU_SG_REL_ CDS1 SG_ 418 LiveCounter_PEPS_DMH 500;
BA_REL_ "GenSigTimeoutTime" BU_SG_REL_ ADV SG_ 418 LiveCounter_PEPS_DMH 500;
BA_REL_ "GenSigTimeoutTime" BU_SG_REL_ CDS1 SG_ 578 LuggageDoorSt 1000;
BA_REL_ "GenSigTimeoutTime" BU_SG_REL_ ADV SG_ 578 LuggageDoorSt 1000;
BA_REL_ "GenSigTimeoutTime" BU_SG_REL_ IRC SG_ 578 LuggageDoorSt 1000;
BA_REL_ "GenSigTimeoutTime" BU_SG_REL_ AVP SG_ 578 LuggageDoorSt 1000;
BA_REL_ "GenSigTimeoutTime" BU_SG_REL_ AVM SG_ 578 LuggageDoorSt 1000;
BA_REL_ "GenSigTimeoutTime" BU_SG_REL_ CDS1 SG_ 586 DoorLockSt_FL 1000;
BA_REL_ "GenSigTimeoutTime" BU_SG_REL_ ADV SG_ 586 DoorLockSt_FL 1000;
BA_REL_ "GenSigTimeoutTime" BU_SG_REL_ LCDA2 SG_ 586 DoorLockSt_FL 1000;
BA_REL_ "GenSigTimeoutTime" BU_SG_REL_ CDS1 SG_ 586 DoorSt_FL 1000;
BA_REL_ "GenSigTimeoutTime" BU_SG_REL_ CDS2 SG_ 586 DoorSt_FL 1000;
BA_REL_ "GenSigTimeoutTime" BU_SG_REL_ ADV SG_ 586 DoorSt_FL 1000;
BA_REL_ "GenSigTimeoutTime" BU_SG_REL_ AVP SG_ 586 DoorSt_FL 1000;
BA_REL_ "GenSigTimeoutTime" BU_SG_REL_ AVM SG_ 586 DoorSt_FL 1000;
BA_REL_ "GenSigTimeoutTime" BU_SG_REL_ LCDA2 SG_ 586 DoorSt_FL 1000;
BA_REL_ "GenSigTimeoutTime" BU_SG_REL_ CDS1 SG_ 586 DoorWindowSt_FL 1000;
BA_REL_ "GenSigTimeoutTime" BU_SG_REL_ ADV SG_ 586 DoorWindowSt_FL 1000;
BA_REL_ "GenSigTimeoutTime" BU_SG_REL_ LCDA2 SG_ 586 LeftlightFaultSt_LCDA 1000;
BA_REL_ "GenSigTimeoutTime" BU_SG_REL_ CDS1 SG_ 586 MirrorFoldSt_FL 1000;
BA_REL_ "GenSigTimeoutTime" BU_SG_REL_ ADV SG_ 586 MirrorFoldSt_FL 1000;
BA_REL_ "GenSigTimeoutTime" BU_SG_REL_ AVP SG_ 586 MirrorFoldSt_FL 1000;
BA_REL_ "GenSigTimeoutTime" BU_SG_REL_ AVM SG_ 586 MirrorFoldSt_FL 1000;
BA_REL_ "GenSigTimeoutTime" BU_SG_REL_ CDS1 SG_ 588 DoorLockSt_FR 1000;
BA_REL_ "GenSigTimeoutTime" BU_SG_REL_ ADV SG_ 588 DoorLockSt_FR 1000;
BA_REL_ "GenSigTimeoutTime" BU_SG_REL_ LCDA1 SG_ 588 DoorLockSt_FR 1000;
BA_REL_ "GenSigTimeoutTime" BU_SG_REL_ CDS1 SG_ 588 DoorSt_FR 1000;
BA_REL_ "GenSigTimeoutTime" BU_SG_REL_ CDS2 SG_ 588 DoorSt_FR 1000;
BA_REL_ "GenSigTimeoutTime" BU_SG_REL_ ADV SG_ 588 DoorSt_FR 1000;
BA_REL_ "GenSigTimeoutTime" BU_SG_REL_ AVP SG_ 588 DoorSt_FR 1000;
BA_REL_ "GenSigTimeoutTime" BU_SG_REL_ AVM SG_ 588 DoorSt_FR 1000;
BA_REL_ "GenSigTimeoutTime" BU_SG_REL_ LCDA1 SG_ 588 DoorSt_FR 1000;
BA_REL_ "GenSigTimeoutTime" BU_SG_REL_ CDS1 SG_ 588 DoorWindowSt_FR 1000;
BA_REL_ "GenSigTimeoutTime" BU_SG_REL_ ADV SG_ 588 DoorWindowSt_FR 1000;
BA_REL_ "GenSigTimeoutTime" BU_SG_REL_ LCDA1 SG_ 588 RightlightFaultSt_LCDA 1000;
BA_REL_ "GenSigTimeoutTime" BU_SG_REL_ CDS1 SG_ 588 MirrorFoldSt_FR 1000;
BA_REL_ "GenSigTimeoutTime" BU_SG_REL_ ADV SG_ 588 MirrorFoldSt_FR 1000;
BA_REL_ "GenSigTimeoutTime" BU_SG_REL_ AVP SG_ 588 MirrorFoldSt_FR 1000;
BA_REL_ "GenSigTimeoutTime" BU_SG_REL_ AVM SG_ 588 MirrorFoldSt_FR 1000;
BA_REL_ "GenSigTimeoutTime" BU_SG_REL_ CDS1 SG_ 590 DoorLockSt_RL 1000;
BA_REL_ "GenSigTimeoutTime" BU_SG_REL_ ADV SG_ 590 DoorLockSt_RL 1000;
BA_REL_ "GenSigTimeoutTime" BU_SG_REL_ LCDA2 SG_ 590 DoorLockSt_RL 1000;
BA_REL_ "GenSigTimeoutTime" BU_SG_REL_ CDS1 SG_ 590 DoorSt_RL 1000;
BA_REL_ "GenSigTimeoutTime" BU_SG_REL_ CDS2 SG_ 590 DoorSt_RL 1000;
BA_REL_ "GenSigTimeoutTime" BU_SG_REL_ ADV SG_ 590 DoorSt_RL 1000;
BA_REL_ "GenSigTimeoutTime" BU_SG_REL_ AVP SG_ 590 DoorSt_RL 1000;
BA_REL_ "GenSigTimeoutTime" BU_SG_REL_ AVM SG_ 590 DoorSt_RL 1000;
BA_REL_ "GenSigTimeoutTime" BU_SG_REL_ LCDA2 SG_ 590 DoorSt_RL 1000;
BA_REL_ "GenSigTimeoutTime" BU_SG_REL_ CDS1 SG_ 590 DoorWindowSt_RL 1000;
BA_REL_ "GenSigTimeoutTime" BU_SG_REL_ ADV SG_ 590 DoorWindowSt_RL 1000;
BA_REL_ "GenSigTimeoutTime" BU_SG_REL_ CDS1 SG_ 591 DoorLockSt_RR 1000;
BA_REL_ "GenSigTimeoutTime" BU_SG_REL_ ADV SG_ 591 DoorLockSt_RR 1000;
BA_REL_ "GenSigTimeoutTime" BU_SG_REL_ LCDA1 SG_ 591 DoorLockSt_RR 1000;
BA_REL_ "GenSigTimeoutTime" BU_SG_REL_ CDS1 SG_ 591 DoorSt_RR 1000;
BA_REL_ "GenSigTimeoutTime" BU_SG_REL_ CDS2 SG_ 591 DoorSt_RR 1000;
BA_REL_ "GenSigTimeoutTime" BU_SG_REL_ ADV SG_ 591 DoorSt_RR 1000;
BA_REL_ "GenSigTimeoutTime" BU_SG_REL_ AVP SG_ 591 DoorSt_RR 1000;
BA_REL_ "GenSigTimeoutTime" BU_SG_REL_ AVM SG_ 591 DoorSt_RR 1000;
BA_REL_ "GenSigTimeoutTime" BU_SG_REL_ LCDA1 SG_ 591 DoorSt_RR 1000;
BA_REL_ "GenSigTimeoutTime" BU_SG_REL_ CDS1 SG_ 591 DoorWindowSt_RR 1000;
BA_REL_ "GenSigTimeoutTime" BU_SG_REL_ ADV SG_ 591 DoorWindowSt_RR 1000;
BA_REL_ "GenSigTimeoutTime" BU_SG_REL_ ADV SG_ 528 ECAS_ErrorStatus 1000;
BA_REL_ "GenSigTimeoutTime" BU_SG_REL_ ADV SG_ 528 ECAS_ActionState 1000;
BA_REL_ "GenSigTimeoutTime" BU_SG_REL_ AVP SG_ 528 ECAS_ActionState 1000;
BA_REL_ "GenSigTimeoutTime" BU_SG_REL_ AVM SG_ 528 ECAS_ActionState 1000;
BA_REL_ "GenSigTimeoutTime" BU_SG_REL_ ADV SG_ 528 ECAS_RequestLevel 1000;
BA_REL_ "GenSigTimeoutTime" BU_SG_REL_ ADV SG_ 528 ECAS_ActualLevel 1000;
BA_REL_ "GenSigTimeoutTime" BU_SG_REL_ AVP SG_ 528 ECAS_ActualLevel 1000;
BA_REL_ "GenSigTimeoutTime" BU_SG_REL_ AVM SG_ 528 ECAS_ActualLevel 1000;
BA_REL_ "GenSigTimeoutTime" BU_SG_REL_ ADV SG_ 528 ECAS_HeightChangeFailureTip 1000;
BA_REL_ "GenSigTimeoutTime" BU_SG_REL_ ADV SG_ 528 ECAS_ReductionLevelSt 1000;
BA_REL_ "GenSigTimeoutTime" BU_SG_REL_ ADV SG_ 432 ECAS_Height_FL 500;
BA_REL_ "GenSigTimeoutTime" BU_SG_REL_ AVP SG_ 432 ECAS_Height_FL 500;
BA_REL_ "GenSigTimeoutTime" BU_SG_REL_ AVM SG_ 432 ECAS_Height_FL 500;
BA_REL_ "GenSigTimeoutTime" BU_SG_REL_ PDC SG_ 432 ECAS_Height_FL 500;
BA_REL_ "GenSigTimeoutTime" BU_SG_REL_ ADV SG_ 432 ECAS_Height_FR 500;
BA_REL_ "GenSigTimeoutTime" BU_SG_REL_ AVP SG_ 432 ECAS_Height_FR 500;
BA_REL_ "GenSigTimeoutTime" BU_SG_REL_ AVM SG_ 432 ECAS_Height_FR 500;
BA_REL_ "GenSigTimeoutTime" BU_SG_REL_ PDC SG_ 432 ECAS_Height_FR 500;
BA_REL_ "GenSigTimeoutTime" BU_SG_REL_ ADV SG_ 432 ECAS_Height_RL 500;
BA_REL_ "GenSigTimeoutTime" BU_SG_REL_ AVP SG_ 432 ECAS_Height_RL 500;
BA_REL_ "GenSigTimeoutTime" BU_SG_REL_ AVM SG_ 432 ECAS_Height_RL 500;
BA_REL_ "GenSigTimeoutTime" BU_SG_REL_ PDC SG_ 432 ECAS_Height_RL 500;
BA_REL_ "GenSigTimeoutTime" BU_SG_REL_ ADV SG_ 432 ECAS_Height_RR 500;
BA_REL_ "GenSigTimeoutTime" BU_SG_REL_ AVP SG_ 432 ECAS_Height_RR 500;
BA_REL_ "GenSigTimeoutTime" BU_SG_REL_ AVM SG_ 432 ECAS_Height_RR 500;
BA_REL_ "GenSigTimeoutTime" BU_SG_REL_ PDC SG_ 432 ECAS_Height_RR 500;
BA_REL_ "GenSigTimeoutTime" BU_SG_REL_ Gateway SG_ 597 HighbeamSt_FL_ADB 1000;
BA_REL_ "GenSigTimeoutTime" BU_SG_REL_ Gateway SG_ 597 HighbeamFaultSt_FL_ADB 1000;
BA_REL_ "GenSigTimeoutTime" BU_SG_REL_ Gateway SG_ 597 ADBL_FunctionInd 1000;
BA_REL_ "GenSigTimeoutTime" BU_SG_REL_ Gateway SG_ 597 ADBL_Errorstatus 1000;
BA_REL_ "GenSigTimeoutTime" BU_SG_REL_ ADB2 SG_ 597 ADBL_Errorstatus 1000;
BA_REL_ "GenSigTimeoutTime" BU_SG_REL_ Gateway SG_ 597 ADBL_Status 1000;
BA_REL_ "GenSigTimeoutTime" BU_SG_REL_ Gateway SG_ 598 HighbeamFaultSt_FR_ADB 1000;
BA_REL_ "GenSigTimeoutTime" BU_SG_REL_ Gateway SG_ 598 ADBR_FunctionInd 1000;
BA_REL_ "GenSigTimeoutTime" BU_SG_REL_ Gateway SG_ 598 ADBR_Errorstatus 1000;
BA_REL_ "GenSigTimeoutTime" BU_SG_REL_ ADB1 SG_ 598 ADBR_Errorstatus 1000;
BA_REL_ "GenSigTimeoutTime" BU_SG_REL_ Gateway SG_ 598 ADBR_Status 1000;
BA_REL_ "GenSigTimeoutTime" BU_SG_REL_ AVP SG_ 539 HDMAP_Status 200;
BA_REL_ "GenSigTimeoutTime" BU_SG_REL_ Gateway SG_ 614 Checksum_DSM_1 1000;
BA_REL_ "GenSigTimeoutTime" BU_SG_REL_ CDS1 SG_ 614 Checksum_DSM_1 1000;
BA_REL_ "GenSigTimeoutTime" BU_SG_REL_ Gateway SG_ 614 DSM_FatigueWarning 1000;
BA_REL_ "GenSigTimeoutTime" BU_SG_REL_ CDS1 SG_ 614 DSM_FatigueWarning 1000;
BA_REL_ "GenSigTimeoutTime" BU_SG_REL_ Gateway SG_ 614 DSM_DistractionWarning 1000;
BA_REL_ "GenSigTimeoutTime" BU_SG_REL_ CDS1 SG_ 614 DSM_DistractionWarning 1000;
BA_REL_ "GenSigTimeoutTime" BU_SG_REL_ Gateway SG_ 614 DSM_IntentionWarning 1000;
BA_REL_ "GenSigTimeoutTime" BU_SG_REL_ CDS1 SG_ 614 DSM_IntentionWarning 1000;
BA_REL_ "GenSigTimeoutTime" BU_SG_REL_ CDS1 SG_ 614 DSM_FunctionalSafetyValidFlag 1000;
BA_REL_ "GenSigTimeoutTime" BU_SG_REL_ Gateway SG_ 614 DSM_AutoDriveDataRecordStatus 1000;
BA_REL_ "GenSigTimeoutTime" BU_SG_REL_ CDS1 SG_ 614 DSM_AutoDriveDataRecordStatus 1000;
BA_REL_ "GenSigTimeoutTime" BU_SG_REL_ Gateway SG_ 614 DSM_AutoDriveDataRecordAvailable 1000;
BA_REL_ "GenSigTimeoutTime" BU_SG_REL_ CDS1 SG_ 614 DSM_AutoDriveDataRecordAvailable 1000;
BA_REL_ "GenSigTimeoutTime" BU_SG_REL_ CDS1 SG_ 614 DSM_AttentionArea 1000;
BA_REL_ "GenSigTimeoutTime" BU_SG_REL_ Gateway SG_ 614 DSM_Blockage 1000;
BA_REL_ "GenSigTimeoutTime" BU_SG_REL_ CDS1 SG_ 614 DSM_Blockage 1000;
BA_REL_ "GenSigTimeoutTime" BU_SG_REL_ Gateway SG_ 614 DSM_FaultSt 1000;
BA_REL_ "GenSigTimeoutTime" BU_SG_REL_ CDS1 SG_ 614 DSM_FaultSt 1000;
BA_REL_ "GenSigTimeoutTime" BU_SG_REL_ Gateway SG_ 614 DSM_Emotion 1000;
BA_REL_ "GenSigTimeoutTime" BU_SG_REL_ CDS1 SG_ 614 DSM_Emotion 1000;
BA_REL_ "GenSigTimeoutTime" BU_SG_REL_ Gateway SG_ 614 DSM_WorkingSt 1000;
BA_REL_ "GenSigTimeoutTime" BU_SG_REL_ Gateway SG_ 614 DSM_DSM_SpeechControlFeedback 1000;
BA_REL_ "GenSigTimeoutTime" BU_SG_REL_ Gateway SG_ 614 DSM_CalibrationStatus 1000;
BA_REL_ "GenSigTimeoutTime" BU_SG_REL_ Gateway SG_ 614 DSM_FaceUnrecognizedTip 1000;
BA_REL_ "GenSigTimeoutTime" BU_SG_REL_ CDS1 SG_ 614 DSM_FaceUnrecognizedTip 1000;
BA_REL_ "GenSigTimeoutTime" BU_SG_REL_ Gateway SG_ 614 Livecounter_DSM_1 1000;
BA_REL_ "GenSigTimeoutTime" BU_SG_REL_ CDS1 SG_ 614 Livecounter_DSM_1 1000;
BA_REL_ "GenSigTimeoutTime" BU_SG_REL_ Gateway SG_ 612 Checksum_DSM_2 1000;
BA_REL_ "GenSigTimeoutTime" BU_SG_REL_ Gateway SG_ 612 DSM_FaceIDBindfaceResult 1000;
BA_REL_ "GenSigTimeoutTime" BU_SG_REL_ Gateway SG_ 612 DSM_AccountBindFaceResult 1000;
BA_REL_ "GenSigTimeoutTime" BU_SG_REL_ Gateway SG_ 612 DSM_FaceFeature 1000;
BA_REL_ "GenSigTimeoutTime" BU_SG_REL_ Gateway SG_ 612 DSM_FaceID_DSM 1000;
BA_REL_ "GenSigTimeoutTime" BU_SG_REL_ Gateway SG_ 612 AccountID_DSM 1000;
BA_REL_ "GenSigTimeoutTime" BU_SG_REL_ Gateway SG_ 612 DSM_EyePosition_X 1000;
BA_REL_ "GenSigTimeoutTime" BU_SG_REL_ Gateway SG_ 612 DSM_EyePosition_Y 1000;
BA_REL_ "GenSigTimeoutTime" BU_SG_REL_ Gateway SG_ 612 DSM_EyePosition_Z 1000;
BA_REL_ "GenSigTimeoutTime" BU_SG_REL_ Gateway SG_ 612 Livecounter_DSM_2 1000;
BA_REL_ "GenSigTimeoutTime" BU_SG_REL_ Gateway SG_ 618 Checksum_FMradar_1 1000;
BA_REL_ "GenSigTimeoutTime" BU_SG_REL_ Gateway SG_ 618 FMradar_FCTA_status 1000;
BA_REL_ "GenSigTimeoutTime" BU_SG_REL_ Gateway SG_ 618 FMradar_FCTB_status 1000;
BA_REL_ "GenSigTimeoutTime" BU_SG_REL_ Gateway SG_ 618 FMradar_FCTA_Warning_Left 1000;
BA_REL_ "GenSigTimeoutTime" BU_SG_REL_ Gateway SG_ 618 FMradar_FCTB_BrakeReq 1000;
BA_REL_ "GenSigTimeoutTime" BU_SG_REL_ Gateway SG_ 618 FMradar_failure_status 1000;
BA_REL_ "GenSigTimeoutTime" BU_SG_REL_ Gateway SG_ 618 FMradar_Blockage_status 1000;
BA_REL_ "GenSigTimeoutTime" BU_SG_REL_ Gateway SG_ 618 FMradar_calibrated_status 1000;
BA_REL_ "GenSigTimeoutTime" BU_SG_REL_ Gateway SG_ 618 FMradar_FCTA_Warning_Right 1000;
BA_REL_ "GenSigTimeoutTime" BU_SG_REL_ Gateway SG_ 618 Livecounter_FMradar_1 1000;
BA_REL_ "GenSigTimeoutTime" BU_SG_REL_ Gateway SG_ 619 Checksum_FSradar_1 1000;
BA_REL_ "GenSigTimeoutTime" BU_SG_REL_ Gateway SG_ 619 FSradar_Blockage_status 1000;
BA_REL_ "GenSigTimeoutTime" BU_SG_REL_ Gateway SG_ 619 Livecounter_FSradar_1 1000;
BA_REL_ "GenSigTimeoutTime" BU_SG_REL_ Gateway SG_ 616 Checksum_LCDA_1 1000;
BA_REL_ "GenSigTimeoutTime" BU_SG_REL_ AVP SG_ 616 Checksum_LCDA_1 1000;
BA_REL_ "GenSigTimeoutTime" BU_SG_REL_ AVM SG_ 616 Checksum_LCDA_1 1000;
BA_REL_ "GenSigTimeoutTime" BU_SG_REL_ Gateway SG_ 616 LCDA_ErrorSt_LCDA 1000;
BA_REL_ "GenSigTimeoutTime" BU_SG_REL_ Gateway SG_ 616 LCDA_WarningCmd_LCDA_Left 1000;
BA_REL_ "GenSigTimeoutTime" BU_SG_REL_ Gateway SG_ 616 LCDA_WarningCmd_LCDA_Right 1000;
BA_REL_ "GenSigTimeoutTime" BU_SG_REL_ Gateway SG_ 616 LCDA_WorkingSt_RCW 1000;
BA_REL_ "GenSigTimeoutTime" BU_SG_REL_ Gateway SG_ 616 LCDA_WarningCmd_RCTA_left 1000;
BA_REL_ "GenSigTimeoutTime" BU_SG_REL_ AVP SG_ 616 LCDA_WarningCmd_RCTA_left 1000;
BA_REL_ "GenSigTimeoutTime" BU_SG_REL_ AVM SG_ 616 LCDA_WarningCmd_RCTA_left 1000;
BA_REL_ "GenSigTimeoutTime" BU_SG_REL_ Gateway SG_ 616 LCDA_BuzzerCmd_RCTA_left 1000;
BA_REL_ "GenSigTimeoutTime" BU_SG_REL_ Gateway SG_ 616 LCDA_WarningCmd_RCTA_Right 1000;
BA_REL_ "GenSigTimeoutTime" BU_SG_REL_ AVP SG_ 616 LCDA_WarningCmd_RCTA_Right 1000;
BA_REL_ "GenSigTimeoutTime" BU_SG_REL_ AVM SG_ 616 LCDA_WarningCmd_RCTA_Right 1000;
BA_REL_ "GenSigTimeoutTime" BU_SG_REL_ Gateway SG_ 616 LCDA_BuzzerCmd_RCTA_Right 1000;
BA_REL_ "GenSigTimeoutTime" BU_SG_REL_ Gateway SG_ 616 LCDA_WorkingSt_RCTA 1000;
BA_REL_ "GenSigTimeoutTime" BU_SG_REL_ AVP SG_ 616 LCDA_WorkingSt_RCTA 1000;
BA_REL_ "GenSigTimeoutTime" BU_SG_REL_ AVM SG_ 616 LCDA_WorkingSt_RCTA 1000;
BA_REL_ "GenSigTimeoutTime" BU_SG_REL_ Gateway SG_ 616 LCDA_WorkingSt_LCWBSD 1000;
BA_REL_ "GenSigTimeoutTime" BU_SG_REL_ Gateway SG_ 616 LCDA_WorkingSt_RCTABuzzer 1000;
BA_REL_ "GenSigTimeoutTime" BU_SG_REL_ Gateway SG_ 616 LCDA_WarningCmd_DOW_FL 1000;
BA_REL_ "GenSigTimeoutTime" BU_SG_REL_ Gateway SG_ 616 LCDA_WarningCmd_DOW_FR 1000;
BA_REL_ "GenSigTimeoutTime" BU_SG_REL_ Gateway SG_ 616 LCDA_WarningCmd_DOW_RL 1000;
BA_REL_ "GenSigTimeoutTime" BU_SG_REL_ Gateway SG_ 616 LCDA_WarningCmd_DOW_RR 1000;
BA_REL_ "GenSigTimeoutTime" BU_SG_REL_ Gateway SG_ 616 LCDA_WarningCmd_RCW 1000;
BA_REL_ "GenSigTimeoutTime" BU_SG_REL_ Gateway SG_ 616 LCDA_WorkingSt_DOW 1000;
BA_REL_ "GenSigTimeoutTime" BU_SG_REL_ Gateway SG_ 616 LCDA_Blockage_RR 1000;
BA_REL_ "GenSigTimeoutTime" BU_SG_REL_ Gateway SG_ 616 LCDA__BrakeReq_RCTB 1000;
BA_REL_ "GenSigTimeoutTime" BU_SG_REL_ AVP SG_ 616 LCDA__BrakeReq_RCTB 1000;
BA_REL_ "GenSigTimeoutTime" BU_SG_REL_ AVM SG_ 616 LCDA__BrakeReq_RCTB 1000;
BA_REL_ "GenSigTimeoutTime" BU_SG_REL_ Gateway SG_ 616 LCDA_WorkingSt_RCTB 1000;
BA_REL_ "GenSigTimeoutTime" BU_SG_REL_ AVP SG_ 616 LCDA_WorkingSt_RCTB 1000;
BA_REL_ "GenSigTimeoutTime" BU_SG_REL_ AVM SG_ 616 LCDA_WorkingSt_RCTB 1000;
BA_REL_ "GenSigTimeoutTime" BU_SG_REL_ Gateway SG_ 616 LCDA_MisAlign_status 1000;
BA_REL_ "GenSigTimeoutTime" BU_SG_REL_ Gateway SG_ 616 LiveCounter_LCDA_1 1000;
BA_REL_ "GenSigTimeoutTime" BU_SG_REL_ AVP SG_ 616 LiveCounter_LCDA_1 1000;
BA_REL_ "GenSigTimeoutTime" BU_SG_REL_ AVM SG_ 616 LiveCounter_LCDA_1 1000;
VAL_ 457 ACoordinateY_Right 1023 "SNA" ;
VAL_ 457 ACoordinateX_Right 4095 "SNA" ;
VAL_ 457 BCoordinateY_Right 1023 "SNA" ;
VAL_ 457 BCoordinateX_Right 4095 "SNA" ;
VAL_ 458 CCoordinateY_Right 1023 "SNA" ;
VAL_ 458 CCoordinateX_Right 4095 "SNA" ;
VAL_ 458 DCoordinateY_Right 1023 "SNA" ;
VAL_ 458 DCoordinateX_Right 4095 "SNA" ;
VAL_ 455 DistanceValue_RLS 1023 "SNA" ;
VAL_ 455 DistanceValue_RRS 1023 "SNA" ;
VAL_ 455 ParkingSlotDepth_Right 1023 "SNA" ;
VAL_ 388 APS_Slot1_DetectStatus 3 "Parking slot detected using Sensor Fusion" 2 "Parking slot detected using USS only" 1 "Parking slot detected using AVM only" 0 "Not detected" ;
VAL_ 388 APS_Slot1_Info 3 "Reserved" 2 "Obstacle" 1 "No obstacle" 0 "Initial" ;
VAL_ 388 APS_Slot1_ParkType 3 "Backward obilique " 2 "Backward perpendicular" 1 "Parallel" 0 "Initial" ;
VAL_ 388 APS_Slot1_ParkDirection 1 "Left" 0 "Right" ;
VAL_ 388 APS_Slot2_DetectStatus 3 "Parking slot detected using Sensor Fusion" 2 "Parking slot detected using USS only" 1 "Parking slot detected using AVM only" 0 "Not detected" ;
VAL_ 388 APS_Slot2_Info 3 "Reserved" 2 "Obstacle" 1 "No obstacle" 0 "Initial" ;
VAL_ 388 APS_Slot2_ParkType 3 "Backward_obilique " 2 "Backward perpendicular" 1 "Parallel" 0 "Initial" ;
VAL_ 388 APS_Slot2_ParkDirection 1 "Left" 0 "Right" ;
VAL_ 388 APS_Slot3_DetectStatus 3 "Parking slot detected using Sensor Fusion" 2 "Parking slot detected using USS only" 1 "Parking slot detected using AVM only" 0 "Not detected" ;
VAL_ 388 APS_Slot3_Info 3 "Reserved" 2 "Obstacle" 1 "No obstacle" 0 "Initial" ;
VAL_ 388 APS_Slot3_ParkType 3 "Backward_obilique " 2 "Backward perpendicular" 1 "Parallel" 0 "Initial" ;
VAL_ 388 APS_Slot3_ParkDirection 1 "Left" 0 "Right" ;
VAL_ 388 APS_Slot4_DetectStatus 3 "Parking slot detected using Sensor Fusion" 2 "Parking slot detected using USS only" 1 "Parking slot detected using AVM only" 0 "Not detected" ;
VAL_ 388 APS_Slot4_Info 3 "Reserved" 2 "Obstacle" 1 "No obstacle" 0 "Initial" ;
VAL_ 388 APS_Slot4_ParkType 3 "Backward_obilique " 2 "Backward perpendicular" 1 "Parallel" 0 "Initial" ;
VAL_ 388 APS_Slot4_ParkDirection 1 "Left" 0 "Right" ;
VAL_ 388 APS_Slot5_DetectStatus 3 "Parking slot detected using Sensor Fusion" 2 "Parking slot detected using USS only" 1 "Parking slot detected using AVM only" 0 "Not detected" ;
VAL_ 388 APS_Slot5_Info 3 "Reserved" 2 "Obstacle" 1 "No obstacle" 0 "Initial" ;
VAL_ 388 APS_Slot5_ParkType 3 "Backward_obilique " 2 "Backward perpendicular" 1 "Parallel" 0 "Initial" ;
VAL_ 388 APS_Slot5_ParkDirection 1 "Left" 0 "Right" ;
VAL_ 388 APS_Slot6_DetectStatus 3 "Parking slot detected using Sensor Fusion" 2 "Parking slot detected using USS only" 1 "Parking slot detected using AVM only" 0 "Not detected" ;
VAL_ 388 APS_Slot6_Info 3 "Reserved" 2 "Obstacle" 1 "No obstacle" 0 "Initial" ;
VAL_ 388 APS_Slot6_ParkType 3 "Backward_obilique " 2 "Backward perpendicular" 1 "Parallel" 0 "Initial" ;
VAL_ 388 APS_Slot6_ParkDirection 1 "Left" 0 "Right" ;
VAL_ 388 APS_ParkingSlotAvailability 1 "Available" 0 "Not available" ;
VAL_ 390 APS_Slot1CenterPoint_X1 2047 "SNA" ;
VAL_ 390 APS_Slot1CenterPoint_Y1 2047 "SNA" ;
VAL_ 390 APS_Slot1_LineAngle 1023 "SNA" ;
VAL_ 390 APS_Slot1_Length 1023 "SNA" ;
VAL_ 390 APS_Slot1_Width 1023 "SNA" ;
VAL_ 391 APS_Slot2CenterPoint_X1 2047 "SNA" ;
VAL_ 391 APS_Slot2CenterPoint_Y1 2047 "SNA" ;
VAL_ 391 APS_Slot2_LineAngle 1023 "SNA" ;
VAL_ 391 APS_Slot2_Length 1023 "SNA" ;
VAL_ 391 APS_Slot2_Width 1023 "SNA" ;
VAL_ 392 APS_Slot3CenterPoint_X1 2047 "SNA" ;
VAL_ 392 APS_Slot3CenterPoint_Y1 2047 "SNA" ;
VAL_ 392 APS_Slot3_LineAngle 1023 "SNA" ;
VAL_ 392 APS_Slot3_Length 1023 "SNA" ;
VAL_ 392 APS_Slot3_Width 1023 "SNA" ;
VAL_ 393 APS_Slot4CenterPoint_X1 2047 "SNA" ;
VAL_ 393 APS_Slot4CenterPoint_Y1 2047 "SNA" ;
VAL_ 393 APS_Slot4_LineAngle 1023 "SNA" ;
VAL_ 393 APS_Slot4_Length 1023 "SNA" ;
VAL_ 393 APS_Slot4_Width 1023 "SNA" ;
VAL_ 394 APS_Slot5CenterPoint_X1 2047 "SNA" ;
VAL_ 394 APS_Slot5CenterPoint_Y1 2047 "SNA" ;
VAL_ 394 APS_Slot5_LineAngle 1023 "SNA" ;
VAL_ 394 APS_Slot5_Length 1023 "SNA" ;
VAL_ 394 APS_Slot5_Width 1023 "SNA" ;
VAL_ 395 APS_Slot6CenterPoint_X1 2047 "SNA" ;
VAL_ 395 APS_Slot6CenterPoint_Y1 2047 "SNA" ;
VAL_ 395 APS_Slot6_LineAngle 1023 "SNA" ;
VAL_ 395 APS_Slot6_Length 1023 "SNA" ;
VAL_ 395 APS_Slot6_Width 1023 "SNA" ;
VAL_ 384 ADV_PathTracingCenter_X 2047 "SNA" ;
VAL_ 384 ADV_PathTracingCenter_Y 2047 "SNA" ;
VAL_ 384 ADV_PathTracingAngle 1023 "SNA" ;
VAL_ 384 ADV_ShortestDistance 255 "SNA" ;
VAL_ 384 ADV_TotalPathNumber 15 "SNA" ;
VAL_ 384 ADV_CurrentPathNumber 15 "SNA" ;
VAL_ 384 ADV_CurrentDirection 1 "Backward" 0 "Forward" ;
VAL_ 384 ADV_RemainingDistance 127 "SNA" ;
VAL_ 386 ADV_TargetTracingCenter_X 2047 "SNA" ;
VAL_ 386 ADV_TargetTracingCenter_Y 2047 "SNA" ;
VAL_ 386 ADV_TargetTracingAngle 1023 "SNA" ;
VAL_ 546 AmbientTemp 255 "SNA" ;
VAL_ 560 PositionLightSt 1 "On" 0 "Off" ;
VAL_ 560 LowBeamSt 1 "On" 0 "Off" ;
VAL_ 560 LowBeamSt_FL 1 "On" 0 "Off" ;
VAL_ 560 LowBeamSt_FR 1 "On" 0 "Off" ;
VAL_ 560 HighBeamSt 1 "On" 0 "Off" ;
VAL_ 560 HighBeamSt_FL 1 "On" 0 "Off" ;
VAL_ 560 HighBeamSt_FR 1 "On" 0 "Off" ;
VAL_ 560 AutoLightMode 1 "Active" 0 "Inactive" ;
VAL_ 560 TurningSt_Left 1 "Active" 0 "Inactive" ;
VAL_ 560 TurningSt_right 1 "Active" 0 "Inactive" ;
VAL_ 560 TurningLightCmd_Left 1 "On" 0 "Off" ;
VAL_ 560 TurningLightCmd_Right 1 "On" 0 "Off" ;
VAL_ 560 HazardWarningSt 1 "Active" 0 "Inactive" ;
VAL_ 560 WMMFaultSt 1 "Fault" 0 "No fault" ;
VAL_ 560 RLSFalutSt 1 "Fault" 0 "No fault" ;
VAL_ 560 WiperSt_Front 7 "Reserved" 6 "Reserved" 5 "Reserved" 4 "High Speed" 3 "Low Speed" 2 "Interval or auto lever" 1 "Tip" 0 "Off" ;
VAL_ 560 WiperSpeed_Front 7 "60 times/min" 6 "57 times/min" 5 "54 times/min" 4 "51 times/min" 3 "48 times/min" 2 "45 times/min" 1 "42 times/min" 0 "No wipe" ;
VAL_ 560 IHCConditionReady 1 "Ready" 0 "Not Ready" ;
VAL_ 562 PowerMode 15 "Invalid value" 14 "Reserved" 13 "Reserved" 12 "Reserved" 11 "Reserved" 10 "Reserved" 9 "Reserved" 8 "Reserved" 7 "Reserved" 6 "Reserved" 5 "Reserved" 4 "IgnitionOn " 3 "Reserved" 2 "Reserved" 1 "Reserved" 0 "Off" ;
VAL_ 562 PEPS_CIDLocation 7 "Inactive" 6 "Reserved" 5 "Reserved" 4 "CID outside of trunk" 3 "CID outside of door" 2 "CID inside of trunk" 1 "CID inside of car" 0 "Can't find CID" ;
VAL_ 562 SysSt_PEPS 3 "Reserved" 2 "Reserved" 1 "Fault" 0 "No Fault" ;
VAL_ 562 PEPS_RKEEngineCmd 3 "Reserved" 2 "Reserved" 1 "Engine Start" 0 "Inactive" ;
VAL_ 562 ChargePortStatus_DC 1 "Open" 0 "Close" ;
VAL_ 562 ChargePortStatus_AC 1 "Open" 0 "Close" ;
VAL_ 562 AccountID_BCM 15 "SNA" ;
VAL_ 564 EngineHoodSt 1 "Open" 0 "Close" ;
VAL_ 564 SunShadeSt 3 "Invalid value" 2 "Parallel open limit" 1 "Between fully closed and parallel open limit" 0 "Fully closed" ;
VAL_ 564 SunroofSt 7 "Invalid value" 6 "Reserved" 5 "Parallel open half" 4 "Parallel open limit" 3 "Between fully closed and Parallel open limit" 2 "Tilt Open limit" 1 "Between fully closed and tilt open limit" 0 "Fully closed" ;
VAL_ 564 AntiTheftSt 7 "Reserved" 6 "Reserved" 5 "Reserved" 4 "Reserved" 3 "Alarm" 2 "Surveillance" 1 "Engagement" 0 "Idle" ;
VAL_ 571 RainIntensity 15 "SNA" ;
VAL_ 571 Brightness_L 255 "SNA" ;
VAL_ 571 Brightness_H 1023 "SNA" ;
VAL_ 572 TyrePressureWarning_FL 1 "Warning" 0 "No Warning" ;
VAL_ 572 TyrePressureWarning_FR 1 "Warning" 0 "No Warning" ;
VAL_ 572 TyrePressureWarning_RL 1 "Warning" 0 "No Warning" ;
VAL_ 572 TyrePressureWarning_RR 1 "Warning" 0 "No Warning" ;
VAL_ 572 TyrePressureValue_FL 255 "SNA" ;
VAL_ 572 TyrePressureValue_FR 255 "SNA" ;
VAL_ 572 TyrePressureValue_RL 255 "SNA" ;
VAL_ 572 TyrePressureValue_RR 255 "SNA" ;
VAL_ 678 GPSTime_Hour 31 "SNA" ;
VAL_ 678 GPSTime_Minute 63 "SNA" ;
VAL_ 678 GPSTime_Second 63 "SNA" ;
VAL_ 678 GPSTime_Year 127 "SNA" ;
VAL_ 678 GPSTime_Month 15 "SNA" ;
VAL_ 678 GPSTime_Day 127 "SNA" ;
VAL_ 691 GW_AutoDriveDataRecordStatus 3 "Error" 2 "Active" 1 "Standby" 0 "Off" ;
VAL_ 691 GW_AutoDriveDataRecordAvailable 1 "Available" 0 "Not available" ;
VAL_ 688 GW_IgnitionOffTime 4095 "SNA" ;
VAL_ 688 GW_RemoteVehicleMode 1 "Remote Mode" 0 "Normal Mode" ;
VAL_ 688 GW_OTAMode 7 "Reserved" 6 "Reserved" 5 "Reserved" 4 "Reserved" 3 "Reserved" 2 "Reserved" 1 "OTA Mode" 0 "Normal Mode" ;
VAL_ 688 GW_DataRecordErrorSt 1 "Abnormal" 0 "Normal" ;
VAL_ 640 FCWFunctionReq 3 "Reserved" 2 "On" 1 "Off" 0 "Inactive" ;
VAL_ 640 FCWSensitivitySet 3 "High" 2 "Normal" 1 "Low" 0 "Inactive" ;
VAL_ 640 AEBFunctionReq 3 "Reserved" 2 "On" 1 "Off" 0 "Inactive" ;
VAL_ 640 DSMFunctionReq 3 "Reserved" 2 "On" 1 "Off" 0 "Inactive" ;
VAL_ 640 LDWSensitivitySet 3 "High" 2 "Normal" 1 "Low" 0 "Inactive" ;
VAL_ 640 LDWFunctionReq 3 "Reserved" 2 "On" 1 "Off" 0 "Inactive" ;
VAL_ 640 LDWModeSet 3 "LDW+LKA" 2 "LDW+Vibration" 1 "LDW only" 0 "Inactive" ;
VAL_ 640 TSRFunctionReq 3 "Reserved" 2 "On" 1 "Off" 0 "Inactive" ;
VAL_ 640 PDCFunctionReq 3 "Reserved" 2 "On" 1 "Off" 0 "Inactive" ;
VAL_ 640 CruiseFunctionReq 3 "Reserved" 2 "On" 1 "Off" 0 "Inactive" ;
VAL_ 640 CruiseModeFunctionReq 3 "Reserved" 2 "ACC" 1 "SACC" 0 "Inactive" ;
VAL_ 640 HU_NaviWorkingSt 1 "On" 0 "Off" ;
VAL_ 640 HU_ErrorSt 1 "Error" 0 "No Error" ;
VAL_ 640 VASFunctionReq 3 "Reserved" 2 "On" 1 "Off" 0 "Inactive" ;
VAL_ 643 HU_BlindSpotFilledFunctionReq 3 "Reserved" 2 "On" 1 "Off" 0 "Inactive" ;
VAL_ 643 HU_BacktrackFunctionReq 3 "Reserved" 2 "On" 1 "Off" 0 "Inactive" ;
VAL_ 643 HU_ParkingAEBFunctionReq 3 "Reserved" 2 "On" 1 "Off" 0 "Inactive" ;
VAL_ 643 HU_ADVDisclaimerTipConfirm 3 "Disagreed" 2 "Agreed and no need tip next time" 1 "Agreed and need tip nest time " 0 "Inactive" ;
VAL_ 643 HU_APASuspendRequest 3 "Reserved" 2 "Continue request" 1 "Suspend request" 0 "Inactive" ;
VAL_ 643 HU_PDCAutoOnFunctionReq 3 "Reserved" 2 "On" 1 "Off" 0 "Inactive" ;
VAL_ 643 HU_FaceID_IVI 15 "Reserved" 14 "Reserved" 13 "Reserved" 12 "Reserved" 11 "Reserved" 10 "Account 10" 9 "Account 9" 8 "Account 8" 7 "Account 7" 6 "Account 6" 5 "Account 5" 4 "Account 4" 3 "Account 3" 2 "Account 2" 1 "Account 1" 0 "Inactive" ;
VAL_ 643 FaceIDBindFaceReq 3 "Reserved" 2 "Unbind" 1 "Bind" 0 "No request" ;
VAL_ 643 HU_AVPSuspendRequest 3 "Reserved" 2 "Continue request" 1 "Suspend request" 0 "Inactive" ;
VAL_ 643 HU_HPASuspendRequest 3 "Reserved" 2 "Continue request" 1 "Suspend request" 0 "Inactive" ;
VAL_ 643 HU_AVPParkingLotPushFunctionReq 3 "Reserved" 2 "On" 1 "Off" 0 "Inactive" ;
VAL_ 643 HU_HPAFunctionReq 3 "Reserved" 2 "On" 1 "Off" 0 "Inactive" ;
VAL_ 643 HU_AVPHazardWarningFunctionReq 3 "Reserved" 2 "On" 1 "Off" 0 "Inactive" ;
VAL_ 643 HU_HPAHazardWarningFunctionReq 3 "Reserved" 2 "On" 1 "Off" 0 "Inactive" ;
VAL_ 643 HU_AVPTypeReq 3 "Navigation" 2 "AVP OUT" 1 "AVP IN" 0 "Inactive" ;
VAL_ 643 HU_AVPSearchingTypeReq 3 "Reserved" 2 "Auto" 1 "Manual" 0 "Inactive" ;
VAL_ 643 HU_HPATypeReq 3 "Navigation" 2 "HPA OUT" 1 "HPA IN" 0 "Inactive" ;
VAL_ 643 HU_HPASearchingTypeReq 3 "Reserved" 2 "Auto" 1 "Manual" 0 "Inactive" ;
VAL_ 643 HU_HPAParkingLotPushFunctionReq 3 "Reserved" 2 "On" 1 "Off" 0 "Inactive" ;
VAL_ 643 HU_AVPFunctionTipConfirm 3 "3" 2 "2" 1 "1" 0 "Inactive" ;
VAL_ 643 HU_HPAFunctionTipConfirm 3 "3" 2 "2" 1 "1" 0 "Inactive" ;
VAL_ 643 HU_AVPFunctionCancelReq 1 "Active" 0 "Inactive" ;
VAL_ 643 HU_HPAFunctionCancelReq 1 "Active" 0 "Inactive" ;
VAL_ 643 HU_AutoDrivingStyle_Set 7 "Reserved" 6 "Reserved" 5 "Reserved" 4 "Sport" 3 "Aggressive" 2 "Conservative" 1 "Normal" 0 "Inactive" ;
VAL_ 648 AVSFunctionReq 3 "Reserved" 2 "On" 1 "Off" 0 "Inactive" ;
VAL_ 648 AVSViewModeReq 15 "Reserved" 14 "Calibration Mode" 13 "Factoty Mode" 12 "Reserved" 11 "Screen Dragged 3D View" 10 "Rear Rim view" 9 "Front Rim view" 8 "Reserved" 7 "Rear Wide View" 6 "Front Wide View" 5 "Top View and Right View" 4 "Top View and Left View" 3 "Top View and Rear View" 2 "Top View and Front View" 1 "All Top View" 0 "Inactive" ;
VAL_ 648 AVSFunctionExitReq 1 "Active" 0 "Inactive" ;
VAL_ 648 AVSMonitoringVideoModeReq 1 "Request" 0 "No Request" ;
VAL_ 648 DynamicPGSReq 3 "Reserved" 2 "On" 1 "Off" 0 "Inactive" ;
VAL_ 648 MODReq 3 "Reserved" 2 "On" 1 "Off" 0 "Inactive" ;
VAL_ 648 LanguageSet 15 "Reserved" 14 "Reserved" 13 "Reserved" 12 "Reserved" 11 "Reserved" 10 "Reserved" 9 "Reserved" 8 "Reserved" 7 "Reserved" 6 "Russian" 5 "Arabic" 4 "French" 3 "English" 2 "Traditional Chinese" 1 "Simplified Chinese" 0 "None" ;
VAL_ 648 SwitchScreenResponse_AVS 3 "Reserved" 2 "AVS Exit Response" 1 "AVS Enter Response" 0 "Inactive" ;
VAL_ 648 AVSViewtypeReq 3 "Reserved" 2 "3D" 1 "2D" 0 "Inactive" ;
VAL_ 648 HU_AVM_RemoteMonitoringSharpness 3 "Reserved" 2 "HD" 1 "SD" 0 "Inactive" ;
VAL_ 648 HU_AVM_RemoteMonitoringIFrameReq 1 "Request" 0 "No request" ;
VAL_ 648 HU_RemoteMonitoringSt 1 "On" 0 "Off" ;
VAL_ 650 TargetSelectionCenter_X 2047 "SNA" ;
VAL_ 650 TargetSelection_Area 1 "Green Area" 0 "Red Area" ;
VAL_ 650 TargetSelectionCenter_Y 2047 "SNA" ;
VAL_ 650 TargetSelectionCenter_Angle 1023 "SNA" ;
VAL_ 650 TargetSelection_ParkType 7 "Reserved" 6 "Reserved" 5 "Reserved" 4 "Auto" 3 "Backward Oblique " 2 "Backward Perpendicular" 1 "Parallel" 0 "Inactive" ;
VAL_ 650 TargetSelection_ParkDirection 3 "Reserved" 2 "Left" 1 "Right" 0 "Inactive" ;
VAL_ 650 TargetSelection_LineAngle 1023 "SNA" ;
VAL_ 650 TargetSelection_ConfirmReq 1 "Active" 0 "Inactive" ;
VAL_ 650 APAFunctionReq 3 "Parking Out On" 2 "Parking In On" 1 "Parking Off" 0 "Inactive" ;
VAL_ 650 ParkInFunctionCancelReq 1 "Active" 0 "Inactive" ;
VAL_ 650 ParkInSlotSearchModeSet 3 "Reserved" 2 "Manual" 1 "Auto" 0 "Inactive" ;
VAL_ 650 ParkOutDirection 15 "Reserved" 14 "Reserved" 13 "Reserved" 12 "Reserved" 11 "Reserved" 10 "Reserved" 9 "Reserved" 8 "Reserved" 7 "Remote control" 6 "Left Parallel" 5 "Right Parallel" 4 "Left perpendicular" 3 "Rear perpendicular" 2 "Front perpendicular" 1 "Right perpendicular" 0 "No request" ;
VAL_ 650 ParkOutFunctionConfirmReq 1 "Active" 0 "Inactive" ;
VAL_ 650 ParkOutFunctionCancelReq 1 "Active" 0 "Inactive" ;
VAL_ 650 ADBFunctionReq 3 "Reserved" 2 "On" 1 "Off" 0 "Inactive" ;
VAL_ 768 BLE_RemoteCtrlDirectionReq 3 "Reserved" 2 "Backward" 1 "Forward" 0 "No Request" ;
VAL_ 768 BLE_DMHReq 1 "Pressed" 0 "Not pressed" ;
VAL_ 768 BLE_RemoteCtrlSteeringWheelAngle 32767 "SNA" ;
VAL_ 768 BLE_RemoteCtrlSteeringWheel_0000 3 "Reserved" 2 "Right (Negative)" 1 "Left (Positive)" 0 "No Request" ;
VAL_ 768 BLE__ParkInFunctionCancelReq 1 "Active" 0 "Inactive" ;
VAL_ 768 BLE__ParkOutDirection 15 "Reserved" 14 "Reserved" 13 "Reserved" 12 "Reserved" 11 "Reserved" 10 "Reserved" 9 "Reserved" 8 "Reserved" 7 "Remote control" 6 "Left Parallel" 5 "Right Parallel" 4 "Left perpendicular" 3 "Rear perpendicular" 2 "Front perpendicular" 1 "Right perpendicular" 0 "No request" ;
VAL_ 768 BLE_ParkOutFunctionConfirmReq 1 "Active" 0 "Inactive" ;
VAL_ 768 BLE_ParkOutFunctionCancelReq 1 "Active" 0 "Inactive" ;
VAL_ 768 BLE_AutoParkFunctionReq 3 "Reserved" 2 "Stop" 1 "Start" 0 "Inactive" ;
VAL_ 768 BLE_ConnectionSt 1 "Connected" 0 "Not connected" ;
VAL_ 652 HU_SpeechReq_AVS 3 "Reserved" 2 "On" 1 "Off" 0 "Inactive" ;
VAL_ 652 HU_SpeechReq_AVSViewMode 15 "Reserved" 14 "Reserved" 13 "Reserved" 12 "Reserved" 11 "Screen Dragged 3D View" 10 "Rear Rim view" 9 "Front Rim view" 8 "Reserved" 7 "Rear Wide View" 6 "Front Wide View" 5 "Top View and Right View" 4 "Top View and Left View" 3 "Top View and Rear View" 2 "Top View and Front View" 1 "All Top View" 0 "Inactive" ;
VAL_ 652 HU_SpeechReq_PDC 3 "Reserved" 2 "On" 1 "Off" 0 "Inactive" ;
VAL_ 652 HU_SpeechReq_ParkOutTypeReq 7 "Reserved" 6 "Reserved" 5 "Reserved" 4 "Right Parallel" 3 "Left Parallel" 2 "Rear perpendicular" 1 "Front perpendicular" 0 "Inactive" ;
VAL_ 652 HU_SpeechReq_AVPFunctionReq 3 "Reserved" 2 "On" 1 "Off" 0 "Inactive" ;
VAL_ 652 HU_SpeechReq_HPAFunctionReq 3 "Reserved" 2 "On" 1 "Off" 0 "Inactive" ;
VAL_ 652 HU_SpeechReq_APAFunctionReq 3 "Reserved" 2 "On" 1 "Off" 0 "Inactive" ;
VAL_ 652 HU_SpeechReq_VAS 3 "Reserved" 2 "On" 1 "Off" 0 "Inactive" ;
VAL_ 652 HU_SpeechReq_TSR 3 "Reserved" 2 "On" 1 "Off" 0 "Inactive" ;
VAL_ 652 HU_SpeechReq_DSM 3 "Reserved" 2 "On" 1 "Off" 0 "Inactive" ;
VAL_ 652 HU_SpeechReq_ParkOutFuncReq 3 "Reserved" 2 "On" 1 "Off" 0 "Inactive" ;
VAL_ 652 HU_SpeechReq_ParkInModeReq 3 "Reserved" 2 "Manual" 1 "Auto" 0 "Inactive" ;
VAL_ 652 HU_SpeechReq_ParkInTypeReq 7 "Reserved" 6 "Reserved" 5 "Reserved" 4 "Auto" 3 "Oblique" 2 "Perpendicular" 1 "Parallel" 0 "Inactive" ;
VAL_ 656 IndicationSpeed_IC 255 "SNA" ;
VAL_ 656 OdometerValue 33554431 "SNA" ;
VAL_ 418 PEPS_DMHSwitch 1 "Pressed" 0 "Not Pressed" ;
VAL_ 418 PEPS_LockSwitch 1 "Pressed" 0 "Not Pressed" ;
VAL_ 418 PEPS_UnlockSwitch 1 "Pressed" 0 "Not Pressed" ;
VAL_ 418 PEPS_PLGUnlockSwitch 1 "Pressed" 0 "Not Pressed" ;
VAL_ 578 LuggageDoorSt 1 "Open" 0 "Close" ;
VAL_ 586 DoorLockSt_FL 3 "Reserved" 2 "Reserved" 1 "Unlock" 0 "Lock" ;
VAL_ 586 DoorSt_FL 1 "Open" 0 "Close" ;
VAL_ 586 DoorWindowSt_FL 7 "Reserved" 6 "Reserved" 5 "Other" 4 "Ventilation" 3 "bottom" 2 "Middle" 1 "Top" 0 "Unknown" ;
VAL_ 586 LeftlightFaultSt_LCDA 1 "Error" 0 "No Error" ;
VAL_ 586 MirrorFoldSt_FL 3 "Reserved" 2 "Reserved" 1 "Fold" 0 "Unfold" ;
VAL_ 588 DoorLockSt_FR 3 "Reserved" 2 "Reserved" 1 "Unlock" 0 "Lock" ;
VAL_ 588 DoorSt_FR 1 "Open" 0 "Close" ;
VAL_ 588 DoorWindowSt_FR 7 "Reserved" 6 "Reserved" 5 "Other" 4 "Ventilation" 3 "bottom" 2 "Middle" 1 "Top" 0 "Unknown" ;
VAL_ 588 RightlightFaultSt_LCDA 1 "Error" 0 "No Error" ;
VAL_ 588 MirrorFoldSt_FR 3 "Reserved" 2 "Reserved" 1 "Fold" 0 "Unfold" ;
VAL_ 590 DoorLockSt_RL 3 "Reserved" 2 "Reserved" 1 "Unlock" 0 "Lock" ;
VAL_ 590 DoorSt_RL 1 "Open" 0 "Close" ;
VAL_ 590 DoorWindowSt_RL 7 "Reserved" 6 "Reserved" 5 "Other" 4 "Ventilation" 3 "bottom" 2 "Middle" 1 "Top" 0 "Unknown" ;
VAL_ 591 DoorLockSt_RR 3 "Reserved" 2 "Reserved" 1 "Unlock" 0 "Lock" ;
VAL_ 591 DoorSt_RR 1 "Open" 0 "Close" ;
VAL_ 591 DoorWindowSt_RR 7 "Reserved" 6 "Reserved" 5 "Other" 4 "Ventilation" 3 "bottom" 2 "Middle" 1 "Top" 0 "Unknown" ;
VAL_ 528 ECAS_ErrorStatus 3 "In diagnostic mode" 2 "Fault Priority 2" 1 "Fault Priority 1" 0 "No error" ;
VAL_ 528 ECAS_ActionState 3 "Reserved" 2 "Lowering" 1 "Lifting" 0 "Inactive" ;
VAL_ 528 ECAS_RequestLevel 7 "Invalid value" 6 "Reserved" 5 "EntryLoading" 4 "Offroad2" 3 "Offroad1" 2 "Highway" 1 "Dynamic" 0 "Normal" ;
VAL_ 528 ECAS_ActualLevel 7 "Invalid value" 6 "Reserved" 5 "EasyLoading" 4 "Offroad2" 3 "Offroad1" 2 "Highway" 1 "Dynamic" 0 "Normal" ;
VAL_ 528 ECAS_HeightChangeFailureTip 7 "Failsafe mode" 6 "carlift" 5 "door is open" 4 "vehicle in incline road(CSD) or dangerous driving(CDD)" 3 "overheat" 2 "overload" 1 "condition is not satisfy (speed, time, epb)" 0 "Inactive" ;
VAL_ 528 ECAS_ReductionLevelSt 7 "Reserved" 6 "Reserved" 5 "Reserved" 4 "Reserved" 3 "Level control forbbidened" 2 "Normal mode fixed" 1 "Temporary stop" 0 "Full(Normal)" ;
VAL_ 432 ECAS_Height_FL 255 "SNA" ;
VAL_ 432 ECAS_Height_FR 255 "SNA" ;
VAL_ 432 ECAS_Height_RL 255 "SNA" ;
VAL_ 432 ECAS_Height_RR 255 "SNA" ;
VAL_ 529 AxleLoad_Front 4095 "SNA" ;
VAL_ 529 AxleLoad_Rear 4095 "SNA" ;
VAL_ 597 HighbeamSt_FL_ADB 1 "On" 0 "Off" ;
VAL_ 597 HighbeamFaultSt_FL_ADB 1 "Fault" 0 "No Fault" ;
VAL_ 597 ADBL_FunctionInd 1 "On" 0 "Off" ;
VAL_ 597 ADBL_Errorstatus 1 "Error" 0 "No Error" ;
VAL_ 597 ADBL_Status 3 "Active" 2 "Enable" 1 "Standby" 0 "Off" ;
VAL_ 598 HighbeamSt_FR_ADB 1 "On" 0 "Off" ;
VAL_ 598 HighbeamFaultSt_FR_ADB 1 "Fault" 0 "No Fault" ;
VAL_ 598 ADBR_FunctionInd 1 "On" 0 "Off" ;
VAL_ 598 ADBR_Errorstatus 1 "Error" 0 "No Error" ;
VAL_ 598 ADBR_Status 3 "Active" 2 "Enable" 1 "Standby" 0 "Off" ;
VAL_ 539 HDMAP_Status 3 "Internal Failure" 2 "External Failure" 1 "Normal" 0 "Starting" ;
VAL_ 614 DSM_FatigueWarning 3 "Reserved" 2 "Sleep" 1 "Tired" 0 "No warning" ;
VAL_ 614 DSM_DistractionWarning 1 "Warning" 0 "No warning" ;
VAL_ 614 DSM_IntentionWarning 3 "Warning" 2 "Right turning" 1 "Left turning" 0 "No warning" ;
VAL_ 614 DSM_FunctionalSafetyValidFlag 1 "Invalid" 0 "Valid" ;
VAL_ 614 DSM_AutoDriveDataRecordStatus 3 "Error" 2 "Active" 1 "Standby" 0 "Off" ;
VAL_ 614 DSM_AutoDriveDataRecordAvailable 1 "Available" 0 "Not available" ;
VAL_ 614 DSM_AttentionArea 15 "Invalid" 14 "Reserved" 13 "Reserved" 12 "Reserved" 11 "Reserved" 10 "Reserved" 9 "Reserved" 8 "Reserved" 7 "Look Down" 6 "Right Mirror" 5 "Left Mirror" 4 "Front control panel" 3 "Off Road" 2 "On Road" 0 "Inactive" ;
VAL_ 614 DSM_Blockage 1 "Blockage" 0 "No blockage" ;
VAL_ 614 DSM_FaultSt 1 "Error" 0 "No Error" ;
VAL_ 614 DSM_Emotion 15 "Invalid" 14 "Reserved" 13 "Reserved" 12 "Reserved" 11 "Reserved" 10 "Reserved" 9 "Reserved" 8 "Reserved" 7 "Reserved" 6 "Reserved" 5 "SURPRISED" 4 "SAD" 3 "HAPPY" 2 "ANGRY" 1 "Drowsiness" 0 "NEUTRAL" ;
VAL_ 614 DSM_WorkingSt 3 "Reserved" 2 "Active" 1 "Standby" 0 "Off" ;
VAL_ 614 DSM_DSM_SpeechControlFeedback 7 "Reserved" 6 "Reserved" 5 "Reserved" 4 "On Failure" 3 "On Success" 2 "Off Failure" 1 "Off Success" 0 "Inactive" ;
VAL_ 614 DSM_CalibrationStatus 3 "Calibration failed" 2 "Calibrated" 1 "Calibrating" 0 "Not calibrated" ;
VAL_ 614 DSM_FaceUnrecognizedTip 7 "Reserved" 6 "Reserved" 5 "Reserved" 4 "Invalid" 3 "No Driver" 2 "Please take off your sunglasses" 1 "Please take off your mask" 0 "No tip" ;
VAL_ 612 DSM_FaceIDBindfaceResult 7 "Reserved" 6 "Reserved" 5 "Reserved" 4 "Unbind face failed" 3 "Unbind face successful" 2 "Bind face failed" 1 "Bind face successful" 0 "Inactive" ;
VAL_ 612 DSM_AccountBindFaceResult 7 "Reserved" 6 "Reserved" 5 "Reserved" 4 "Unbind face failed" 3 "Unbind face successful" 2 "Bind face failed" 1 "Bind face successful" 0 "Inactive" ;
VAL_ 612 DSM_FaceFeature 15 "Reserved" 14 "Reserved" 13 "Reserved" 12 "Reserved" 11 "Reserved" 10 "Face 10" 9 "Face 9" 8 "Face 8" 7 "Face 7" 6 "Face 6" 5 "Face 5" 4 "Face 4" 3 "Face 3" 2 "Face 2" 1 "Face 1" 0 "Inactive" ;
VAL_ 612 DSM_FaceID_DSM 15 "Reserved" 14 "Reserved" 13 "Reserved" 12 "Reserved" 11 "Reserved" 10 "Account 10" 9 "Account 9" 8 "Account 8" 7 "Account 7" 6 "Account 6" 5 "Account 5" 4 "Account 4" 3 "Account 3" 2 "Account 2" 1 "Account 1" 0 "Inactive" ;
VAL_ 612 AccountID_DSM 15 "SNA" ;
VAL_ 612 DSM_EyePosition_X 255 "SNA" ;
VAL_ 612 DSM_EyePosition_Y 255 "SNA" ;
VAL_ 612 DSM_EyePosition_Z 255 "SNA" ;
VAL_ 618 FMradar_FCTA_status 3 "Failure" 2 "Active" 1 "Passive" 0 "Off" ;
VAL_ 618 FMradar_FCTB_status 3 "Failure" 2 "Active" 1 "Passive" 0 "Off" ;
VAL_ 618 FMradar_FCTA_Warning_Left 3 "Reserved" 2 "Waining level 2" 1 "Waining level 1" 0 "Inactive" ;
VAL_ 618 FMradar_FCTB_BrakeReq 1 "Brake Request" 0 "No Request" ;
VAL_ 618 FMradar_failure_status 1 "Error" 0 "No Error" ;
VAL_ 618 FMradar_Blockage_status 1 "Blockage" 0 "No blockage" ;
VAL_ 618 FMradar_calibrated_status 3 "Reserved" 2 "sensor misalignment detected " 1 "sensor calibrated" 0 "sensor not calibrated" ;
VAL_ 618 FMradar_FCTA_Warning_Right 3 "Reserved" 2 "Waining level 2" 1 "Waining level 1" 0 "Inactive" ;
VAL_ 619 FSradar_Blockage_status 1 "Blockage" 0 "No blockage" ;
VAL_ 616 LCDA_ErrorSt_LCDA 1 "Error" 0 "No error" ;
VAL_ 616 LCDA_WarningCmd_LCDA_Left 3 "Reserved" 2 "Warning level 2" 1 "Warning level 1" 0 "Inactive" ;
VAL_ 616 LCDA_WarningCmd_LCDA_Right 3 "Reserved" 2 "Warning level 2" 1 "Warning level 1" 0 "Inactive" ;
VAL_ 616 LCDA_WorkingSt_RCW 3 "Failure" 2 "Active" 1 "Passive" 0 "Off" ;
VAL_ 616 LCDA_WarningCmd_RCTA_left 3 "Reserved" 2 "Warning level 2" 1 "Warning level 1" 0 "Inactive" ;
VAL_ 616 LCDA_BuzzerCmd_RCTA_left 3 "Reserved" 2 "Warning level 2" 1 "Warning level 1" 0 "Inactive" ;
VAL_ 616 LCDA_WarningCmd_RCTA_Right 3 "Reserved" 2 "Warning level 2" 1 "Warning level 1" 0 "Inactive" ;
VAL_ 616 LCDA_BuzzerCmd_RCTA_Right 3 "Reserved" 2 "Warning level 2" 1 "Warning level 1" 0 "Inactive" ;
VAL_ 616 LCDA_WorkingSt_RCTA 3 "Failure" 2 "Active" 1 "Passive" 0 "Off" ;
VAL_ 616 LCDA_WorkingSt_LCWBSD 3 "Failure" 2 "Active" 1 "Passive" 0 "Off" ;
VAL_ 616 LCDA_WorkingSt_RCTABuzzer 3 "Failure" 2 "Active" 1 "Passive" 0 "Off" ;
VAL_ 616 LCDA_WarningCmd_DOW_FL 3 "Reserved" 2 "Warning level 2" 1 "Warning level 1" 0 "Inactive" ;
VAL_ 616 LCDA_WarningCmd_DOW_FR 3 "Reserved" 2 "Warning level 2" 1 "Warning level 1" 0 "Inactive" ;
VAL_ 616 LCDA_WarningCmd_DOW_RL 3 "Reserved" 2 "Warning level 2" 1 "Warning level 1" 0 "Inactive" ;
VAL_ 616 LCDA_WarningCmd_DOW_RR 3 "Reserved" 2 "Warning level 2" 1 "Warning level 1" 0 "Inactive" ;
VAL_ 616 LCDA_WarningCmd_RCW 3 "Reserved" 2 "Warning level 2" 1 "Warning level 1" 0 "Inactive" ;
VAL_ 616 LCDA_WorkingSt_DOW 3 "Failure" 2 "Active" 1 "Passive" 0 "Off" ;
VAL_ 616 LCDA_Blockage_RR 1 "Blockage" 0 "No Blockage" ;
VAL_ 616 LCDA__BrakeReq_RCTB 1 "Brake Request" 0 "No Request" ;
VAL_ 616 LCDA_WorkingSt_RCTB 3 "Failure" 2 "Active" 1 "Passive" 0 "Off" ;
VAL_ 616 LCDA_MisAlign_status 3 "Reserved" 2 "sensor misalignment detected " 1 "sensor calibrated" 0 "sensor not calibrated" ;
